VERSION ""

NS_ :

BS_:

BU_: PFAF_HS LVMPC_HS DCDC_HS AMP_HS VICM2_HS FICM_HS ARS_HS MCP_B_HS MCP_A_HS ICCM_OBD_HS SAS_HS ACCM_HS VLBS_HS EBCM_OBD_HS EDI_HS HPCC_HS VITM_OBD_HS PTAM_HS OBCM_HS VICM_HS HCP_HS FDCM_HS APPS_HS ICCM_HS EOCM_F_HS GPCM_HS FSCM_ITBC_HS SCM_HS ITBC_HS VCM_HS HMIM_HS FCP_HS VES_HS Dummy_HS MCP_C_HS RWS_HS ONSTAR_HS EPS_HS TestTool_HS MCP_HS BCP_HS ALC_HS AHL_AFL_HS SADS_HS EPB_HS FSCM_HS AFS_HS FCM_HS TCCM_HS RDCM_HS PTO_HS PCM_HS EBCM_HS ACC_HS BCM_HS TCM_HS ECM_HS

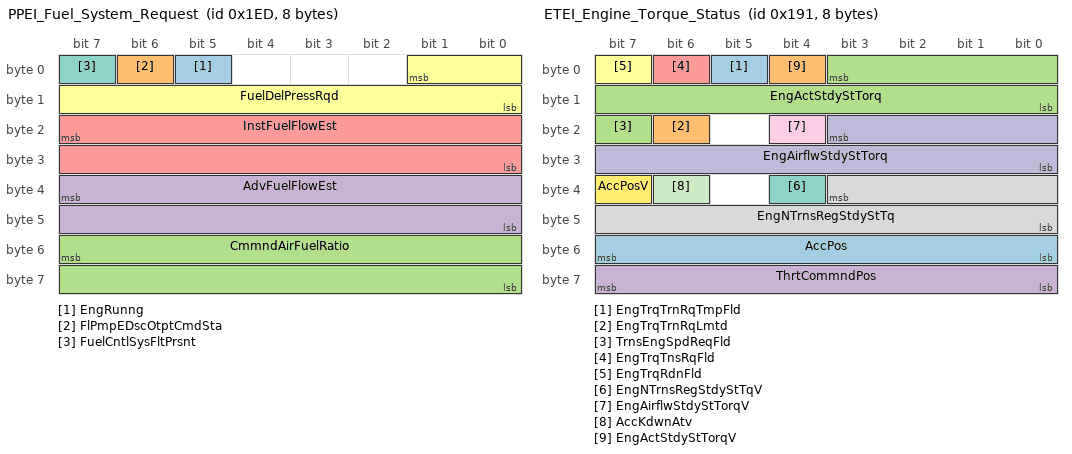
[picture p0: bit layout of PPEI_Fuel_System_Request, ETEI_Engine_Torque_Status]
BO_ 493 PPEI_Fuel_System_Request: 8 ECM_HS
 SG_ EngRunng : 5|1@0+ (1,0) [0|1] ""  PTO_HS,ICCM_OBD_HS,ICCM_HS,FSCM_ITBC_HS,FSCM_HS,AMP_HS
 SG_ FlPmpEDscOtptCmdSta : 6|1@0+ (1,0) [0|1] ""  FICM_HS,ICCM_OBD_HS,ICCM_HS,FSCM_ITBC_HS,FSCM_HS
 SG_ CmmndAirFuelRatio : 55|16@0+ (0.000488281,0) [0|31.999495335] ""  FICM_HS,ICCM_OBD_HS,ICCM_HS,FSCM_ITBC_HS,FSCM_HS
 SG_ AdvFuelFlowEst : 39|16@0+ (0.000976562,0) [0|63.99899067] "grams/s"  ICCM_OBD_HS,ICCM_HS,FSCM_ITBC_HS,FSCM_HS
 SG_ InstFuelFlowEst : 23|16@0+ (0.000976562,0) [0|63.99899067] "grams/s"  VICM_HS,FICM_HS,ICCM_OBD_HS,ICCM_HS,FSCM_ITBC_HS,FSCM_HS
 SG_ FuelDelPressRqd : 1|10@0+ (1,0) [0|1023] "kPa"  ICCM_OBD_HS,ICCM_HS,FSCM_ITBC_HS,FSCM_HS
 SG_ FuelCntlSysFltPrsnt : 7|1@0+ (1,0) [0|1] ""  FICM_HS,ICCM_OBD_HS,ICCM_HS,FSCM_ITBC_HS,FSCM_HS

BO_ 401 ETEI_Engine_Torque_Status: 8 ECM_HS
 SG_ EngTrqTrnRqTmpFld : 5|1@0+ (1,0) [0|1] ""  TCCM_HS,TCM_HS
 SG_ EngTrqTrnRqLmtd : 22|1@0+ (1,0) [0|1] ""  TCCM_HS,TCM_HS
 SG_ TrnsEngSpdReqFld : 23|1@0+ (1,0) [0|1] ""  TCCM_HS,TCM_HS
 SG_ ThrtCommndPos : 63|8@0+ (0.392157,0) [0|100.000035] "%"  TCCM_HS
 SG_ EngTrqTnsRqFld : 6|1@0+ (1,0) [0|1] ""  TCCM_HS,TCM_HS
 SG_ EngTrqRdnFld : 7|1@0+ (1,0) [0|1] ""  TCCM_HS,TCM_HS
 SG_ EngNTrnsRegStdyStTqV : 36|1@0+ (1,0) [0|1] ""  TCCM_HS,TCM_HS
 SG_ EngNTrnsRegStdyStTq : 35|12@0+ (0.5,-848) [-848|1199.5] "Nm"  TCCM_HS,TCM_HS
 SG_ EngAirflwStdyStTorqV : 20|1@0+ (1,0) [0|1] ""  TCCM_HS,TCM_HS
 SG_ EngAirflwStdyStTorq : 19|12@0+ (0.5,-848) [-848|1199.5] "Nm"  TCCM_HS,TCM_HS
 SG_ AccKdwnAtv : 38|1@0+ (1,0) [0|1] ""  TCCM_HS,TCM_HS
 SG_ AccPosV : 39|1@0+ (1,0) [0|1] ""  FSCM_HS,BCP_HS,FICM_HS,TCM_HS
 SG_ AccPos : 55|8@0+ (0.392157,0) [0|100.000035] "%"  FSCM_HS,BCP_HS,FICM_HS,TCM_HS
 SG_ EngActStdyStTorqV : 4|1@0+ (1,0) [0|1] ""  TCCM_HS,TCM_HS
 SG_ EngActStdyStTorq : 3|12@0+ (0.5,-848) [-848|1199.5] "Nm"  TCCM_HS,TCM_HS

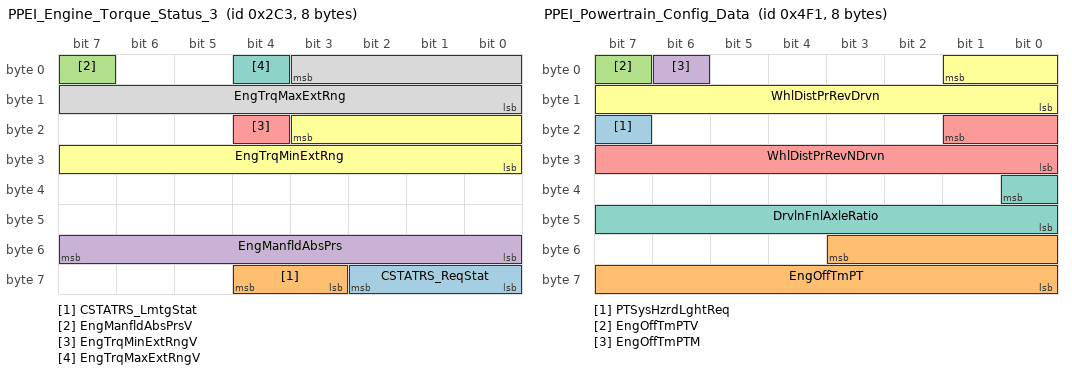
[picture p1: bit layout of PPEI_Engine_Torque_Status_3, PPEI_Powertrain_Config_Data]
BO_ 707 PPEI_Engine_Torque_Status_3: 8 ECM_HS
 SG_ CSTATRS_ReqStat : 58|3@0+ (1,0) [0|7] ""  EBCM_OBD_HS,EBCM_HS
 SG_ CSTATRS_LmtgStat : 60|2@0+ (1,0) [0|3] ""  EBCM_OBD_HS,EBCM_HS
 SG_ EngManfldAbsPrsV : 7|1@0+ (1,0) [0|1] ""  EDI_HS,AMP_HS,BCP_HS,EBCM_OBD_HS,EBCM_HS
 SG_ EngManfldAbsPrs : 55|8@0+ (0.5,0) [0|127.5] "kPa"  EDI_HS,AMP_HS,BCP_HS,EBCM_OBD_HS,EBCM_HS
 SG_ EngTrqMinExtRngV : 20|1@0+ (1,0) [0|1] ""  ACC_HS,EBCM_OBD_HS,EBCM_HS
 SG_ EngTrqMinExtRng : 19|12@0+ (0.5,-848) [-848|1199.5] "Nm"  ACC_HS,EBCM_OBD_HS,EBCM_HS
 SG_ EngTrqMaxExtRngV : 4|1@0+ (1,0) [0|1] ""  TCCM_HS,ACC_HS,EBCM_OBD_HS,EBCM_HS,RDCM_HS
 SG_ EngTrqMaxExtRng : 3|12@0+ (0.5,-848) [-848|1199.5] "Nm"  TCCM_HS,ACC_HS,RDCM_HS,EBCM_OBD_HS,EBCM_HS

BO_ 1265 PPEI_Powertrain_Config_Data: 8 ECM_HS
 SG_ PTSysHzrdLghtReq : 23|1@0+ (1,0) [0|1] ""  BCM_HS
 SG_ EngOffTmPT : 51|12@0+ (0.5,0) [0|2047.5] "min"  EBCM_OBD_HS,EBCM_HS,MCP_HS,TCM_HS
 SG_ EngOffTmPTV : 7|1@0+ (1,0) [0|1] ""  EBCM_OBD_HS,EBCM_HS,MCP_HS,TCM_HS
 SG_ EngOffTmPTM : 6|1@0+ (1,0) [0|1] ""  EBCM_OBD_HS,EBCM_HS,MCP_HS,TCM_HS
 SG_ WhlDistPrRevNDrvn : 17|10@0+ (3,800) [800|3869] "mm"  ICCM_OBD_HS,ICCM_HS,HMIM_HS,VES_HS,EPS_HS,FSCM_ITBC_HS,TCCM_HS,EPB_HS,EOCM_F_HS,EBCM_OBD_HS,EBCM_HS,RDCM_HS
 SG_ WhlDistPrRevDrvn : 1|10@0+ (3,800) [800|3869] "mm"  ICCM_OBD_HS,ICCM_HS,HMIM_HS,VES_HS,EPS_HS,EOCM_F_HS,FSCM_ITBC_HS,ACC_HS,TCCM_HS,EPB_HS,EBCM_OBD_HS,EBCM_HS,BCM_HS,RDCM_HS
 SG_ DrvlnFnlAxleRatio : 32|9@0+ (0.01,2) [2|7.11] ""  PTAM_HS,TCCM_HS,BCM_HS,EBCM_OBD_HS,EBCM_HS

BO_ 417 ETEI_Engine_General_Status: 7 ECM_HS
 SG_ EngCrsCntrlMode : 29|3@0+ (1,0) [0|7] ""  TCM_HS
 SG_ EngPstOxgSnsDgAstRq : 31|1@0+ (1,0) [0|1] ""  TCM_HS
 SG_ CrsCtrlCnstSpdAct : 26|1@0+ (1,0) [0|1] ""  TCM_HS
 SG_ WrmUpShftPtrnRq : 25|1@0+ (1,0) [0|1] ""  TCM_HS
 SG_ EngIdlSpdRdcdRng : 39|8@0+ (8,0) [0|2040] "rpm"  BCP_HS,TCM_HS
 SG_ EngAlwCltAdp : 24|1@0+ (1,0) [0|1] ""  TCM_HS
 SG_ BsTrgtEngIdlSpd : 47|8@0+ (8,0) [0|2040] "rpm"  TCM_HS
 SG_ AccPdlPosPcntFullRngV : 17|1@0+ (1,0) [0|1] ""  TCM_HS
 SG_ AccPdlPosPcntFullRng : 55|8@0+ (0.392157,0) [0|100.000035] "%"  TCM_HS
 SG_ DslPrtFltrIdlRgtnMdReq : 20|1@0+ (1,0) [0|1] ""  TCM_HS
 SG_ DslPartFltrClngAlgActM : 18|1@0+ (1,0) [0|1] ""  TCM_HS
 SG_ DslPartFltrClngAlgAct : 19|1@0+ (1,0) [0|1] ""  TCM_HS
 SG_ EngCylDeactMd : 9|2@0+ (1,0) [0|3] ""  BCP_HS
 SG_ ACCmCltEngd : 13|1@0+ (1,0) [0|1] ""  TCM_HS
 SG_ ParkNeutralSwStatV : 21|1@0+ (1,0) [0|1] ""  TCM_HS
 SG_ ParkNeutralSwStat : 22|1@0+ (1,0) [0|1] ""  TCM_HS
 SG_ EngColdHiIdleActive : 23|1@0+ (1,0) [0|1] ""  TCM_HS
 SG_ EngCyDactTqSmtAct : 6|1@0+ (1,0) [0|1] ""  TCM_HS
 SG_ EngBrkStat : 15|2@0+ (1,0) [0|3] ""  TCM_HS
 SG_ TracCntlSysPwrtrnInhbt : 12|1@0+ (1,0) [0|1] ""  TCM_HS
 SG_ EngMtlProtAtv : 11|1@0+ (1,0) [0|1] ""  TCM_HS
 SG_ EngDgTrqCnvClUnlkRqd : 7|1@0+ (1,0) [0|1] ""  TCM_HS
 SG_ EngCyldrDeactReqd : 10|1@0+ (1,0) [0|1] ""  TCM_HS
 SG_ ETGRReqdGear : 3|4@0+ (1,0) [0|15] ""  TCM_HS
 SG_ ETGRReqType : 5|2@0+ (1,0) [0|3] ""  TCM_HS

BO_ 1233 PPEI_Engine_General_Status_5: 8 ECM_HS
 SG_ EngShtdwnAct : 48|1@0+ (1,0) [0|1] "" Vector__XXX
 SG_ EngShtdwnPndgIO : 49|1@0+ (1,0) [0|1] ""  FCP_HS,ONSTAR_HS,BCM_HS
 SG_ FuelFltChgNwIO : 51|1@0+ (1,0) [0|1] ""  FCP_HS,ONSTAR_HS,BCM_HS
 SG_ PTExPrtclFltrWrn2IO : 50|1@0+ (1,0) [0|1] ""  PTO_HS,FCP_HS,ONSTAR_HS,BCM_HS
 SG_ PTHiElecLdReqd : 52|1@0+ (1,0) [0|1] ""  BCM_HS
 SG_ PTExPrtclFltrWrnIO : 53|1@0+ (1,0) [0|1] ""  PTO_HS,FCP_HS,ONSTAR_HS,BCM_HS
 SG_ AirCndOffIO : 0|1@0+ (1,0) [0|1] ""  BCM_HS
 SG_ DslGlwPlgIO : 55|1@0+ (1,0) [0|1] ""  BCM_HS
 SG_ StgDisIO : 30|1@0+ (1,0) [0|1] ""  BCM_HS
 SG_ RdcdPwrIO : 31|1@0+ (1,0) [0|1] ""  FCP_HS,ONSTAR_HS,BCM_HS
 SG_ FuelTotCap : 27|12@0+ (0.125,0) [0|511.875] "liters"  EDI_HS,LVMPC_HS,BCM_HS
 SG_ FlLvlPctV : 28|1@0+ (1,0) [0|1] ""  EDI_HS,LVMPC_HS,AHL_AFL_HS,PTO_HS,FICM_HS,BCM_HS
 SG_ FlLvlPct : 47|8@0+ (0.392157,0) [0|100.000035] "%"  EDI_HS,LVMPC_HS,PTO_HS,AHL_AFL_HS,FICM_HS,BCM_HS
 SG_ EngWtrInFlIO : 54|1@0+ (1,0) [0|1] ""  FCP_HS,ONSTAR_HS,BCM_HS
 SG_ EngOilTmpV : 7|1@0+ (1,0) [0|1] ""  EDI_HS,LVMPC_HS,EPS_HS,BCM_HS
 SG_ EngOilTmp : 15|8@0+ (1,-40) [-40|215] "deg C"  EDI_HS,LVMPC_HS,EPS_HS,BCM_HS
 SG_ EngOilPrsV : 6|1@0+ (1,0) [0|1] ""  EDI_HS,LVMPC_HS,PTO_HS,BCM_HS
 SG_ EngOilPrsLwIO : 5|1@0+ (1,0) [0|1] ""  PTO_HS,FCP_HS,ONSTAR_HS,BCM_HS
 SG_ EngOilPrs : 23|8@0+ (4,0) [0|1020] "kPa"  EDI_HS,LVMPC_HS,PTO_HS,BCM_HS
 SG_ EngOilLvlLwIO : 4|1@0+ (1,0) [0|1] ""  PTO_HS,FCP_HS,ONSTAR_HS,BCM_HS
 SG_ EngOilChngIO : 3|1@0+ (1,0) [0|1] ""  BCM_HS
 SG_ EngHt_StpEngIO : 1|1@0+ (1,0) [0|1] ""  PTO_HS,FCP_HS,ONSTAR_HS,BCM_HS
 SG_ EngHotFuelEnrchmntIO : 2|1@0+ (1,0) [0|1] ""  FCP_HS,ONSTAR_HS,BCM_HS
 SG_ CkFlFilrCapIO : 29|1@0+ (1,0) [0|1] ""  BCM_HS

BO_ 1217 PPEI_Engine_General_Status_4: 8 ECM_HS
 SG_ LegPstDTCClrDrvCyCm : 40|1@0+ (1,0) [0|1] ""  VICM2_HS,EBCM_OBD_HS,EBCM_HS,VICM_HS,OBCM_HS,VITM_OBD_HS,BCP_HS,ICCM_OBD_HS,ICCM_HS,FSCM_ITBC_HS,FSCM_HS,TCM_HS
 SG_ LegDiagColdStCndMet : 47|1@0+ (1,0) [0|1] ""  VICM2_HS,FICM_HS,ICCM_OBD_HS,ICCM_HS,FSCM_ITBC_HS,FSCM_HS,MCP_HS,EBCM_OBD_HS,EBCM_HS,OBCM_HS,BCP_HS,TCCM_HS,VITM_OBD_HS,VICM_HS,TCM_HS
 SG_ LegDiagColdStCndFltPr : 46|1@0+ (1,0) [0|1] ""  VICM2_HS,FICM_HS,ICCM_OBD_HS,ICCM_HS,FSCM_ITBC_HS,FSCM_HS,MCP_HS,EBCM_OBD_HS,EBCM_HS,OBCM_HS,TCCM_HS,VITM_OBD_HS,VICM_HS,TCM_HS,BCP_HS
 SG_ EngEconMdCmnd : 44|1@0+ (1,0) [0|1] ""  TCM_HS
 SG_ DslExhFldRmngDstHRsV : 41|1@0+ (1,0) [0|1] ""  BCM_HS,FCP_HS,ONSTAR_HS
 SG_ DslExhFldRmngDstHRs : 54|15@0+ (2,0) [0|65534] "km"  BCM_HS,FCP_HS,ONSTAR_HS
 SG_ EngOilHotIO : 45|1@0+ (1,0) [0|1] ""  BCM_HS
 SG_ OAT_PT_EstV : 3|1@0+ (1,0) [0|1] ""  FICM_HS,TCM_HS,TCCM_HS,AHL_AFL_HS,HCP_HS,BCP_HS,RDCM_HS,BCM_HS,EBCM_OBD_HS,EBCM_HS
 SG_ LegDiagStndCndMet : 2|1@0+ (1,0) [0|1] ""  VICM2_HS,FICM_HS,MCP_HS,EBCM_OBD_HS,EBCM_HS,OBCM_HS,VITM_OBD_HS,VICM_HS,BCP_HS,FCP_HS,ONSTAR_HS,ICCM_OBD_HS,ICCM_HS,FSCM_ITBC_HS,FSCM_HS,TCM_HS,TCCM_HS
 SG_ LegDiagStndCndFltPr : 1|1@0+ (1,0) [0|1] ""  VICM2_HS,FICM_HS,MCP_HS,EBCM_OBD_HS,EBCM_HS,VITM_OBD_HS,VICM_HS,OBCM_HS,BCP_HS,ICCM_OBD_HS,ICCM_HS,FSCM_ITBC_HS,FSCM_HS,TCM_HS,TCCM_HS
 SG_ OAT_PT_EstM : 4|1@0+ (1,0) [0|1] ""  FICM_HS,HCP_HS,TCM_HS,TCCM_HS,AHL_AFL_HS,BCP_HS,RDCM_HS,BCM_HS,EBCM_OBD_HS,EBCM_HS
 SG_ OAT_PT_Est : 39|8@0+ (0.5,-40) [-40|87.5] "deg C"  FICM_HS,TCM_HS,TCCM_HS,AHL_AFL_HS,HCP_HS,BCP_HS,RDCM_HS,BCM_HS,EBCM_OBD_HS,EBCM_HS
 SG_ EngWrmUpAch : 0|1@0+ (1,0) [0|1] ""  FICM_HS,MCP_HS,VITM_OBD_HS,EBCM_OBD_HS,EBCM_HS,VICM_HS,OBCM_HS,BCP_HS,ICCM_OBD_HS,ICCM_HS,FSCM_ITBC_HS,FSCM_HS,TCM_HS,TCCM_HS
 SG_ EngIntAirTmpV : 5|1@0+ (1,0) [0|1] ""  EDI_HS,ICCM_OBD_HS,ICCM_HS,RDCM_HS,VICM2_HS,FICM_HS,VICM_HS,EBCM_OBD_HS,EBCM_HS,FCP_HS,ONSTAR_HS,SADS_HS,BCP_HS,TCCM_HS,HCP_HS,BCM_HS
 SG_ EngIntAirTmp : 31|8@0+ (1,-40) [-40|215] "deg C"  EDI_HS,ICCM_OBD_HS,ICCM_HS,RDCM_HS,VICM2_HS,FICM_HS,VICM_HS,EBCM_OBD_HS,EBCM_HS,FCP_HS,ONSTAR_HS,SADS_HS,BCP_HS,TCCM_HS,HCP_HS,BCM_HS
 SG_ EngCltTmpV : 6|1@0+ (1,0) [0|1] ""  EDI_HS,LVMPC_HS,EPS_HS,VCM_HS,FICM_HS,ICCM_OBD_HS,ICCM_HS,FSCM_HS,VICM_HS,FCP_HS,ONSTAR_HS,SADS_HS,HCP_HS,BCP_HS,VICM2_HS,BCM_HS,EBCM_OBD_HS,EBCM_HS
 SG_ EngCltTmp : 23|8@0+ (1,-40) [-40|215] "deg C"  EDI_HS,LVMPC_HS,EPS_HS,VCM_HS,FICM_HS,ICCM_OBD_HS,ICCM_HS,FSCM_HS,VICM_HS,FCP_HS,ONSTAR_HS,SADS_HS,HCP_HS,BCP_HS,VICM2_HS,BCM_HS,EBCM_OBD_HS,EBCM_HS
 SG_ BarPrsAbsV : 7|1@0+ (1,0) [0|1] ""  EDI_HS,VICM_HS,FICM_HS,EBCM_OBD_HS,EBCM_HS,BCP_HS,HCP_HS,ICCM_OBD_HS,ICCM_HS,FSCM_ITBC_HS,FSCM_HS,BCM_HS
 SG_ BarPrsAbs : 15|8@0+ (0.5,0) [0|127.5] "kPa"  EDI_HS,VICM_HS,FICM_HS,EBCM_OBD_HS,EBCM_HS,BCP_HS,HCP_HS,ICCM_OBD_HS,ICCM_HS,FSCM_ITBC_HS,FSCM_HS,BCM_HS

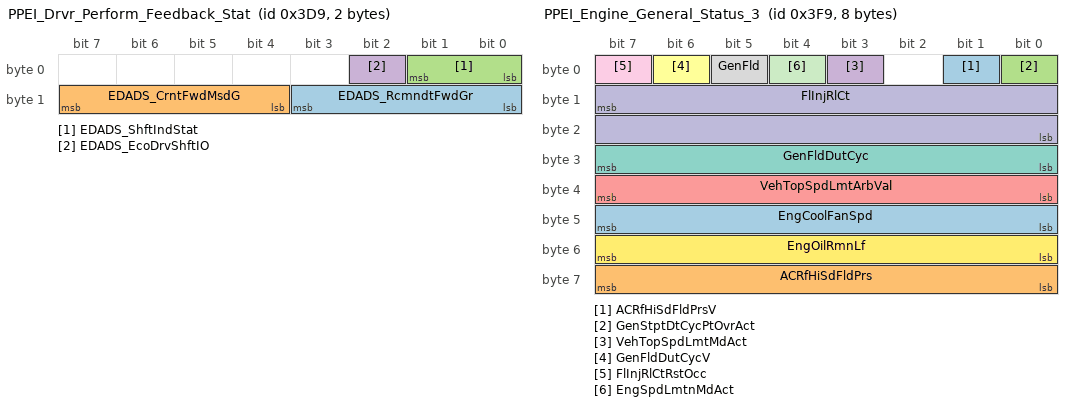
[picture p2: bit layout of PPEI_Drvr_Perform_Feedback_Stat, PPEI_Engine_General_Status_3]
BO_ 985 PPEI_Drvr_Perform_Feedback_Stat: 2 ECM_HS
 SG_ EDADS_RcmndtFwdGr : 11|4@0+ (1,0) [0|15] ""  BCM_HS
 SG_ EDADS_CrntFwdMsdG : 15|4@0+ (1,0) [0|15] ""  BCM_HS
 SG_ EDADS_ShftIndStat : 1|2@0+ (1,0) [0|3] ""  BCM_HS
 SG_ EDADS_EcoDrvShftIO : 2|1@0+ (1,0) [0|1] ""  BCM_HS

BO_ 1017 PPEI_Engine_General_Status_3: 8 ECM_HS
 SG_ ACRfHiSdFldPrsV : 1|1@0+ (1,0) [0|1] ""  VICM2_HS,ICCM_OBD_HS,ICCM_HS,FSCM_HS,VICM_HS,FCP_HS,ONSTAR_HS,BCM_HS
 SG_ ACRfHiSdFldPrs : 63|8@0+ (14,0) [0|3570] "kPaG"  VICM2_HS,ICCM_OBD_HS,ICCM_HS,FSCM_HS,VICM_HS,FCP_HS,ONSTAR_HS,BCM_HS
 SG_ GenStptDtCycPtOvrAct : 0|1@0+ (1,0) [0|1] ""  BCM_HS
 SG_ VehTopSpdLmtMdAct : 3|1@0+ (1,0) [0|1] ""  PTO_HS,BCM_HS
 SG_ VehTopSpdLmtArbVal : 39|8@0+ (2,0) [0|510] "km / h"  PTO_HS,BCM_HS
 SG_ GenFldDutCycV : 6|1@0+ (1,0) [0|1] ""  BCM_HS
 SG_ GenFldDutCyc : 31|8@0+ (0.392157,0) [0|100.000035] "%"  BCM_HS
 SG_ GenFld : 5|1@0+ (1,0) [0|1] ""  FCP_HS,ONSTAR_HS,AFS_HS,BCM_HS
 SG_ FlInjRlCtRstOcc : 7|1@0+ (1,0) [0|1] ""  VICM_HS,FCP_HS,ONSTAR_HS,BCM_HS
 SG_ FlInjRlCt : 15|16@0+ (3.05176E-005,0) [0|1.999970916] "liters"  VICM_HS,FCP_HS,ONSTAR_HS,BCM_HS
 SG_ EngSpdLmtnMdAct : 4|1@0+ (1,0) [0|1] ""  BCM_HS
 SG_ EngOilRmnLf : 55|8@0+ (0.392157,0) [0|100.000035] "%"  BCM_HS
 SG_ EngCoolFanSpd : 47|8@0+ (0.392157,0) [0|100.000035] "%"  VICM_HS,VICM2_HS,ICCM_OBD_HS,ICCM_HS,FSCM_HS,BCM_HS

BO_ 977 PPEI_Engine_General_Status_2: 8 ECM_HS
 SG_ AutoMdSpdLmtStat : 6|2@0+ (1,0) [0|3] ""  BCM_HS
 SG_ FuelFltLifRstPerf : 38|1@0+ (1,0) [0|1] ""  FCP_HS,ONSTAR_HS,BCM_HS
 SG_ SpdLmtrSpdWrngAct : 4|1@0+ (1,0) [0|1] ""  TCM_HS,BCM_HS
 SG_ CrsCntlDrSelSpdAct : 39|1@0+ (1,0) [0|1] ""  BCM_HS
 SG_ ACCmpNrmLdGrdAld : 63|8@0+ (0.1,0) [0|25.5] "dm3/m/s"  BCM_HS
 SG_ ACCompCmnd : 37|1@0+ (1,0) [0|1] ""  VICM2_HS,ICCM_OBD_HS,ICCM_HS,FSCM_HS,BCM_HS
 SG_ EngBstPrsIndV : 23|1@0+ (1,0) [0|1] ""  LVMPC_HS,BCM_HS
 SG_ EngBstPrsInd : 55|8@0+ (0.392157,0) [0|100.000035] "%"  LVMPC_HS,BCM_HS
 SG_ EngOilLifRstPerf : 36|1@0+ (1,0) [0|1] ""  BCM_HS
 SG_ ThrPosV : 7|1@0+ (1,0) [0|1] ""  EDI_HS,ACC_HS,EOCM_F_HS,SADS_HS,BCM_HS
 SG_ ThrPos : 15|8@0+ (0.392157,0) [0|100.000035] "%"  EDI_HS,ACC_HS,EOCM_F_HS,SADS_HS,BCM_HS
 SG_ InstFuelConsmpRate : 35|12@0+ (0.025,0) [0|102.375] "ltrs/hr"  EDI_HS,BCM_HS
 SG_ EngOilStrvtnIO : 21|1@0+ (1,0) [0|1] ""  BCM_HS
 SG_ EngNEmsnsRelMalfAct : 3|1@0+ (1,0) [0|1] ""  BCM_HS
 SG_ EngEmsRelMalfIndReq : 2|3@0+ (1,0) [0|7] ""  BCM_HS
 SG_ EngCstFlCutAct : 22|1@0+ (1,0) [0|1] ""  TCM_HS,VICM_HS,BCP_HS,BCM_HS
 SG_ CrsSpdLmtrDrvSelSpd : 19|12@0+ (0.0625,0) [0|255.9375] "km / h"  TCM_HS,BCM_HS

BO_ 201 PPEI_Engine_General_Status_1: 8 ECM_HS
 SG_ PrsElvtdIdlCntlStat : 49|1@0+ (1,0) [0|1] ""  BCM_HS
 SG_ Eng12vStrtrMtrCmmdOn : 53|1@0+ (1,0) [0|1] ""  BCM_HS,DCDC_HS,RDCM_HS,MCP_C_HS,FICM_HS,TCM_HS,HCP_HS,BCP_HS,MCP_B_HS,MCP_A_HS,EPB_HS,EBCM_OBD_HS,EBCM_HS,TCCM_HS,VES_HS,EPS_HS
 SG_ EngCntrlRunCrnkTrmSt : 52|1@0+ (1,0) [0|1] ""  MCP_C_HS,TCM_HS,EBCM_OBD_HS,EBCM_HS,MCP_B_HS,MCP_A_HS,HCP_HS,BCP_HS,VITM_OBD_HS,VICM_HS,OBCM_HS,FSCM_ITBC_HS,ACCM_HS,VICM2_HS,FSCM_HS,ICCM_OBD_HS,ICCM_HS,FICM_HS
 SG_ EngAirIntBstPrV : 51|1@0+ (1,0) [0|1] ""  EDI_HS,LVMPC_HS,FICM_HS,BCM_HS
 SG_ EngAirIntBstPr : 63|8@0- (1,0) [-128|127] "kPaG"  EDI_HS,LVMPC_HS,FICM_HS,BCM_HS
 SG_ SpdLmtrSpdWrngEnbld : 47|1@0+ (1,0) [0|1] ""  PTO_HS,BCM_HS
 SG_ EngCylDactEvntPndg : 54|1@0+ (1,0) [0|1] ""  ICCM_OBD_HS,ICCM_HS,FSCM_ITBC_HS,FSCM_HS,AMP_HS
 SG_ EngCylDeactMd : 43|2@0+ (1,0) [0|3] ""  FSCM_ITBC_HS,FSCM_HS,ICCM_OBD_HS,ICCM_HS,AMP_HS,BCM_HS
 SG_ RmVhStrtEngRng : 55|1@0+ (1,0) [0|1] ""  EBCM_OBD_HS,EBCM_HS,TCCM_HS,BCP_HS,HCP_HS,EPB_HS,BCM_HS
 SG_ PFEngSpdCmndSpcd : 45|1@0+ (1,0) [0|1] ""  BCM_HS,PTO_HS
 SG_ DrThrtlOvrrdDetProtVal : 25|2@0+ (1,0) [0|3] ""  ACC_HS,EBCM_OBD_HS,EBCM_HS
 SG_ DrThrtlOvrdDetAlvRlCnt : 27|2@0+ (1,0) [0|3] ""  EBCM_OBD_HS,EBCM_HS,ACC_HS
 SG_ PltfrmEngSpdCmdInhtRq : 44|1@0+ (1,0) [0|1] ""  BCM_HS,PTO_HS
 SG_ PT_BrkPedDscrtInpStatV : 41|1@0+ (1,0) [0|1] ""  TCCM_HS,BCP_HS,PTO_HS,ACC_HS,EBCM_OBD_HS,EBCM_HS
 SG_ PT_BrkPedDscrtInpStat : 40|1@0+ (1,0) [0|1] ""  TCCM_HS,BCP_HS,PTO_HS,ACC_HS,EBCM_OBD_HS,EBCM_HS
 SG_ AccActPos : 39|8@0+ (0.392157,0) [0|100.000035] "%"  LVMPC_HS,EDI_HS,ICCM_OBD_HS,ICCM_HS,VICM_HS,PTAM_HS,HCP_HS,EBCM_OBD_HS,EBCM_HS,BCP_HS,AHL_AFL_HS,AFS_HS,EPB_HS,SADS_HS,RDCM_HS,BCM_HS,TCM_HS,TCCM_HS
 SG_ CrsCntEnbld : 29|1@0+ (1,0) [0|1] ""  PTO_HS,ACC_HS,EOCM_F_HS,BCM_HS
 SG_ CrsCntAtv : 30|1@0+ (1,0) [0|1] ""  EBCM_OBD_HS,EBCM_HS,RDCM_HS,PTO_HS,BCP_HS,EPB_HS,BCM_HS,TCM_HS
 SG_ DrvThrottlOvrrdDet : 28|1@0+ (1,0) [0|1] ""  PTO_HS,ACC_HS,EBCM_OBD_HS,EBCM_HS,BCM_HS
 SG_ PT_CrnkAct : 6|1@0+ (1,0) [0|1] ""  VCM_HS,FICM_HS,VES_HS,EPS_HS,EBCM_OBD_HS,EBCM_HS,HCP_HS,PTO_HS,BCP_HS,ICCM_OBD_HS,ICCM_HS,FSCM_ITBC_HS,FSCM_HS
 SG_ PTRunAbrt : 4|1@0+ (1,0) [0|1] ""  BCP_HS,BCM_HS
 SG_ PTO_PT_RunAbrtd : 3|1@0+ (1,0) [0|1] ""  PTO_HS,BCM_HS
 SG_ PTCrnkAbrted : 5|1@0+ (1,0) [0|1] ""  BCP_HS,PTO_HS,BCM_HS
 SG_ EngSpdStat : 1|2@0+ (1,0) [0|3] ""  PFAF_HS,PTO_HS,AHL_AFL_HS,VICM2_HS,FICM_HS,AMP_HS,VICM_HS,VES_HS,EPS_HS,PTAM_HS,TCCM_HS,BCP_HS,ICCM_OBD_HS,ICCM_HS,FSCM_ITBC_HS,FSCM_HS,RDCM_HS,EBCM_OBD_HS,EBCM_HS,EPB_HS,ACC_HS,BCM_HS,SADS_HS
 SG_ EngSpd : 15|16@0+ (0.25,0) [0|16383.75] "rpm"  PFAF_HS,EDI_HS,LVMPC_HS,DCDC_HS,PTO_HS,AHL_AFL_HS,VICM2_HS,EOCM_F_HS,FICM_HS,AMP_HS,FCP_HS,ONSTAR_HS,VICM_HS,PTAM_HS,VES_HS,EPS_HS,TCCM_HS,HCP_HS,BCP_HS,ICCM_OBD_HS,ICCM_HS,FSCM_ITBC_HS,FSCM_HS,EPB_HS,RDCM_HS,AFS_HS,EBCM_OBD_HS,EBCM_HS,ACC_HS,BCM_HS,SADS_HS
 SG_ EngRunAtv : 7|1@0+ (1,0) [0|1] ""  DCDC_HS,VCM_HS,RDCM_HS,ARS_HS,AMP_HS,VICM2_HS,ACC_HS,VICM_HS,APPS_HS,EOCM_F_HS,BCP_HS,FCP_HS,ONSTAR_HS,FSCM_ITBC_HS,FSCM_HS,ICCM_OBD_HS,ICCM_HS,ALC_HS,VES_HS,EPS_HS,EBCM_OBD_HS,EBCM_HS,AHL_AFL_HS,EPB_HS,SADS_HS,AFS_HS,BCM_HS,TCCM_HS
 SG_ EngIdlAtv : 2|1@0+ (1,0) [0|1] ""  PTO_HS,FICM_HS,AMP_HS,EPB_HS,BCM_HS
 SG_ AccActPosV : 31|1@0+ (1,0) [0|1] ""  LVMPC_HS,EDI_HS,ICCM_OBD_HS,ICCM_HS,VICM_HS,PTAM_HS,HCP_HS,EBCM_OBD_HS,EBCM_HS,BCP_HS,AHL_AFL_HS,EPB_HS,AFS_HS,SADS_HS,BCM_HS,RDCM_HS,TCM_HS,TCCM_HS

BO_ 501 PPEI_Trans_General_Status_2: 8 ECM_HS
 SG_ EngRecDwnshftIO : 54|1@0+ (1,0) [0|1] ""  BCM_HS
 SG_ TrnsPattSelEcnMdOCm : 52|1@0+ (1,0) [0|1] ""  ICCM_OBD_HS,ICCM_HS,PCM_HS,ECM_HS
 SG_ CltStartSwAtvV : 38|1@0+ (1,0) [0|1] ""  TCCM_HS,PTAM_HS,RDCM_HS,BCM_HS
 SG_ CltStartSwAtv : 37|1@0+ (1,0) [0|1] ""  TCCM_HS,PTAM_HS,BCM_HS,RDCM_HS
 SG_ CltchPdlActPosV : 55|1@0+ (1,0) [0|1] ""  TCCM_HS,LVMPC_HS,EDI_HS,EBCM_OBD_HS,EBCM_HS,ICCM_OBD_HS,ICCM_HS,ECM_HS,PTAM_HS,EPB_HS,RDCM_HS
 SG_ CltchPdlActPos : 63|8@0+ (0.392157,0) [0|100.000035] "%"  TCCM_HS,LVMPC_HS,EDI_HS,EBCM_OBD_HS,EBCM_HS,ICCM_OBD_HS,ICCM_HS,ECM_HS,PTAM_HS,EPB_HS,RDCM_HS
 SG_ TrnsEngdStateV : 50|1@0+ (1,0) [0|1] ""  ICCM_OBD_HS,ICCM_HS,BCP_HS,ACC_HS,EBCM_OBD_HS,EBCM_HS,EPB_HS,SADS_HS,RDCM_HS,AFS_HS,AHL_AFL_HS,BCM_HS
 SG_ TrnsEngdState : 49|2@0+ (1,0) [0|3] ""  ICCM_OBD_HS,ICCM_HS,BCP_HS,ACC_HS,EBCM_OBD_HS,EBCM_HS,EPB_HS,SADS_HS,RDCM_HS,AFS_HS,AHL_AFL_HS,BCM_HS
 SG_ TrnsShftLvrLckRqd : 47|1@0+ (1,0) [0|1] ""  ICCM_OBD_HS,ICCM_HS,BCM_HS
 SG_ TransTUDMdStat : 41|2@0+ (1,0) [0|3] ""  ICCM_OBD_HS,ICCM_HS,EBCM_OBD_HS,EBCM_HS,BCP_HS,ACC_HS,EOCM_F_HS,BCM_HS,PCM_HS,ECM_HS
 SG_ TrnCrpMdAtv : 46|1@0+ (1,0) [0|1] ""  ICCM_OBD_HS,ICCM_HS,PCM_HS,ECM_HS,BCM_HS
 SG_ TrnsSkpShftIO : 23|1@0+ (1,0) [0|1] ""  ICCM_OBD_HS,ICCM_HS,BCM_HS
 SG_ TrnsSftMdStat : 34|3@0+ (1,0) [0|7] ""  ICCM_OBD_HS,ICCM_HS,EBCM_OBD_HS,EBCM_HS,BCM_HS
 SG_ TrnsRngInhbtStat : 31|3@0+ (1,0) [0|7] ""  ICCM_OBD_HS,ICCM_HS,BCM_HS
 SG_ TopTrvlCltchSwActV : 15|1@0+ (1,0) [0|1] ""  PTO_HS,PTAM_HS,RDCM_HS,BCM_HS,ACC_HS,EBCM_OBD_HS,EBCM_HS,EPB_HS
 SG_ TopTrvlCltchSwAct : 14|1@0+ (1,0) [0|1] ""  PTO_HS,PTAM_HS,RDCM_HS,BCM_HS,EPB_HS,ACC_HS,EBCM_OBD_HS,EBCM_HS
 SG_ EngRecmndUpshftIO : 22|1@0+ (1,0) [0|1] ""  BCM_HS
 SG_ DrvtShftCntrlTrgtGear : 19|4@0+ (1,0) [0|15] ""  ICCM_OBD_HS,ICCM_HS,BCM_HS
 SG_ DrShftCntrlReqDndIO : 21|1@0+ (1,0) [0|1] ""  ICCM_OBD_HS,ICCM_HS,BCM_HS
 SG_ TrnShftPtrnActStat : 44|3@0+ (1,0) [0|7] ""  ICCM_OBD_HS,ICCM_HS,ALC_HS,ARS_HS,AHL_AFL_HS,VES_HS,EPS_HS,SADS_HS,BCM_HS,EBCM_OBD_HS,EBCM_HS
 SG_ TrnsFldPrsPrsnt : 51|1@0+ (1,0) [0|1] ""  PCM_HS,ECM_HS
 SG_ TrnsShftLvrPos : 27|4@0+ (1,0) [0|15] ""  EPS_HS,PTO_HS,ICCM_OBD_HS,ICCM_HS,HMIM_HS,EOCM_F_HS,VICM_HS,HCP_HS,BCP_HS,EPB_HS,BCM_HS,EBCM_OBD_HS,EBCM_HS,PCM_HS,ECM_HS
 SG_ TrnsShftLvrPosV : 28|1@0+ (1,0) [0|1] ""  EPS_HS,PTO_HS,ICCM_OBD_HS,ICCM_HS,HMIM_HS,EOCM_F_HS,VICM_HS,HCP_HS,BCP_HS,EPB_HS,BCM_HS,EBCM_OBD_HS,EBCM_HS,PCM_HS,ECM_HS
 SG_ TrnsTrqCnvCltCmndMd : 7|3@0+ (1,0) [0|7] ""  PTO_HS,BCP_HS,PCM_HS,ECM_HS
 SG_ AutoTransComndGear : 11|4@0+ (1,0) [0|15] ""  ICCM_OBD_HS,ICCM_HS,TCCM_HS,EOCM_F_HS,RDCM_HS,BCP_HS,EBCM_OBD_HS,EBCM_HS,ACC_HS,BCM_HS,SADS_HS,PCM_HS,ECM_HS
 SG_ AutoTransGrSftDirect : 13|2@0+ (1,0) [0|3] ""  ICCM_OBD_HS,ICCM_HS,EOCM_F_HS,ACC_HS,BCP_HS,RDCM_HS,EBCM_OBD_HS,EBCM_HS,SADS_HS,PCM_HS,ECM_HS
 SG_ TransEstGear : 3|4@0+ (1,0) [0|15] ""  PFAF_HS,PTO_HS,LVMPC_HS,EDI_HS,HMIM_HS,FSCM_HS,ARS_HS,BCP_HS,PTAM_HS,EOCM_F_HS,VES_HS,ICCM_OBD_HS,ICCM_HS,ALC_HS,SADS_HS,FCP_HS,ONSTAR_HS,RDCM_HS,AFS_HS,EBCM_OBD_HS,EBCM_HS,EPB_HS,EPS_HS,ACC_HS,BCM_HS,TCCM_HS,PCM_HS,ECM_HS
 SG_ TransEstGearV : 4|1@0+ (1,0) [0|1] ""  PFAF_HS,PTO_HS,LVMPC_HS,EDI_HS,HMIM_HS,FSCM_HS,ARS_HS,BCP_HS,PTAM_HS,EOCM_F_HS,ICCM_OBD_HS,ICCM_HS,ALC_HS,VES_HS,EPS_HS,SADS_HS,RDCM_HS,AFS_HS,FCP_HS,ONSTAR_HS,EBCM_OBD_HS,EBCM_HS,EPB_HS,ACC_HS,BCM_HS,TCCM_HS,PCM_HS,ECM_HS

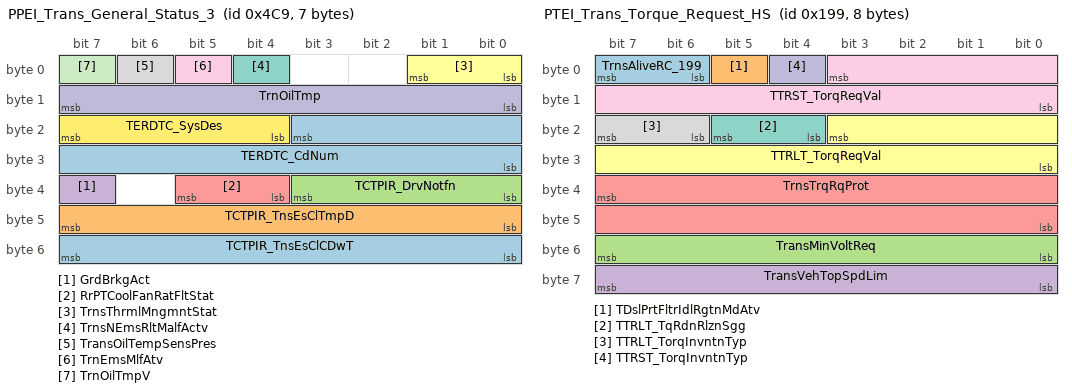
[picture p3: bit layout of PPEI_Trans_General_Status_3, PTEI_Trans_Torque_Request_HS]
BO_ 1225 PPEI_Trans_General_Status_3: 7 ECM_HS
 SG_ TCTPIR_TnsEsClCDwT : 55|8@0+ (0.392157,0) [0|100.000035] "%"  BCM_HS
 SG_ TCTPIR_TnsEsClTmpD : 47|8@0+ (0.392157,0) [0|100.000035] "%"  BCM_HS
 SG_ TCTPIR_DrvNotfn : 35|4@0+ (1,0) [0|15] ""  BCM_HS
 SG_ GrdBrkgAct : 39|1@0+ (1,0) [0|1] ""  BCM_HS
 SG_ RrPTCoolFanRatFltStat : 37|2@0+ (1,0) [0|4] ""  ICCM_OBD_HS,ICCM_HS
 SG_ TrnsThrmlMngmntStat : 1|2@0+ (1,0) [0|3] ""  PTO_HS,BCM_HS
 SG_ TrnsNEmsRltMalfActv : 4|1@0+ (1,0) [0|1] ""  FCP_HS,ONSTAR_HS,BCM_HS
 SG_ TransOilTempSensPres : 6|1@0+ (1,0) [0|1] ""  VICM_HS,FCP_HS,ONSTAR_HS,TCCM_HS,BCM_HS
 SG_ TrnEmsMlfAtv : 5|1@0+ (1,0) [0|1] ""  BCM_HS,PCM_HS,ECM_HS
 SG_ TrnOilTmp : 15|8@0+ (1,-40) [-40|215] "deg C"  LVMPC_HS,EDI_HS,VCM_HS,VICM2_HS,VICM_HS,MCP_A_HS,MCP_B_HS,FCP_HS,ONSTAR_HS,TCCM_HS,HCP_HS,BCP_HS,BCM_HS,PCM_HS,ECM_HS
 SG_ TrnOilTmpV : 7|1@0+ (1,0) [0|1] ""  LVMPC_HS,EDI_HS,VCM_HS,VICM2_HS,VICM_HS,MCP_A_HS,MCP_B_HS,FCP_HS,ONSTAR_HS,TCCM_HS,HCP_HS,BCP_HS,BCM_HS,PCM_HS,ECM_HS
 SG_ TERDTC_SysDes : 23|4@0+ (1,0) [0|15] ""  PCM_HS,ECM_HS
 SG_ TERDTC_CdNum : 19|12@0+ (1,0) [0|4095] ""  PCM_HS,ECM_HS

BO_ 409 PTEI_Trans_Torque_Request_HS: 8 TCM_HS
 SG_ TrnsAliveRC_199 : 7|2@0+ (1,0) [0|3] ""  PCM_HS,ECM_HS
 SG_ TDslPrtFltrIdlRgtnMdAtv : 5|1@0+ (1,0) [0|1] ""  PCM_HS,ECM_HS
 SG_ TransMinVoltReq : 55|8@0+ (0.07843,0) [0|19.99965] "volts"  PCM_HS,ECM_HS
 SG_ TransVehTopSpdLim : 63|8@0+ (2,0) [0|510] "km / h"  PCM_HS,ECM_HS
 SG_ TrnsTrqRqProt : 39|16@0+ (1,0) [0|65535] ""  PCM_HS,ECM_HS
 SG_ TTRLT_TorqReqVal : 19|12@0+ (0.5,-848) [-848|1199.5] "Nm"  PCM_HS,ECM_HS
 SG_ TTRLT_TqRdnRlznSgg : 21|2@0+ (1,0) [0|3] ""  PCM_HS,ECM_HS
 SG_ TTRLT_TorqInvntnTyp : 23|2@0+ (1,0) [0|3] ""  PCM_HS,ECM_HS
 SG_ TTRST_TorqReqVal : 3|12@0+ (0.5,-848) [-848|1199.5] "Nm"  PCM_HS,ECM_HS
 SG_ TTRST_TorqInvntnTyp : 4|1@0+ (1,0) [0|1] ""  PCM_HS,ECM_HS

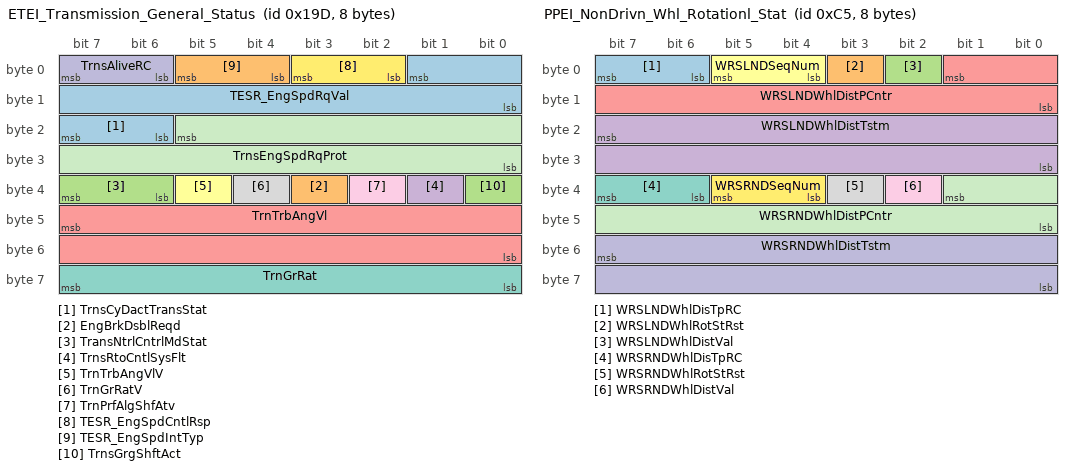
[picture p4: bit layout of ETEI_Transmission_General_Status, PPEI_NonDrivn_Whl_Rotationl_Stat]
BO_ 413 ETEI_Transmission_General_Status: 8 TCM_HS
 SG_ TrnsCyDactTransStat : 23|2@0+ (1,0) [0|3] ""  PCM_HS,ECM_HS
 SG_ EngBrkDsblReqd : 35|1@0+ (1,0) [0|1] ""  PCM_HS,ECM_HS
 SG_ TransNtrlCntrlMdStat : 39|2@0+ (1,0) [0|3] ""  EBCM_OBD_HS,EBCM_HS,BCM_HS,PCM_HS,ECM_HS
 SG_ TrnsRtoCntlSysFlt : 33|1@0+ (1,0) [0|1] ""  PCM_HS,ECM_HS
 SG_ TrnTrbAngVl : 47|16@0+ (0.25,0) [0|16383.75] "rpm"  BCP_HS,PCM_HS,ECM_HS
 SG_ TrnTrbAngVlV : 37|1@0+ (1,0) [0|1] ""  BCP_HS,PCM_HS,ECM_HS
 SG_ TrnGrRat : 63|8@0+ (0.03125,0) [0|7.96875] ""  EOCM_F_HS,PTAM_HS,BCP_HS,PCM_HS,ECM_HS
 SG_ TrnGrRatV : 36|1@0+ (1,0) [0|1] ""  EOCM_F_HS,PTAM_HS,BCP_HS,PCM_HS,ECM_HS
 SG_ TrnPrfAlgShfAtv : 34|1@0+ (1,0) [0|1] ""  PCM_HS,ECM_HS
 SG_ TrnsAliveRC : 7|2@0+ (1,0) [0|3] ""  PCM_HS,ECM_HS
 SG_ TrnsEngSpdRqProt : 21|14@0+ (1,0) [0|16383] ""  PCM_HS,ECM_HS
 SG_ TESR_EngSpdCntlRsp : 3|2@0+ (1,0) [0|3] ""  PCM_HS,ECM_HS
 SG_ TESR_EngSpdRqVal : 1|10@0+ (8,0) [0|8184] "rpm"  PCM_HS,ECM_HS
 SG_ TESR_EngSpdIntTyp : 5|2@0+ (1,0) [0|3] ""  PCM_HS,ECM_HS
 SG_ TrnsGrgShftAct : 32|1@0+ (1,0) [0|1] ""  PCM_HS,ECM_HS

BO_ 257 USDT_Req_to_All_HS_ECUs: 8 TestTool_HS
 SG_ DgnInf : 7|64@0+ (1,0) [0|1.844674407371E+019] ""  FICM_HS,PFAF_HS,VCM_HS,ARS_HS,MCP_B_HS,VLBS_HS,EBCM_OBD_HS,VITM_OBD_HS,GPCM_HS,MCP_A_HS,MCP_HS,TCCM_HS,SAS_HS,PTAM_HS,HMIM_HS,AMP_HS,FDCM_HS,VICM2_HS,AHL_AFL_HS,EPB_HS,AFS_HS,ICCM_HS,HCP_HS,BCP_HS,ACCM_HS,SADS_HS,ICCM_OBD_HS,FSCM_ITBC_HS,FSCM_HS,VICM_HS,APPS_HS,MCP_C_HS,FCP_HS,ONSTAR_HS,EOCM_F_HS,FCM_HS,RDCM_HS,PTO_HS,HPCC_HS,EBCM_HS,ACC_HS,ALC_HS,DCDC_HS,OBCM_HS,Dummy_HS,BCM_HS,TCM_HS,VES_HS,EPS_HS,PCM_HS,ECM_HS

BO_ 2015 USDT_OBD_Functional_Request: 8 TestTool_HS
 SG_ DgnInf : 7|64@0+ (1,0) [0|1.844674407371E+019] ""  FICM_HS,VICM_HS,ICCM_OBD_HS,FSCM_ITBC_HS,FSCM_HS,EBCM_OBD_HS,VITM_OBD_HS,GPCM_HS,VICM2_HS,HCP_HS,BCP_HS,TCM_HS,PCM_HS,ECM_HS

BO_ 2016 USDT_Req_to_ECM_HS: 8 TestTool_HS
 SG_ DgnInf : 7|64@0+ (1,0) [0|1.844674407371E+019] ""  PCM_HS,ECM_HS

BO_ 197 PPEI_NonDrivn_Whl_Rotationl_Stat: 8 EBCM_HS
 SG_ WRSLNDWhlDisTpRC : 7|2@0+ (1,0) [0|3] "counts"  PTO_HS,HCP_HS,ICCM_OBD_HS,ICCM_HS,HMIM_HS,PTAM_HS,AHL_AFL_HS,FSCM_ITBC_HS,BCP_HS,VES_HS,AFS_HS,EPB_HS,EPS_HS,FCP_HS,ONSTAR_HS,RDCM_HS,ACC_HS,BCM_HS,SADS_HS,TCM_HS,TCCM_HS,PCM_HS,ECM_HS
 SG_ WRSLNDWhlRotStRst : 3|1@0+ (1,0) [0|1] ""  PTO_HS,HCP_HS,ICCM_OBD_HS,ICCM_HS,HMIM_HS,PTAM_HS,AHL_AFL_HS,FSCM_ITBC_HS,BCP_HS,VES_HS,AFS_HS,EPB_HS,EPS_HS,FCP_HS,ONSTAR_HS,RDCM_HS,ACC_HS,BCM_HS,SADS_HS,TCM_HS,TCCM_HS,PCM_HS,ECM_HS
 SG_ WRSLNDWhlDistVal : 2|1@0+ (1,0) [0|1] ""  PTO_HS,HCP_HS,ICCM_OBD_HS,ICCM_HS,HMIM_HS,PTAM_HS,AHL_AFL_HS,FSCM_ITBC_HS,BCP_HS,VES_HS,AFS_HS,EPB_HS,EPS_HS,FCP_HS,ONSTAR_HS,RDCM_HS,ACC_HS,BCM_HS,SADS_HS,TCM_HS,TCCM_HS,PCM_HS,ECM_HS
 SG_ WRSLNDWhlDistTstm : 23|16@0+ (1,0) [0|65535] "counts"  PTO_HS,HCP_HS,ICCM_OBD_HS,ICCM_HS,HMIM_HS,PTAM_HS,AHL_AFL_HS,FSCM_ITBC_HS,BCP_HS,VES_HS,AFS_HS,EPB_HS,EPS_HS,FCP_HS,ONSTAR_HS,RDCM_HS,ACC_HS,BCM_HS,SADS_HS,TCM_HS,TCCM_HS,PCM_HS,ECM_HS
 SG_ WRSLNDWhlDistPCntr : 1|10@0+ (1,0) [0|1023] "counts"  PTO_HS,HCP_HS,ICCM_OBD_HS,ICCM_HS,HMIM_HS,PTAM_HS,AHL_AFL_HS,FSCM_ITBC_HS,BCP_HS,VES_HS,AFS_HS,EPB_HS,EPS_HS,FCP_HS,ONSTAR_HS,RDCM_HS,ACC_HS,BCM_HS,SADS_HS,TCM_HS,TCCM_HS,PCM_HS,ECM_HS
 SG_ WRSLNDSeqNum : 5|2@0+ (1,0) [0|3] "counts"  PTO_HS,HCP_HS,ICCM_OBD_HS,ICCM_HS,HMIM_HS,PTAM_HS,AHL_AFL_HS,FSCM_ITBC_HS,BCP_HS,VES_HS,AFS_HS,EPB_HS,EPS_HS,FCP_HS,ONSTAR_HS,RDCM_HS,ACC_HS,BCM_HS,SADS_HS,TCM_HS,TCCM_HS,PCM_HS,ECM_HS
 SG_ WRSRNDWhlDisTpRC : 39|2@0+ (1,0) [0|3] "counts"  PTO_HS,HCP_HS,ICCM_OBD_HS,ICCM_HS,HMIM_HS,PTAM_HS,AHL_AFL_HS,FSCM_ITBC_HS,BCP_HS,VES_HS,AFS_HS,EPS_HS,FCP_HS,ONSTAR_HS,RDCM_HS,ACC_HS,EPB_HS,SADS_HS,BCM_HS,TCM_HS,TCCM_HS,PCM_HS,ECM_HS
 SG_ WRSRNDWhlRotStRst : 35|1@0+ (1,0) [0|1] ""  PTO_HS,HCP_HS,ICCM_OBD_HS,ICCM_HS,HMIM_HS,PTAM_HS,AHL_AFL_HS,FSCM_ITBC_HS,BCP_HS,VES_HS,AFS_HS,EPS_HS,FCP_HS,ONSTAR_HS,RDCM_HS,ACC_HS,EPB_HS,SADS_HS,BCM_HS,TCM_HS,TCCM_HS,PCM_HS,ECM_HS
 SG_ WRSRNDWhlDistVal : 34|1@0+ (1,0) [0|1] ""  PTO_HS,HCP_HS,ICCM_OBD_HS,ICCM_HS,HMIM_HS,PTAM_HS,AHL_AFL_HS,FSCM_ITBC_HS,BCP_HS,VES_HS,AFS_HS,EPS_HS,FCP_HS,ONSTAR_HS,RDCM_HS,ACC_HS,EPB_HS,SADS_HS,BCM_HS,TCM_HS,TCCM_HS,PCM_HS,ECM_HS
 SG_ WRSRNDWhlDistTstm : 55|16@0+ (1,0) [0|65535] "counts"  PTO_HS,HCP_HS,ICCM_OBD_HS,ICCM_HS,HMIM_HS,PTAM_HS,AHL_AFL_HS,FSCM_ITBC_HS,BCP_HS,VES_HS,AFS_HS,EPS_HS,FCP_HS,ONSTAR_HS,RDCM_HS,ACC_HS,EPB_HS,SADS_HS,BCM_HS,TCM_HS,TCCM_HS,PCM_HS,ECM_HS
 SG_ WRSRNDWhlDistPCntr : 33|10@0+ (1,0) [0|1023] "counts"  PTO_HS,HCP_HS,ICCM_OBD_HS,ICCM_HS,HMIM_HS,PTAM_HS,AHL_AFL_HS,FSCM_ITBC_HS,BCP_HS,VES_HS,AFS_HS,EPS_HS,FCP_HS,ONSTAR_HS,RDCM_HS,ACC_HS,EPB_HS,SADS_HS,BCM_HS,TCM_HS,TCCM_HS,PCM_HS,ECM_HS
 SG_ WRSRNDSeqNum : 37|2@0+ (1,0) [0|3] "counts"  PTO_HS,HCP_HS,ICCM_OBD_HS,ICCM_HS,HMIM_HS,PTAM_HS,AHL_AFL_HS,FSCM_ITBC_HS,BCP_HS,VES_HS,AFS_HS,EPS_HS,FCP_HS,ONSTAR_HS,RDCM_HS,ACC_HS,EPB_HS,SADS_HS,BCM_HS,TCM_HS,TCCM_HS,PCM_HS,ECM_HS

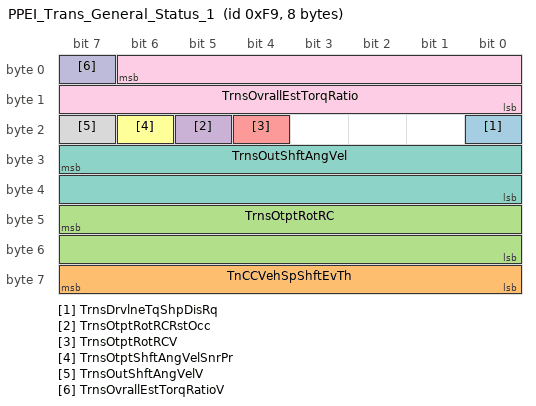
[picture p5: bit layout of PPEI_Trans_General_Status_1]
BO_ 249 PPEI_Trans_General_Status_1: 8 ECM_HS
 SG_ TrnsDrvlneTqShpDisRq : 16|1@0+ (1,0) [0|1] ""  PCM_HS,ECM_HS
 SG_ TnCCVehSpShftEvTh : 63|8@0+ (2,0) [0|510] "km / h"  PCM_HS,ECM_HS
 SG_ TrnsOtptRotRC : 47|16@0+ (0.0078125,0) [0|511.9921875] "rot"  EBCM_OBD_HS,EBCM_HS,PCM_HS,ECM_HS
 SG_ TrnsOtptRotRCRstOcc : 21|1@0+ (1,0) [0|1] ""  EBCM_OBD_HS,EBCM_HS,PCM_HS,ECM_HS
 SG_ TrnsOtptRotRCV : 20|1@0+ (1,0) [0|1] ""  EBCM_OBD_HS,EBCM_HS,PCM_HS,ECM_HS
 SG_ TrnsOtptShftAngVelSnrPr : 22|1@0+ (1,0) [0|1] ""  TCCM_HS,PCM_HS,ECM_HS
 SG_ TrnsOutShftAngVel : 31|16@0+ (0.25,0) [0|16383.75] "rpm"  EBCM_OBD_HS,EBCM_HS,TCCM_HS,PCM_HS,ECM_HS
 SG_ TrnsOutShftAngVelV : 23|1@0+ (1,0) [0|1] ""  EBCM_OBD_HS,EBCM_HS,TCCM_HS,PCM_HS,ECM_HS
 SG_ TrnsOvrallEstTorqRatio : 6|15@0- (0.00390625,0) [-64|63.99609375] ""  TCCM_HS,SADS_HS,RDCM_HS,EBCM_OBD_HS,EBCM_HS,PCM_HS,ECM_HS
 SG_ TrnsOvrallEstTorqRatioV : 7|1@0+ (1,0) [0|1] ""  TCCM_HS,SADS_HS,RDCM_HS,EBCM_OBD_HS,EBCM_HS,PCM_HS,ECM_HS

BO_TX_BU_ 493 : PCM_HS,ECM_HS;
BO_TX_BU_ 401 : PCM_HS,ECM_HS;
BO_TX_BU_ 1265 : PCM_HS,ECM_HS;
BO_TX_BU_ 417 : PCM_HS,ECM_HS;
BO_TX_BU_ 1233 : PCM_HS,ECM_HS;
BO_TX_BU_ 1217 : PCM_HS,ECM_HS;
BO_TX_BU_ 1017 : PCM_HS,ECM_HS;
BO_TX_BU_ 977 : PCM_HS,ECM_HS;
BO_TX_BU_ 201 : PCM_HS,ECM_HS;
BO_TX_BU_ 501 : PCM_HS,TCM_HS,ECM_HS;
BO_TX_BU_ 1225 : PCM_HS,TCM_HS,ECM_HS;
BO_TX_BU_ 257 : FCP_HS,ONSTAR_HS,TestTool_HS;
BO_TX_BU_ 2015 : FCP_HS,ONSTAR_HS,TestTool_HS;
BO_TX_BU_ 2016 : FCP_HS,ONSTAR_HS,TestTool_HS;
BO_TX_BU_ 197 : EBCM_OBD_HS,EBCM_HS;
BO_TX_BU_ 249 : PCM_HS,TCM_HS,ECM_HS;
CM_ SG_ 401 EngTrqTnsRqFld "Indicates that the Engine controller will not honor the torque request from the Transmission Controller due to a failure in the Rolling count, protection value, etc.";
CM_ SG_ 401 EngNTrnsRegStdyStTqV "ETEI 3.1";
CM_ SG_ 401 EngNTrnsRegStdyStTq "ETEI 3.1";
CM_ SG_ 401 EngAirflwStdyStTorqV "ETEI 3.1";
CM_ SG_ 401 EngAirflwStdyStTorq "ETEI 3.1";
CM_ SG_ 401 EngActStdyStTorqV "ETEI 3.1";
CM_ SG_ 401 EngActStdyStTorq "ETEI 3.1";
CM_ SG_ 417 TracCntlSysPwrtrnInhbt "ETEI 3.1";
CM_ SG_ 977 ACCmpNrmLdGrdAld "dm3/m/s = dm3/minute/second";
CM_ BO_ 201 "Changed for PPEI 3.6";
CM_ SG_ 201 EngRunAtv "Indication from powertrain that the engine is running (Has RPM > 0)";
CM_ SG_ 501 TrnShftPtrnActStat "(PT = Powertrain)";
BA_DEF_ SG_  "VNSigSLHS_VNReq" ENUM  "No","Yes";
BA_DEF_ SG_  "VNSigSLHSSharedDiagnostic" ENUM  "No","Yes";
BA_DEF_ SG_  "SignalType" STRING ;
BA_DEF_ SG_  "PacketOrder" INT 0 65535;
BA_DEF_ SG_  "SignalLongName" STRING ;
BA_DEF_ SG_  "GenSigStartValue" INT 0 65535;
BA_DEF_ SG_  "VNSigAllNodes" ENUM  "No","Yes";
BA_DEF_ SG_  "GenSigDeltaValue" INT 0 0;
BA_DEF_ SG_  "GenSigSendType" ENUM  "not used","not used","not used","not used","not used","not used","not used","NoSigSendType","not used","not used","OnAnyChange","OnChangeIfActive","OnDelta";
BA_DEF_ SG_  "GenSigSendOnInit" ENUM  "Not Initialized","Application","Handler";
BA_DEF_ BO_  "AppGenMsgCycleTime" INT 0 0;
BA_DEF_ BO_  "GenMsgILSupport" ENUM  "No","Yes";
BA_DEF_ BO_  "TpApplType" STRING ;
BA_DEF_ BO_  "Prio" INT 0 7;
BA_DEF_ BO_  "MessageSubnet" ENUM  "LS","MS","HS","CE","PE","HV","FO";
BA_DEF_ BO_  "DiagState" ENUM  "No","Yes";
BA_DEF_ BO_  "GenMsgDelayTime" INT 0 100000;
BA_DEF_ BO_  "GenMsgCycleTime" INT 0 100000;
BA_DEF_ BO_  "GenMsgSendType" ENUM  "cyclicX","spontanX","cyclicIfActiveX","spontanWithDelay","cyclicAndSpontanX","cyclicAndSpontanWithDelay","spontanWithRepitition","cyclicIfActiveAndSpontanWD";
BA_DEF_ BO_  "DiagResponse" ENUM  "No","Yes";
BA_DEF_ BO_  "DiagRequest" ENUM  "No","Yes";
BA_DEF_ BO_  "NmMessage" ENUM  "No","Yes";
BA_DEF_REL_ BU_SG_REL_  "GenSigSuprvRespComment" STRING ;
BA_DEF_REL_ BU_SG_REL_  "GenSigVBitResp" ENUM  "No","Yes";
BA_DEF_REL_ BU_SG_REL_  "GenSigVBitRespComment" STRING ;
BA_DEF_REL_ BU_SG_REL_  "GenSigVDAFailComment" STRING ;
BA_DEF_REL_ BU_SG_REL_  "GenSigVDAFailResp" ENUM  "No","Yes";
BA_DEF_REL_ BU_SG_REL_  "GenSigRxStartValue" STRING ;
BA_DEF_REL_ BU_SG_REL_  "GenSigSuprvRespSubValue" INT 0 65535;
BA_DEF_REL_ BU_SG_REL_  "GenSigSuprvResp" ENUM  "None","Notify App","Substitute Default";
BA_DEF_REL_ BU_SG_REL_  "GenSigTimeoutMsg" HEX -2147483648 268435455;
BA_DEF_REL_ BU_SG_REL_  "GenSigTimeoutTime" INT 0 15000;
BA_DEF_DEF_  "VNSigSLHS_VNReq" "No";
BA_DEF_DEF_  "VNSigSLHSSharedDiagnostic" "No";
BA_DEF_DEF_  "SignalType" "";
BA_DEF_DEF_  "PacketOrder" 0;
BA_DEF_DEF_  "SignalLongName" "";
BA_DEF_DEF_  "GenSigStartValue" 0;
BA_DEF_DEF_  "VNSigAllNodes" "No";
BA_DEF_DEF_  "GenSigDeltaValue" 0;
BA_DEF_DEF_  "GenSigSendType" "NoSigSendType";
BA_DEF_DEF_  "GenSigSendOnInit" "Not Initialized";
BA_DEF_DEF_  "AppGenMsgCycleTime" 0;
BA_DEF_DEF_  "GenMsgILSupport" "Yes";
BA_DEF_DEF_  "TpApplType" "";
BA_DEF_DEF_  "Prio" 4;
BA_DEF_DEF_  "MessageSubnet" "FO";
BA_DEF_DEF_  "DiagState" "No";
BA_DEF_DEF_  "GenMsgDelayTime" 0;
BA_DEF_DEF_  "GenMsgCycleTime" 0;
BA_DEF_DEF_  "GenMsgSendType" "spontanX";
BA_DEF_DEF_  "DiagResponse" "No";
BA_DEF_DEF_  "DiagRequest" "No";
BA_DEF_DEF_  "NmMessage" "No";
BA_DEF_DEF_REL_ "GenSigSuprvRespComment" "";
BA_DEF_DEF_REL_ "GenSigVBitResp" "No";
BA_DEF_DEF_REL_ "GenSigVBitRespComment" "";
BA_DEF_DEF_REL_ "GenSigVDAFailComment" "";
BA_DEF_DEF_REL_ "GenSigVDAFailResp" "No";
BA_DEF_DEF_REL_ "GenSigRxStartValue" "";
BA_DEF_DEF_REL_ "GenSigSuprvRespSubValue" 0;
BA_DEF_DEF_REL_ "GenSigSuprvResp" "None";
BA_DEF_DEF_REL_ "GenSigTimeoutMsg" 0;
BA_DEF_DEF_REL_ "GenSigTimeoutTime" 0;
BA_ "Prio" BO_ 493 0;
BA_ "MessageSubnet" BO_ 493 2;
BA_ "GenMsgCycleTime" BO_ 493 12;
BA_ "GenMsgSendType" BO_ 493 0;
BA_ "Prio" BO_ 401 0;
BA_ "MessageSubnet" BO_ 401 2;
BA_ "GenMsgCycleTime" BO_ 401 12;
BA_ "GenMsgSendType" BO_ 401 0;
BA_ "Prio" BO_ 707 0;
BA_ "MessageSubnet" BO_ 707 2;
BA_ "GenMsgCycleTime" BO_ 707 50;
BA_ "GenMsgSendType" BO_ 707 0;
BA_ "Prio" BO_ 1265 0;
BA_ "MessageSubnet" BO_ 1265 2;
BA_ "GenMsgCycleTime" BO_ 1265 1000;
BA_ "GenMsgSendType" BO_ 1265 0;
BA_ "Prio" BO_ 417 0;
BA_ "MessageSubnet" BO_ 417 2;
BA_ "GenMsgCycleTime" BO_ 417 25;
BA_ "GenMsgSendType" BO_ 417 0;
BA_ "Prio" BO_ 1233 0;
BA_ "MessageSubnet" BO_ 1233 2;
BA_ "GenMsgCycleTime" BO_ 1233 500;
BA_ "GenMsgSendType" BO_ 1233 0;
BA_ "Prio" BO_ 1217 0;
BA_ "MessageSubnet" BO_ 1217 2;
BA_ "GenMsgCycleTime" BO_ 1217 500;
BA_ "GenMsgSendType" BO_ 1217 0;
BA_ "Prio" BO_ 985 0;
BA_ "MessageSubnet" BO_ 985 2;
BA_ "GenMsgCycleTime" BO_ 985 100;
BA_ "GenMsgSendType" BO_ 985 0;
BA_ "Prio" BO_ 1017 0;
BA_ "MessageSubnet" BO_ 1017 2;
BA_ "GenMsgCycleTime" BO_ 1017 250;
BA_ "GenMsgSendType" BO_ 1017 0;
BA_ "Prio" BO_ 977 0;
BA_ "MessageSubnet" BO_ 977 2;
BA_ "GenMsgCycleTime" BO_ 977 100;
BA_ "GenMsgSendType" BO_ 977 0;
BA_ "Prio" BO_ 201 0;
BA_ "MessageSubnet" BO_ 201 2;
BA_ "GenMsgCycleTime" BO_ 201 12;
BA_ "GenMsgSendType" BO_ 201 0;
BA_ "Prio" BO_ 501 0;
BA_ "MessageSubnet" BO_ 501 2;
BA_ "GenMsgCycleTime" BO_ 501 25;
BA_ "GenMsgSendType" BO_ 501 0;
BA_ "Prio" BO_ 1225 0;
BA_ "MessageSubnet" BO_ 1225 2;
BA_ "GenMsgCycleTime" BO_ 1225 500;
BA_ "GenMsgSendType" BO_ 1225 0;
BA_ "Prio" BO_ 409 0;
BA_ "MessageSubnet" BO_ 409 2;
BA_ "GenMsgCycleTime" BO_ 409 25;
BA_ "GenMsgSendType" BO_ 409 0;
BA_ "Prio" BO_ 413 0;
BA_ "MessageSubnet" BO_ 413 2;
BA_ "GenMsgCycleTime" BO_ 413 25;
BA_ "GenMsgSendType" BO_ 413 0;
BA_ "GenMsgILSupport" BO_ 257 0;
BA_ "Prio" BO_ 257 0;
BA_ "MessageSubnet" BO_ 257 2;
BA_ "DiagState" BO_ 257 1;
BA_ "GenMsgILSupport" BO_ 2015 0;
BA_ "Prio" BO_ 2015 0;
BA_ "MessageSubnet" BO_ 2015 2;
BA_ "Prio" BO_ 2016 0;
BA_ "MessageSubnet" BO_ 2016 2;
BA_ "DiagRequest" BO_ 2016 1;
BA_ "Prio" BO_ 197 0;
BA_ "MessageSubnet" BO_ 197 2;
BA_ "GenMsgCycleTime" BO_ 197 10;
BA_ "GenMsgSendType" BO_ 197 0;
BA_ "Prio" BO_ 249 0;
BA_ "MessageSubnet" BO_ 249 2;
BA_ "GenMsgCycleTime" BO_ 249 12;
BA_ "GenMsgSendType" BO_ 249 0;
BA_ "SignalType" SG_ 493 EngRunng "BLN";
BA_ "SignalLongName" SG_ 493 EngRunng "Engine Running";
BA_ "VNSigAllNodes" SG_ 493 EngRunng 1;
BA_ "SignalType" SG_ 493 FlPmpEDscOtptCmdSta "ENM";
BA_ "SignalLongName" SG_ 493 FlPmpEDscOtptCmdSta "Fuel Pump Enabled Discrete Output Commanded Status";
BA_ "VNSigAllNodes" SG_ 493 FlPmpEDscOtptCmdSta 1;
BA_ "SignalType" SG_ 493 CmmndAirFuelRatio "UNM";
BA_ "SignalLongName" SG_ 493 CmmndAirFuelRatio "Commanded Air Fuel Ratio";
BA_ "VNSigAllNodes" SG_ 493 CmmndAirFuelRatio 1;
BA_ "SignalType" SG_ 493 AdvFuelFlowEst "UNM";
BA_ "SignalLongName" SG_ 493 AdvFuelFlowEst "Advanced Fuel Flow Estimate";
BA_ "VNSigAllNodes" SG_ 493 AdvFuelFlowEst 1;
BA_ "SignalType" SG_ 493 InstFuelFlowEst "UNM";
BA_ "SignalLongName" SG_ 493 InstFuelFlowEst "Instantaneous Fuel Flow Estimate";
BA_ "VNSigAllNodes" SG_ 493 InstFuelFlowEst 1;
BA_ "SignalType" SG_ 493 FuelDelPressRqd "UNM";
BA_ "SignalLongName" SG_ 493 FuelDelPressRqd "Fuel Delivery Pressure Requested";
BA_ "VNSigAllNodes" SG_ 493 FuelDelPressRqd 1;
BA_ "SignalType" SG_ 493 FuelCntlSysFltPrsnt "BLN";
BA_ "SignalLongName" SG_ 493 FuelCntlSysFltPrsnt "Fuel Control System Fault Present";
BA_ "VNSigAllNodes" SG_ 493 FuelCntlSysFltPrsnt 1;
BA_ "SignalType" SG_ 401 EngTrqTrnRqTmpFld "BLN";
BA_ "SignalLongName" SG_ 401 EngTrqTrnRqTmpFld "Engine Torque Transmission Request Temporarily Failed";
BA_ "VNSigAllNodes" SG_ 401 EngTrqTrnRqTmpFld 1;
BA_ "SignalType" SG_ 401 EngTrqTrnRqLmtd "BLN";
BA_ "SignalLongName" SG_ 401 EngTrqTrnRqLmtd "Engine Torque Transmission Request Limited";
BA_ "VNSigAllNodes" SG_ 401 EngTrqTrnRqLmtd 1;
BA_ "SignalType" SG_ 401 TrnsEngSpdReqFld "BLN";
BA_ "SignalLongName" SG_ 401 TrnsEngSpdReqFld "Transmission Engine Speed Request Failed";
BA_ "VNSigAllNodes" SG_ 401 TrnsEngSpdReqFld 1;
BA_ "SignalType" SG_ 401 ThrtCommndPos "UNM";
BA_ "SignalLongName" SG_ 401 ThrtCommndPos "Throttle Commanded Position";
BA_ "VNSigAllNodes" SG_ 401 ThrtCommndPos 1;
BA_ "SignalType" SG_ 401 EngTrqTnsRqFld "BLN";
BA_ "SignalLongName" SG_ 401 EngTrqTnsRqFld "Engine Torque Transmission Request Failed";
BA_ "VNSigAllNodes" SG_ 401 EngTrqTnsRqFld 1;
BA_ "SignalType" SG_ 401 EngTrqRdnFld "BLN";
BA_ "SignalLongName" SG_ 401 EngTrqRdnFld "Engine Torque Reduction Failed";
BA_ "VNSigAllNodes" SG_ 401 EngTrqRdnFld 1;
BA_ "SignalType" SG_ 401 EngNTrnsRegStdyStTqV "ENM";
BA_ "SignalLongName" SG_ 401 EngNTrnsRegStdyStTqV "Engine Non-Transmission Regulated Steady State Torque Validity";
BA_ "VNSigAllNodes" SG_ 401 EngNTrnsRegStdyStTqV 1;
BA_ "SignalType" SG_ 401 EngNTrnsRegStdyStTq "UNM";
BA_ "SignalLongName" SG_ 401 EngNTrnsRegStdyStTq "Engine Non-Transmission Regulated Steady State Torque";
BA_ "VNSigAllNodes" SG_ 401 EngNTrnsRegStdyStTq 1;
BA_ "SignalType" SG_ 401 EngAirflwStdyStTorqV "ENM";
BA_ "SignalLongName" SG_ 401 EngAirflwStdyStTorqV "Engine Airflow Steady State Torque Validity";
BA_ "VNSigAllNodes" SG_ 401 EngAirflwStdyStTorqV 1;
BA_ "SignalType" SG_ 401 EngAirflwStdyStTorq "UNM";
BA_ "SignalLongName" SG_ 401 EngAirflwStdyStTorq "Engine Airflow Steady State Torque";
BA_ "VNSigAllNodes" SG_ 401 EngAirflwStdyStTorq 1;
BA_ "SignalType" SG_ 401 AccKdwnAtv "BLN";
BA_ "SignalLongName" SG_ 401 AccKdwnAtv "Accelerator Kick Down Detected";
BA_ "VNSigAllNodes" SG_ 401 AccKdwnAtv 1;
BA_ "SignalType" SG_ 401 AccPosV "ENM";
BA_ "SignalLongName" SG_ 401 AccPosV "Accelerator Effective Position Validity";
BA_ "VNSigAllNodes" SG_ 401 AccPosV 1;
BA_ "SignalType" SG_ 401 AccPos "UNM";
BA_ "SignalLongName" SG_ 401 AccPos "Accelerator Effective Position";
BA_ "VNSigAllNodes" SG_ 401 AccPos 1;
BA_ "SignalType" SG_ 401 EngActStdyStTorqV "ENM";
BA_ "SignalLongName" SG_ 401 EngActStdyStTorqV "Engine Actual Steady State Torque Validity";
BA_ "VNSigAllNodes" SG_ 401 EngActStdyStTorqV 1;
BA_ "SignalType" SG_ 401 EngActStdyStTorq "UNM";
BA_ "SignalLongName" SG_ 401 EngActStdyStTorq "Engine Actual Steady State Torque";
BA_ "VNSigAllNodes" SG_ 401 EngActStdyStTorq 1;
BA_ "SignalType" SG_ 707 CSTATRS_ReqStat "ENM";
BA_ "PacketOrder" SG_ 707 CSTATRS_ReqStat 2;
BA_ "SignalLongName" SG_ 707 CSTATRS_ReqStat "Chassis System Total Axle Torque Request Status : Request Status";
BA_ "VNSigAllNodes" SG_ 707 CSTATRS_ReqStat 1;
BA_ "SignalType" SG_ 707 CSTATRS_LmtgStat "ENM";
BA_ "PacketOrder" SG_ 707 CSTATRS_LmtgStat 1;
BA_ "SignalLongName" SG_ 707 CSTATRS_LmtgStat "Chassis System Total Axle Torque Request Status : Limiting Status";
BA_ "VNSigAllNodes" SG_ 707 CSTATRS_LmtgStat 1;
BA_ "SignalType" SG_ 707 EngManfldAbsPrsV "ENM";
BA_ "SignalLongName" SG_ 707 EngManfldAbsPrsV "Engine Manifold Absolute Pressure Validity";
BA_ "VNSigAllNodes" SG_ 707 EngManfldAbsPrsV 1;
BA_ "SignalType" SG_ 707 EngManfldAbsPrs "UNM";
BA_ "SignalLongName" SG_ 707 EngManfldAbsPrs "Engine Manifold Absolute Pressure";
BA_ "VNSigAllNodes" SG_ 707 EngManfldAbsPrs 1;
BA_ "SignalType" SG_ 707 EngTrqMinExtRngV "ENM";
BA_ "SignalLongName" SG_ 707 EngTrqMinExtRngV "Engine Torque Minimum Extended Range Validity";
BA_ "VNSigAllNodes" SG_ 707 EngTrqMinExtRngV 1;
BA_ "SignalType" SG_ 707 EngTrqMinExtRng "UNM";
BA_ "SignalLongName" SG_ 707 EngTrqMinExtRng "Engine Torque Minimum Extended Range";
BA_ "GenSigStartValue" SG_ 707 EngTrqMinExtRng 1696;
BA_ "VNSigAllNodes" SG_ 707 EngTrqMinExtRng 1;
BA_ "SignalType" SG_ 707 EngTrqMaxExtRngV "ENM";
BA_ "SignalLongName" SG_ 707 EngTrqMaxExtRngV "Engine Torque Maximum Extended Range Validity";
BA_ "VNSigAllNodes" SG_ 707 EngTrqMaxExtRngV 1;
BA_ "SignalType" SG_ 707 EngTrqMaxExtRng "UNM";
BA_ "SignalLongName" SG_ 707 EngTrqMaxExtRng "Engine Torque Maximum Extended Range";
BA_ "GenSigStartValue" SG_ 707 EngTrqMaxExtRng 1696;
BA_ "VNSigAllNodes" SG_ 707 EngTrqMaxExtRng 1;
BA_ "SignalType" SG_ 1265 PTSysHzrdLghtReq "BLN";
BA_ "SignalLongName" SG_ 1265 PTSysHzrdLghtReq "Powertrain System Hazard Lights Request";
BA_ "VNSigAllNodes" SG_ 1265 PTSysHzrdLghtReq 1;
BA_ "SignalType" SG_ 1265 EngOffTmPT "UNM";
BA_ "SignalLongName" SG_ 1265 EngOffTmPT "Engine Off Time Powertrain";
BA_ "VNSigAllNodes" SG_ 1265 EngOffTmPT 1;
BA_ "SignalType" SG_ 1265 EngOffTmPTV "ENM";
BA_ "SignalLongName" SG_ 1265 EngOffTmPTV "Engine Off Time Powertrain Validity";
BA_ "VNSigAllNodes" SG_ 1265 EngOffTmPTV 1;
BA_ "SignalType" SG_ 1265 EngOffTmPTM "ENM";
BA_ "SignalLongName" SG_ 1265 EngOffTmPTM "Engine Off Time Powertrain Mask";
BA_ "VNSigAllNodes" SG_ 1265 EngOffTmPTM 1;
BA_ "SignalType" SG_ 1265 WhlDistPrRevNDrvn "UNM";
BA_ "SignalLongName" SG_ 1265 WhlDistPrRevNDrvn "Wheel Distance Per Revolution Non Driven";
BA_ "VNSigAllNodes" SG_ 1265 WhlDistPrRevNDrvn 1;
BA_ "SignalType" SG_ 1265 WhlDistPrRevDrvn "UNM";
BA_ "SignalLongName" SG_ 1265 WhlDistPrRevDrvn "Wheel Distance Per Revolution Driven";
BA_ "VNSigAllNodes" SG_ 1265 WhlDistPrRevDrvn 1;
BA_ "SignalType" SG_ 1265 DrvlnFnlAxleRatio "UNM";
BA_ "SignalLongName" SG_ 1265 DrvlnFnlAxleRatio "Driveline Final Axle Ratio";
BA_ "VNSigAllNodes" SG_ 1265 DrvlnFnlAxleRatio 1;
BA_ "SignalType" SG_ 417 EngCrsCntrlMode "ENM";
BA_ "SignalLongName" SG_ 417 EngCrsCntrlMode "Engine Cruise Control Mode";
BA_ "VNSigAllNodes" SG_ 417 EngCrsCntrlMode 1;
BA_ "SignalType" SG_ 417 EngPstOxgSnsDgAstRq "BLN";
BA_ "SignalLongName" SG_ 417 EngPstOxgSnsDgAstRq "Engine Post Oxygen Sensor Diagnostic Assistance Requested";
BA_ "VNSigAllNodes" SG_ 417 EngPstOxgSnsDgAstRq 1;
BA_ "SignalType" SG_ 417 CrsCtrlCnstSpdAct "BLN";
BA_ "SignalLongName" SG_ 417 CrsCtrlCnstSpdAct "Cruise Control Constant Speed Active";
BA_ "VNSigAllNodes" SG_ 417 CrsCtrlCnstSpdAct 1;
BA_ "SignalType" SG_ 417 WrmUpShftPtrnRq "ENM";
BA_ "SignalLongName" SG_ 417 WrmUpShftPtrnRq "Warm Up Shift Pattern Request";
BA_ "VNSigAllNodes" SG_ 417 WrmUpShftPtrnRq 1;
BA_ "SignalType" SG_ 417 EngIdlSpdRdcdRng "UNM";
BA_ "SignalLongName" SG_ 417 EngIdlSpdRdcdRng "Engine Idle Speed Reduced Range";
BA_ "VNSigAllNodes" SG_ 417 EngIdlSpdRdcdRng 1;
BA_ "SignalType" SG_ 417 EngAlwCltAdp "BLN";
BA_ "SignalLongName" SG_ 417 EngAlwCltAdp "Engine Allowed Clutch Adaptation";
BA_ "VNSigAllNodes" SG_ 417 EngAlwCltAdp 1;
BA_ "SignalType" SG_ 417 BsTrgtEngIdlSpd "UNM";
BA_ "SignalLongName" SG_ 417 BsTrgtEngIdlSpd "Base Target Engine Idle Speed";
BA_ "VNSigAllNodes" SG_ 417 BsTrgtEngIdlSpd 1;
BA_ "SignalType" SG_ 417 AccPdlPosPcntFullRngV "ENM";
BA_ "SignalLongName" SG_ 417 AccPdlPosPcntFullRngV "Accelerator Pedal Position Percent Full Range  Validity";
BA_ "VNSigAllNodes" SG_ 417 AccPdlPosPcntFullRngV 1;
BA_ "SignalType" SG_ 417 AccPdlPosPcntFullRng "UNM";
BA_ "SignalLongName" SG_ 417 AccPdlPosPcntFullRng "Accelerator Pedal Position Percent Full Range";
BA_ "VNSigAllNodes" SG_ 417 AccPdlPosPcntFullRng 1;
BA_ "SignalType" SG_ 417 DslPrtFltrIdlRgtnMdReq "BLN";
BA_ "SignalLongName" SG_ 417 DslPrtFltrIdlRgtnMdReq "Diesel Particulate Filter Idle Regeneration Mode Request";
BA_ "VNSigAllNodes" SG_ 417 DslPrtFltrIdlRgtnMdReq 1;
BA_ "SignalType" SG_ 417 DslPartFltrClngAlgActM "ENM";
BA_ "SignalLongName" SG_ 417 DslPartFltrClngAlgActM "Diesel Particle Filter Cleaning Algorithm Active Mask";
BA_ "VNSigAllNodes" SG_ 417 DslPartFltrClngAlgActM 1;
BA_ "SignalType" SG_ 417 DslPartFltrClngAlgAct "BLN";
BA_ "SignalLongName" SG_ 417 DslPartFltrClngAlgAct "Diesel Particle Filter Cleaning Algorithm Active";
BA_ "VNSigAllNodes" SG_ 417 DslPartFltrClngAlgAct 1;
BA_ "SignalType" SG_ 417 EngCylDeactMd "ENM";
BA_ "SignalLongName" SG_ 417 EngCylDeactMd "Engine Cylinder Deactivation Mode";
BA_ "VNSigAllNodes" SG_ 417 EngCylDeactMd 1;
BA_ "SignalType" SG_ 417 ACCmCltEngd "BLN";
BA_ "SignalLongName" SG_ 417 ACCmCltEngd "Air Conditioning Compressor Clutch Engaged";
BA_ "VNSigAllNodes" SG_ 417 ACCmCltEngd 1;
BA_ "SignalType" SG_ 417 ParkNeutralSwStatV "ENM";
BA_ "SignalLongName" SG_ 417 ParkNeutralSwStatV "Park Neutral Switch Status Validity";
BA_ "VNSigAllNodes" SG_ 417 ParkNeutralSwStatV 1;
BA_ "SignalType" SG_ 417 ParkNeutralSwStat "ENM";
BA_ "SignalLongName" SG_ 417 ParkNeutralSwStat "Park Neutral Switch Status";
BA_ "VNSigAllNodes" SG_ 417 ParkNeutralSwStat 1;
BA_ "SignalType" SG_ 417 EngColdHiIdleActive "BLN";
BA_ "SignalLongName" SG_ 417 EngColdHiIdleActive "Engine Cold High Idle Active";
BA_ "VNSigAllNodes" SG_ 417 EngColdHiIdleActive 1;
BA_ "SignalType" SG_ 417 EngCyDactTqSmtAct "BLN";
BA_ "SignalLongName" SG_ 417 EngCyDactTqSmtAct "Engine Cylinder Deactivation Torque Smoothing Active";
BA_ "VNSigAllNodes" SG_ 417 EngCyDactTqSmtAct 1;
BA_ "SignalType" SG_ 417 EngBrkStat "ENM";
BA_ "SignalLongName" SG_ 417 EngBrkStat "Engine Brake Status";
BA_ "VNSigAllNodes" SG_ 417 EngBrkStat 1;
BA_ "SignalType" SG_ 417 TracCntlSysPwrtrnInhbt "BLN";
BA_ "SignalLongName" SG_ 417 TracCntlSysPwrtrnInhbt "Traction Control System Powertrain Inhibit";
BA_ "VNSigAllNodes" SG_ 417 TracCntlSysPwrtrnInhbt 1;
BA_ "SignalType" SG_ 417 EngMtlProtAtv "BLN";
BA_ "SignalLongName" SG_ 417 EngMtlProtAtv "Engine Metal Protection Active";
BA_ "VNSigAllNodes" SG_ 417 EngMtlProtAtv 1;
BA_ "SignalType" SG_ 417 EngDgTrqCnvClUnlkRqd "BLN";
BA_ "SignalLongName" SG_ 417 EngDgTrqCnvClUnlkRqd "Engine Diagnostic Torque Converter Clutch Unlock Requested";
BA_ "VNSigAllNodes" SG_ 417 EngDgTrqCnvClUnlkRqd 1;
BA_ "SignalType" SG_ 417 EngCyldrDeactReqd "BLN";
BA_ "SignalLongName" SG_ 417 EngCyldrDeactReqd "Engine Cylinder Deactivation Requested";
BA_ "VNSigAllNodes" SG_ 417 EngCyldrDeactReqd 1;
BA_ "SignalType" SG_ 417 ETGRReqdGear "ENM";
BA_ "PacketOrder" SG_ 417 ETGRReqdGear 2;
BA_ "SignalLongName" SG_ 417 ETGRReqdGear "Engine Transmission Gear Request : Requested Gear";
BA_ "VNSigAllNodes" SG_ 417 ETGRReqdGear 1;
BA_ "SignalType" SG_ 417 ETGRReqType "ENM";
BA_ "PacketOrder" SG_ 417 ETGRReqType 1;
BA_ "SignalLongName" SG_ 417 ETGRReqType "Engine Transmission Gear Request : Request Type";
BA_ "VNSigAllNodes" SG_ 417 ETGRReqType 1;
BA_ "SignalType" SG_ 1233 EngShtdwnAct "BLN";
BA_ "SignalLongName" SG_ 1233 EngShtdwnAct "Engine Shutdown Active";
BA_ "VNSigAllNodes" SG_ 1233 EngShtdwnAct 1;
BA_ "SignalType" SG_ 1233 EngShtdwnPndgIO "BLN";
BA_ "SignalLongName" SG_ 1233 EngShtdwnPndgIO "Engine Shutdown Pending Indication On";
BA_ "VNSigAllNodes" SG_ 1233 EngShtdwnPndgIO 1;
BA_ "SignalType" SG_ 1233 FuelFltChgNwIO "BLN";
BA_ "SignalLongName" SG_ 1233 FuelFltChgNwIO "Fuel Filter Change Now Indication On";
BA_ "VNSigAllNodes" SG_ 1233 FuelFltChgNwIO 1;
BA_ "SignalType" SG_ 1233 PTExPrtclFltrWrn2IO "BLN";
BA_ "SignalLongName" SG_ 1233 PTExPrtclFltrWrn2IO "Powertrain Exhaust Particle Filter Warning 2 Indication On";
BA_ "VNSigAllNodes" SG_ 1233 PTExPrtclFltrWrn2IO 1;
BA_ "SignalType" SG_ 1233 PTHiElecLdReqd "BLN";
BA_ "SignalLongName" SG_ 1233 PTHiElecLdReqd "Powertrain High Electrical Load Requested";
BA_ "VNSigAllNodes" SG_ 1233 PTHiElecLdReqd 1;
BA_ "SignalType" SG_ 1233 PTExPrtclFltrWrnIO "BLN";
BA_ "SignalLongName" SG_ 1233 PTExPrtclFltrWrnIO "Powertrain Exhaust Particle Filter Warning Indication On";
BA_ "VNSigAllNodes" SG_ 1233 PTExPrtclFltrWrnIO 1;
BA_ "SignalType" SG_ 1233 AirCndOffIO "BLN";
BA_ "SignalLongName" SG_ 1233 AirCndOffIO "Air Conditioning Off Indication On";
BA_ "VNSigAllNodes" SG_ 1233 AirCndOffIO 1;
BA_ "SignalType" SG_ 1233 DslGlwPlgIO "BLN";
BA_ "SignalLongName" SG_ 1233 DslGlwPlgIO "Diesel Glow Plug Indication On";
BA_ "VNSigAllNodes" SG_ 1233 DslGlwPlgIO 1;
BA_ "SignalType" SG_ 1233 StgDisIO "BLN";
BA_ "SignalLongName" SG_ 1233 StgDisIO "Starting Disabled Indication On";
BA_ "VNSigAllNodes" SG_ 1233 StgDisIO 1;
BA_ "SignalType" SG_ 1233 RdcdPwrIO "BLN";
BA_ "SignalLongName" SG_ 1233 RdcdPwrIO "Reduced Power Indication On";
BA_ "VNSigAllNodes" SG_ 1233 RdcdPwrIO 1;
BA_ "SignalType" SG_ 1233 FuelTotCap "UNM";
BA_ "SignalLongName" SG_ 1233 FuelTotCap "Fuel Total Capacity";
BA_ "VNSigAllNodes" SG_ 1233 FuelTotCap 1;
BA_ "SignalType" SG_ 1233 FlLvlPctV "ENM";
BA_ "SignalLongName" SG_ 1233 FlLvlPctV "Fuel Level Percent Validity";
BA_ "VNSigAllNodes" SG_ 1233 FlLvlPctV 1;
BA_ "SignalType" SG_ 1233 FlLvlPct "UNM";
BA_ "SignalLongName" SG_ 1233 FlLvlPct "Fuel Level Percent";
BA_ "VNSigAllNodes" SG_ 1233 FlLvlPct 1;
BA_ "SignalType" SG_ 1233 EngWtrInFlIO "BLN";
BA_ "SignalLongName" SG_ 1233 EngWtrInFlIO "Engine Water In Fuel Indication On";
BA_ "VNSigAllNodes" SG_ 1233 EngWtrInFlIO 1;
BA_ "SignalType" SG_ 1233 EngOilTmpV "ENM";
BA_ "SignalLongName" SG_ 1233 EngOilTmpV "Engine Oil Temperature Validity";
BA_ "VNSigAllNodes" SG_ 1233 EngOilTmpV 1;
BA_ "SignalType" SG_ 1233 EngOilTmp "UNM";
BA_ "SignalLongName" SG_ 1233 EngOilTmp "Engine Oil Temperature";
BA_ "VNSigAllNodes" SG_ 1233 EngOilTmp 1;
BA_ "SignalType" SG_ 1233 EngOilPrsV "ENM";
BA_ "SignalLongName" SG_ 1233 EngOilPrsV "Engine Oil Pressure Validity";
BA_ "VNSigAllNodes" SG_ 1233 EngOilPrsV 1;
BA_ "SignalType" SG_ 1233 EngOilPrsLwIO "BLN";
BA_ "SignalLongName" SG_ 1233 EngOilPrsLwIO "Engine Oil Pressure Low Indication On";
BA_ "VNSigAllNodes" SG_ 1233 EngOilPrsLwIO 1;
BA_ "SignalType" SG_ 1233 EngOilPrs "UNM";
BA_ "SignalLongName" SG_ 1233 EngOilPrs "Engine Oil Pressure";
BA_ "VNSigAllNodes" SG_ 1233 EngOilPrs 1;
BA_ "SignalType" SG_ 1233 EngOilLvlLwIO "BLN";
BA_ "SignalLongName" SG_ 1233 EngOilLvlLwIO "Engine Oil Level Low Indication On";
BA_ "VNSigAllNodes" SG_ 1233 EngOilLvlLwIO 1;
BA_ "SignalType" SG_ 1233 EngOilChngIO "BLN";
BA_ "SignalLongName" SG_ 1233 EngOilChngIO "Engine Oil Change Indication On";
BA_ "VNSigAllNodes" SG_ 1233 EngOilChngIO 1;
BA_ "SignalType" SG_ 1233 EngHt_StpEngIO "BLN";
BA_ "SignalLongName" SG_ 1233 EngHt_StpEngIO "Engine Hot / Stop Engine Indication On";
BA_ "VNSigAllNodes" SG_ 1233 EngHt_StpEngIO 1;
BA_ "SignalType" SG_ 1233 EngHotFuelEnrchmntIO "BLN";
BA_ "SignalLongName" SG_ 1233 EngHotFuelEnrchmntIO "Engine Hot Fuel Enrichment Indication On";
BA_ "VNSigAllNodes" SG_ 1233 EngHotFuelEnrchmntIO 1;
BA_ "SignalType" SG_ 1233 CkFlFilrCapIO "BLN";
BA_ "SignalLongName" SG_ 1233 CkFlFilrCapIO "Check Fuel Filler Cap Indication On";
BA_ "VNSigAllNodes" SG_ 1233 CkFlFilrCapIO 1;
BA_ "SignalType" SG_ 1217 LegPstDTCClrDrvCyCm "BLN";
BA_ "SignalLongName" SG_ 1217 LegPstDTCClrDrvCyCm "Legislated Post DTC Clear Drive Cycle Complete";
BA_ "VNSigAllNodes" SG_ 1217 LegPstDTCClrDrvCyCm 1;
BA_ "SignalType" SG_ 1217 LegDiagColdStCndMet "BLN";
BA_ "SignalLongName" SG_ 1217 LegDiagColdStCndMet "Legislated Diagnostics Cold Start Conditions Met";
BA_ "VNSigAllNodes" SG_ 1217 LegDiagColdStCndMet 1;
BA_ "SignalType" SG_ 1217 LegDiagColdStCndFltPr "BLN";
BA_ "SignalLongName" SG_ 1217 LegDiagColdStCndFltPr "Legislated Diagnostics Cold Start Conditions Fault Present";
BA_ "VNSigAllNodes" SG_ 1217 LegDiagColdStCndFltPr 1;
BA_ "SignalType" SG_ 1217 EngEconMdCmnd "BLN";
BA_ "SignalLongName" SG_ 1217 EngEconMdCmnd "Engine Economy Mode Commanded";
BA_ "VNSigAllNodes" SG_ 1217 EngEconMdCmnd 1;
BA_ "SignalType" SG_ 1217 DslExhFldRmngDstHRsV "ENM";
BA_ "SignalLongName" SG_ 1217 DslExhFldRmngDstHRsV "Diesel Exhaust Fluid Remaining Distance High Resolution Validity";
BA_ "VNSigAllNodes" SG_ 1217 DslExhFldRmngDstHRsV 1;
BA_ "SignalType" SG_ 1217 DslExhFldRmngDstHRs "UNM";
BA_ "SignalLongName" SG_ 1217 DslExhFldRmngDstHRs "Diesel Exhaust Fluid Remaining Distance High Resolution";
BA_ "VNSigAllNodes" SG_ 1217 DslExhFldRmngDstHRs 1;
BA_ "SignalType" SG_ 1217 EngOilHotIO "BLN";
BA_ "SignalLongName" SG_ 1217 EngOilHotIO "Engine Oil Hot Indication On";
BA_ "VNSigAllNodes" SG_ 1217 EngOilHotIO 1;
BA_ "SignalType" SG_ 1217 OAT_PT_EstV "ENM";
BA_ "SignalLongName" SG_ 1217 OAT_PT_EstV "Outside Air Temperature Powertrain Estimated Validity";
BA_ "VNSigAllNodes" SG_ 1217 OAT_PT_EstV 1;
BA_ "SignalType" SG_ 1217 LegDiagStndCndMet "BLN";
BA_ "SignalLongName" SG_ 1217 LegDiagStndCndMet "Legislated Diagnostics Standard Conditions Met";
BA_ "VNSigAllNodes" SG_ 1217 LegDiagStndCndMet 1;
BA_ "SignalType" SG_ 1217 LegDiagStndCndFltPr "BLN";
BA_ "SignalLongName" SG_ 1217 LegDiagStndCndFltPr "Legislated Diagnostics Standard Conditions Fault Present";
BA_ "VNSigAllNodes" SG_ 1217 LegDiagStndCndFltPr 1;
BA_ "SignalType" SG_ 1217 OAT_PT_EstM "ENM";
BA_ "SignalLongName" SG_ 1217 OAT_PT_EstM "Outside Air Temperature Powertrain Estimated Mask";
BA_ "VNSigAllNodes" SG_ 1217 OAT_PT_EstM 1;
BA_ "SignalType" SG_ 1217 OAT_PT_Est "UNM";
BA_ "SignalLongName" SG_ 1217 OAT_PT_Est "Outside Air Temperature Powertrain Estimated";
BA_ "VNSigAllNodes" SG_ 1217 OAT_PT_Est 1;
BA_ "SignalType" SG_ 1217 EngWrmUpAch "BLN";
BA_ "SignalLongName" SG_ 1217 EngWrmUpAch "Engine Warm Up Cycle Achieved";
BA_ "VNSigAllNodes" SG_ 1217 EngWrmUpAch 1;
BA_ "SignalType" SG_ 1217 EngIntAirTmpV "ENM";
BA_ "SignalLongName" SG_ 1217 EngIntAirTmpV "Engine Intake Air Temperature Validity";
BA_ "VNSigAllNodes" SG_ 1217 EngIntAirTmpV 1;
BA_ "SignalType" SG_ 1217 EngIntAirTmp "UNM";
BA_ "SignalLongName" SG_ 1217 EngIntAirTmp "Engine Intake Air Temperature";
BA_ "VNSigAllNodes" SG_ 1217 EngIntAirTmp 1;
BA_ "SignalType" SG_ 1217 EngCltTmpV "ENM";
BA_ "SignalLongName" SG_ 1217 EngCltTmpV "Engine Coolant Temperature Validity";
BA_ "VNSigAllNodes" SG_ 1217 EngCltTmpV 1;
BA_ "SignalType" SG_ 1217 EngCltTmp "UNM";
BA_ "SignalLongName" SG_ 1217 EngCltTmp "Engine Coolant Temperature";
BA_ "VNSigAllNodes" SG_ 1217 EngCltTmp 1;
BA_ "SignalType" SG_ 1217 BarPrsAbsV "ENM";
BA_ "SignalLongName" SG_ 1217 BarPrsAbsV "Barometric Pressure Absolute Validity";
BA_ "VNSigAllNodes" SG_ 1217 BarPrsAbsV 1;
BA_ "SignalType" SG_ 1217 BarPrsAbs "UNM";
BA_ "SignalLongName" SG_ 1217 BarPrsAbs "Barometric Pressure Absolute";
BA_ "VNSigAllNodes" SG_ 1217 BarPrsAbs 1;
BA_ "SignalType" SG_ 985 EDADS_RcmndtFwdGr "ENM";
BA_ "PacketOrder" SG_ 985 EDADS_RcmndtFwdGr 4;
BA_ "SignalLongName" SG_ 985 EDADS_RcmndtFwdGr "ECO Drive Assist Display Status : Recommended Forward Gear";
BA_ "VNSigAllNodes" SG_ 985 EDADS_RcmndtFwdGr 1;
BA_ "SignalType" SG_ 985 EDADS_CrntFwdMsdG "ENM";
BA_ "PacketOrder" SG_ 985 EDADS_CrntFwdMsdG 3;
BA_ "SignalLongName" SG_ 985 EDADS_CrntFwdMsdG "ECO Drive Assist Display Status : Current Forward Measured Gear";
BA_ "VNSigAllNodes" SG_ 985 EDADS_CrntFwdMsdG 1;
BA_ "SignalType" SG_ 985 EDADS_ShftIndStat "ENM";
BA_ "PacketOrder" SG_ 985 EDADS_ShftIndStat 2;
BA_ "SignalLongName" SG_ 985 EDADS_ShftIndStat "ECO Drive Assist Display Status : Shift Indication Status";
BA_ "VNSigAllNodes" SG_ 985 EDADS_ShftIndStat 1;
BA_ "SignalType" SG_ 985 EDADS_EcoDrvShftIO "BLN";
BA_ "PacketOrder" SG_ 985 EDADS_EcoDrvShftIO 1;
BA_ "SignalLongName" SG_ 985 EDADS_EcoDrvShftIO "ECO Drive Assist Display Status : ECO Drive Assist Shift Indication On";
BA_ "VNSigAllNodes" SG_ 985 EDADS_EcoDrvShftIO 1;
BA_ "SignalType" SG_ 1017 ACRfHiSdFldPrsV "ENM";
BA_ "SignalLongName" SG_ 1017 ACRfHiSdFldPrsV "Air Conditioning Refrigerant High Side Fluid Pressure Validity";
BA_ "VNSigAllNodes" SG_ 1017 ACRfHiSdFldPrsV 1;
BA_ "SignalType" SG_ 1017 ACRfHiSdFldPrs "UNM";
BA_ "SignalLongName" SG_ 1017 ACRfHiSdFldPrs "Air Conditioning Refrigerant High Side Fluid Pressure";
BA_ "VNSigAllNodes" SG_ 1017 ACRfHiSdFldPrs 1;
BA_ "SignalType" SG_ 1017 GenStptDtCycPtOvrAct "BLN";
BA_ "SignalLongName" SG_ 1017 GenStptDtCycPtOvrAct "Generator Setpoint Duty Cycle Powertrain Override Active";
BA_ "VNSigAllNodes" SG_ 1017 GenStptDtCycPtOvrAct 1;
BA_ "SignalType" SG_ 1017 VehTopSpdLmtMdAct "BLN";
BA_ "SignalLongName" SG_ 1017 VehTopSpdLmtMdAct "Vehicle Top Speed Limit Mode Active";
BA_ "VNSigAllNodes" SG_ 1017 VehTopSpdLmtMdAct 1;
BA_ "SignalType" SG_ 1017 VehTopSpdLmtArbVal "UNM";
BA_ "SignalLongName" SG_ 1017 VehTopSpdLmtArbVal "Vehicle Top Speed Limit Arbitrated Value";
BA_ "VNSigAllNodes" SG_ 1017 VehTopSpdLmtArbVal 1;
BA_ "SignalType" SG_ 1017 GenFldDutCycV "ENM";
BA_ "SignalLongName" SG_ 1017 GenFldDutCycV "Generator Field Duty Cycle Validity";
BA_ "VNSigAllNodes" SG_ 1017 GenFldDutCycV 1;
BA_ "SignalType" SG_ 1017 GenFldDutCyc "UNM";
BA_ "SignalLongName" SG_ 1017 GenFldDutCyc "Generator Field Duty Cycle";
BA_ "VNSigAllNodes" SG_ 1017 GenFldDutCyc 1;
BA_ "SignalType" SG_ 1017 GenFld "BLN";
BA_ "SignalLongName" SG_ 1017 GenFld "Generator Failed";
BA_ "VNSigAllNodes" SG_ 1017 GenFld 1;
BA_ "SignalType" SG_ 1017 FlInjRlCtRstOcc "BLN";
BA_ "SignalLongName" SG_ 1017 FlInjRlCtRstOcc "Fuel Injected Rolling Count Reset Occurred";
BA_ "VNSigAllNodes" SG_ 1017 FlInjRlCtRstOcc 1;
BA_ "SignalType" SG_ 1017 FlInjRlCt "UNM";
BA_ "SignalLongName" SG_ 1017 FlInjRlCt "Fuel Injected Rolling Count";
BA_ "VNSigAllNodes" SG_ 1017 FlInjRlCt 1;
BA_ "SignalType" SG_ 1017 EngSpdLmtnMdAct "BLN";
BA_ "SignalLongName" SG_ 1017 EngSpdLmtnMdAct "Engine Speed Limitation Mode Active";
BA_ "VNSigAllNodes" SG_ 1017 EngSpdLmtnMdAct 1;
BA_ "SignalType" SG_ 1017 EngOilRmnLf "UNM";
BA_ "SignalLongName" SG_ 1017 EngOilRmnLf "Engine Oil Remaining Life";
BA_ "VNSigAllNodes" SG_ 1017 EngOilRmnLf 1;
BA_ "SignalType" SG_ 1017 EngCoolFanSpd "UNM";
BA_ "SignalLongName" SG_ 1017 EngCoolFanSpd "Engine Cooling Fan Speed";
BA_ "VNSigAllNodes" SG_ 1017 EngCoolFanSpd 1;
BA_ "SignalType" SG_ 977 AutoMdSpdLmtStat "ENM";
BA_ "SignalLongName" SG_ 977 AutoMdSpdLmtStat "Auto Mode Speed Limit Status";
BA_ "VNSigAllNodes" SG_ 977 AutoMdSpdLmtStat 1;
BA_ "SignalType" SG_ 977 FuelFltLifRstPerf "BLN";
BA_ "SignalLongName" SG_ 977 FuelFltLifRstPerf "Fuel Filter Life Reset Performed";
BA_ "VNSigAllNodes" SG_ 977 FuelFltLifRstPerf 1;
BA_ "SignalType" SG_ 977 SpdLmtrSpdWrngAct "BLN";
BA_ "SignalLongName" SG_ 977 SpdLmtrSpdWrngAct "Speed Limiter/Speed Warning Active";
BA_ "VNSigAllNodes" SG_ 977 SpdLmtrSpdWrngAct 1;
BA_ "SignalType" SG_ 977 CrsCntlDrSelSpdAct "BLN";
BA_ "SignalLongName" SG_ 977 CrsCntlDrSelSpdAct "Cruise Control Driver Selected Speed Active";
BA_ "VNSigAllNodes" SG_ 977 CrsCntlDrSelSpdAct 1;
BA_ "SignalType" SG_ 977 ACCmpNrmLdGrdAld "UNM";
BA_ "SignalLongName" SG_ 977 ACCmpNrmLdGrdAld "Air Conditioning Compressor Normalized Load Gradient Allowed";
BA_ "VNSigAllNodes" SG_ 977 ACCmpNrmLdGrdAld 1;
BA_ "SignalType" SG_ 977 ACCompCmnd "ENM";
BA_ "SignalLongName" SG_ 977 ACCompCmnd "Air Conditioning Compressor Command";
BA_ "VNSigAllNodes" SG_ 977 ACCompCmnd 1;
BA_ "SignalType" SG_ 977 EngBstPrsIndV "ENM";
BA_ "SignalLongName" SG_ 977 EngBstPrsIndV "Engine Boost Pressure Indication Validity";
BA_ "VNSigAllNodes" SG_ 977 EngBstPrsIndV 1;
BA_ "SignalType" SG_ 977 EngBstPrsInd "UNM";
BA_ "SignalLongName" SG_ 977 EngBstPrsInd "Engine Boost Pressure Indication";
BA_ "VNSigAllNodes" SG_ 977 EngBstPrsInd 1;
BA_ "SignalType" SG_ 977 EngOilLifRstPerf "BLN";
BA_ "SignalLongName" SG_ 977 EngOilLifRstPerf "Engine Oil Life Reset Performed";
BA_ "VNSigAllNodes" SG_ 977 EngOilLifRstPerf 1;
BA_ "SignalType" SG_ 977 ThrPosV "ENM";
BA_ "SignalLongName" SG_ 977 ThrPosV "Throttle Position Validity";
BA_ "VNSigAllNodes" SG_ 977 ThrPosV 1;
BA_ "SignalType" SG_ 977 ThrPos "UNM";
BA_ "SignalLongName" SG_ 977 ThrPos "Throttle Position";
BA_ "VNSigAllNodes" SG_ 977 ThrPos 1;
BA_ "SignalType" SG_ 977 InstFuelConsmpRate "UNM";
BA_ "SignalLongName" SG_ 977 InstFuelConsmpRate "Instantaneous Fuel Consumption Rate";
BA_ "VNSigAllNodes" SG_ 977 InstFuelConsmpRate 1;
BA_ "SignalType" SG_ 977 EngOilStrvtnIO "BLN";
BA_ "SignalLongName" SG_ 977 EngOilStrvtnIO "Engine Oil Starvation Indication On";
BA_ "VNSigAllNodes" SG_ 977 EngOilStrvtnIO 1;
BA_ "SignalType" SG_ 977 EngNEmsnsRelMalfAct "BLN";
BA_ "SignalLongName" SG_ 977 EngNEmsnsRelMalfAct "Engine Non Emissions Related Malfunction Active";
BA_ "VNSigAllNodes" SG_ 977 EngNEmsnsRelMalfAct 1;
BA_ "SignalType" SG_ 977 EngEmsRelMalfIndReq "ENM";
BA_ "SignalLongName" SG_ 977 EngEmsRelMalfIndReq "Engine Emissions Related Malfunction Indication Request";
BA_ "VNSigAllNodes" SG_ 977 EngEmsRelMalfIndReq 1;
BA_ "SignalType" SG_ 977 EngCstFlCutAct "BLN";
BA_ "SignalLongName" SG_ 977 EngCstFlCutAct "Engine Coast Fuel Cut Off Active";
BA_ "VNSigAllNodes" SG_ 977 EngCstFlCutAct 1;
BA_ "SignalType" SG_ 977 CrsSpdLmtrDrvSelSpd "UNM";
BA_ "SignalLongName" SG_ 977 CrsSpdLmtrDrvSelSpd "Cruise and Speed Limiter Driver Selected Speed";
BA_ "VNSigAllNodes" SG_ 977 CrsSpdLmtrDrvSelSpd 1;
BA_ "SignalType" SG_ 201 PrsElvtdIdlCntlStat "ENM";
BA_ "SignalLongName" SG_ 201 PrsElvtdIdlCntlStat "Personalization Elevated Idle Control Status";
BA_ "VNSigAllNodes" SG_ 201 PrsElvtdIdlCntlStat 1;
BA_ "SignalType" SG_ 201 Eng12vStrtrMtrCmmdOn "BLN";
BA_ "SignalLongName" SG_ 201 Eng12vStrtrMtrCmmdOn "Engine 12 Volt Starter Motor Commanded On";
BA_ "VNSigAllNodes" SG_ 201 Eng12vStrtrMtrCmmdOn 1;
BA_ "SignalType" SG_ 201 EngCntrlRunCrnkTrmSt "ENM";
BA_ "SignalLongName" SG_ 201 EngCntrlRunCrnkTrmSt "Engine Controller Run Crank Terminal Status";
BA_ "VNSigAllNodes" SG_ 201 EngCntrlRunCrnkTrmSt 1;
BA_ "SignalType" SG_ 201 EngAirIntBstPrV "ENM";
BA_ "SignalLongName" SG_ 201 EngAirIntBstPrV "Engine Intake Air Boost Pressure Validity";
BA_ "VNSigAllNodes" SG_ 201 EngAirIntBstPrV 1;
BA_ "SignalType" SG_ 201 EngAirIntBstPr "SNM";
BA_ "SignalLongName" SG_ 201 EngAirIntBstPr "Engine Intake Air Boost Pressure";
BA_ "VNSigAllNodes" SG_ 201 EngAirIntBstPr 1;
BA_ "SignalType" SG_ 201 SpdLmtrSpdWrngEnbld "BLN";
BA_ "SignalLongName" SG_ 201 SpdLmtrSpdWrngEnbld "Speed Limiter/Speed Warning Enabled";
BA_ "VNSigAllNodes" SG_ 201 SpdLmtrSpdWrngEnbld 1;
BA_ "SignalType" SG_ 201 EngCylDactEvntPndg "BLN";
BA_ "SignalLongName" SG_ 201 EngCylDactEvntPndg "Engine Cylinder Deactivation Event Pending";
BA_ "VNSigAllNodes" SG_ 201 EngCylDactEvntPndg 1;
BA_ "SignalType" SG_ 201 EngCylDeactMd "ENM";
BA_ "SignalLongName" SG_ 201 EngCylDeactMd "Engine Cylinder Deactivation Mode";
BA_ "VNSigAllNodes" SG_ 201 EngCylDeactMd 1;
BA_ "SignalType" SG_ 201 RmVhStrtEngRng "BLN";
BA_ "SignalLongName" SG_ 201 RmVhStrtEngRng "Remote Vehicle Start Engine Running";
BA_ "VNSigAllNodes" SG_ 201 RmVhStrtEngRng 1;
BA_ "SignalType" SG_ 201 PFEngSpdCmndSpcd "BLN";
BA_ "SignalLongName" SG_ 201 PFEngSpdCmndSpcd "Platform Engine Speed Command Superceded";
BA_ "VNSigAllNodes" SG_ 201 PFEngSpdCmndSpcd 1;
BA_ "SignalType" SG_ 201 DrThrtlOvrrdDetProtVal "UNM";
BA_ "SignalLongName" SG_ 201 DrThrtlOvrrdDetProtVal "Driver Throttle Override Detected Protection Value";
BA_ "VNSigAllNodes" SG_ 201 DrThrtlOvrrdDetProtVal 1;
BA_ "SignalType" SG_ 201 DrThrtlOvrdDetAlvRlCnt "UNM";
BA_ "SignalLongName" SG_ 201 DrThrtlOvrdDetAlvRlCnt "Driver Throttle Override Detection Alive Rolling Count";
BA_ "VNSigAllNodes" SG_ 201 DrThrtlOvrdDetAlvRlCnt 1;
BA_ "SignalType" SG_ 201 PltfrmEngSpdCmdInhtRq "ENM";
BA_ "SignalLongName" SG_ 201 PltfrmEngSpdCmdInhtRq "Platform Engine Speed Command Inhibit Request";
BA_ "VNSigAllNodes" SG_ 201 PltfrmEngSpdCmdInhtRq 1;
BA_ "SignalType" SG_ 201 PT_BrkPedDscrtInpStatV "ENM";
BA_ "SignalLongName" SG_ 201 PT_BrkPedDscrtInpStatV "Powertrain Brake Pedal Discrete Input Status Validity";
BA_ "VNSigAllNodes" SG_ 201 PT_BrkPedDscrtInpStatV 1;
BA_ "SignalType" SG_ 201 PT_BrkPedDscrtInpStat "ENM";
BA_ "SignalLongName" SG_ 201 PT_BrkPedDscrtInpStat "Powertrain Brake Pedal Discrete Input Status";
BA_ "VNSigAllNodes" SG_ 201 PT_BrkPedDscrtInpStat 1;
BA_ "SignalType" SG_ 201 AccActPos "UNM";
BA_ "SignalLongName" SG_ 201 AccActPos "Accelerator Actual Position";
BA_ "VNSigAllNodes" SG_ 201 AccActPos 1;
BA_ "SignalType" SG_ 201 CrsCntEnbld "BLN";
BA_ "SignalLongName" SG_ 201 CrsCntEnbld "Cruise Control Enabled";
BA_ "VNSigAllNodes" SG_ 201 CrsCntEnbld 1;
BA_ "SignalType" SG_ 201 CrsCntAtv "BLN";
BA_ "SignalLongName" SG_ 201 CrsCntAtv "Cruise Control Active";
BA_ "VNSigAllNodes" SG_ 201 CrsCntAtv 1;
BA_ "SignalType" SG_ 201 DrvThrottlOvrrdDet "BLN";
BA_ "SignalLongName" SG_ 201 DrvThrottlOvrrdDet "Driver Throttle Override Detected";
BA_ "VNSigAllNodes" SG_ 201 DrvThrottlOvrrdDet 1;
BA_ "SignalType" SG_ 201 PT_CrnkAct "BLN";
BA_ "SignalLongName" SG_ 201 PT_CrnkAct "Powertrain Crank Active";
BA_ "VNSigAllNodes" SG_ 201 PT_CrnkAct 1;
BA_ "SignalType" SG_ 201 PTRunAbrt "BLN";
BA_ "SignalLongName" SG_ 201 PTRunAbrt "Powertrain Run Aborted";
BA_ "VNSigAllNodes" SG_ 201 PTRunAbrt 1;
BA_ "SignalType" SG_ 201 PTO_PT_RunAbrtd "BLN";
BA_ "SignalLongName" SG_ 201 PTO_PT_RunAbrtd "Power Take Off Powertrain Run Aborted";
BA_ "VNSigAllNodes" SG_ 201 PTO_PT_RunAbrtd 1;
BA_ "SignalType" SG_ 201 PTCrnkAbrted "BLN";
BA_ "SignalLongName" SG_ 201 PTCrnkAbrted "Powertrain Crank Aborted";
BA_ "VNSigAllNodes" SG_ 201 PTCrnkAbrted 1;
BA_ "SignalType" SG_ 201 EngSpdStat "ENM";
BA_ "SignalLongName" SG_ 201 EngSpdStat "Engine Speed Status";
BA_ "VNSigAllNodes" SG_ 201 EngSpdStat 1;
BA_ "SignalType" SG_ 201 EngSpd "UNM";
BA_ "SignalLongName" SG_ 201 EngSpd "Engine Speed";
BA_ "VNSigAllNodes" SG_ 201 EngSpd 1;
BA_ "SignalType" SG_ 201 EngRunAtv "BLN";
BA_ "SignalLongName" SG_ 201 EngRunAtv "Engine Run Active";
BA_ "VNSigAllNodes" SG_ 201 EngRunAtv 1;
BA_ "SignalType" SG_ 201 EngIdlAtv "BLN";
BA_ "SignalLongName" SG_ 201 EngIdlAtv "Engine Idle Active";
BA_ "VNSigAllNodes" SG_ 201 EngIdlAtv 1;
BA_ "SignalType" SG_ 201 AccActPosV "ENM";
BA_ "SignalLongName" SG_ 201 AccActPosV "Accelerator Actual Position Validity";
BA_ "VNSigAllNodes" SG_ 201 AccActPosV 1;
BA_ "SignalType" SG_ 501 EngRecDwnshftIO "BLN";
BA_ "SignalLongName" SG_ 501 EngRecDwnshftIO "Engine Recommended Downshift Indication On";
BA_ "VNSigAllNodes" SG_ 501 EngRecDwnshftIO 1;
BA_ "SignalType" SG_ 501 TrnsPattSelEcnMdOCm "BLN";
BA_ "SignalLongName" SG_ 501 TrnsPattSelEcnMdOCm "Transmission Pattern Selection Economy Mode Override Commanded";
BA_ "VNSigAllNodes" SG_ 501 TrnsPattSelEcnMdOCm 1;
BA_ "SignalType" SG_ 501 CltStartSwAtvV "ENM";
BA_ "SignalLongName" SG_ 501 CltStartSwAtvV "Clutch Start Switch Active Validity";
BA_ "VNSigAllNodes" SG_ 501 CltStartSwAtvV 1;
BA_ "SignalType" SG_ 501 CltStartSwAtv "BLN";
BA_ "SignalLongName" SG_ 501 CltStartSwAtv "Clutch Start Switch Active";
BA_ "GenSigStartValue" SG_ 501 CltStartSwAtv 1;
BA_ "VNSigAllNodes" SG_ 501 CltStartSwAtv 1;
BA_ "SignalType" SG_ 501 CltchPdlActPosV "ENM";
BA_ "SignalLongName" SG_ 501 CltchPdlActPosV "Clutch Pedal Actual Position Validity";
BA_ "VNSigAllNodes" SG_ 501 CltchPdlActPosV 1;
BA_ "SignalType" SG_ 501 CltchPdlActPos "UNM";
BA_ "SignalLongName" SG_ 501 CltchPdlActPos "Clutch Pedal Actual Position";
BA_ "VNSigAllNodes" SG_ 501 CltchPdlActPos 1;
BA_ "SignalType" SG_ 501 TrnsEngdStateV "ENM";
BA_ "SignalLongName" SG_ 501 TrnsEngdStateV "Transmission Engaged State Validity";
BA_ "VNSigAllNodes" SG_ 501 TrnsEngdStateV 1;
BA_ "SignalType" SG_ 501 TrnsEngdState "ENM";
BA_ "SignalLongName" SG_ 501 TrnsEngdState "Transmission Engaged State";
BA_ "VNSigAllNodes" SG_ 501 TrnsEngdState 1;
BA_ "SignalType" SG_ 501 TrnsShftLvrLckRqd "BLN";
BA_ "SignalLongName" SG_ 501 TrnsShftLvrLckRqd "Transmission Shift Lever Lock Requested";
BA_ "VNSigAllNodes" SG_ 501 TrnsShftLvrLckRqd 1;
BA_ "SignalType" SG_ 501 TransTUDMdStat "ENM";
BA_ "SignalLongName" SG_ 501 TransTUDMdStat "Transmission Tap Up/Tap Down Mode Status";
BA_ "VNSigAllNodes" SG_ 501 TransTUDMdStat 1;
BA_ "SignalType" SG_ 501 TrnCrpMdAtv "BLN";
BA_ "SignalLongName" SG_ 501 TrnCrpMdAtv "Transmission Creep Mode Active";
BA_ "VNSigAllNodes" SG_ 501 TrnCrpMdAtv 1;
BA_ "SignalType" SG_ 501 TrnsSkpShftIO "BLN";
BA_ "SignalLongName" SG_ 501 TrnsSkpShftIO "Transmission Skip Shift Indication On";
BA_ "VNSigAllNodes" SG_ 501 TrnsSkpShftIO 1;
BA_ "SignalType" SG_ 501 TrnsSftMdStat "ENM";
BA_ "SignalLongName" SG_ 501 TrnsSftMdStat "Transmission Shift Mode Status";
BA_ "VNSigAllNodes" SG_ 501 TrnsSftMdStat 1;
BA_ "SignalType" SG_ 501 TrnsRngInhbtStat "ENM";
BA_ "SignalLongName" SG_ 501 TrnsRngInhbtStat "Transmission Range Inhibit Status";
BA_ "VNSigAllNodes" SG_ 501 TrnsRngInhbtStat 1;
BA_ "SignalType" SG_ 501 TopTrvlCltchSwActV "ENM";
BA_ "SignalLongName" SG_ 501 TopTrvlCltchSwActV "Top of Travel Clutch Switch Active Validity";
BA_ "VNSigAllNodes" SG_ 501 TopTrvlCltchSwActV 1;
BA_ "SignalType" SG_ 501 TopTrvlCltchSwAct "BLN";
BA_ "SignalLongName" SG_ 501 TopTrvlCltchSwAct "Top of Travel Clutch Switch Active";
BA_ "VNSigAllNodes" SG_ 501 TopTrvlCltchSwAct 1;
BA_ "SignalType" SG_ 501 EngRecmndUpshftIO "BLN";
BA_ "SignalLongName" SG_ 501 EngRecmndUpshftIO "Engine Recommended Upshift Indication On";
BA_ "VNSigAllNodes" SG_ 501 EngRecmndUpshftIO 1;
BA_ "SignalType" SG_ 501 DrvtShftCntrlTrgtGear "ENM";
BA_ "SignalLongName" SG_ 501 DrvtShftCntrlTrgtGear "Driver Shift Control Target Gear";
BA_ "VNSigAllNodes" SG_ 501 DrvtShftCntrlTrgtGear 1;
BA_ "SignalType" SG_ 501 DrShftCntrlReqDndIO "BLN";
BA_ "SignalLongName" SG_ 501 DrShftCntrlReqDndIO "Driver Shift Control Request Denied Indication On";
BA_ "VNSigAllNodes" SG_ 501 DrShftCntrlReqDndIO 1;
BA_ "SignalType" SG_ 501 TrnShftPtrnActStat "ENM";
BA_ "SignalLongName" SG_ 501 TrnShftPtrnActStat "Transmission Shift Pattern Active Status";
BA_ "VNSigAllNodes" SG_ 501 TrnShftPtrnActStat 1;
BA_ "SignalType" SG_ 501 TrnsFldPrsPrsnt "BLN";
BA_ "SignalLongName" SG_ 501 TrnsFldPrsPrsnt "Transmission Fluid Pressure Present";
BA_ "VNSigAllNodes" SG_ 501 TrnsFldPrsPrsnt 1;
BA_ "SignalType" SG_ 501 TrnsShftLvrPos "ENM";
BA_ "SignalLongName" SG_ 501 TrnsShftLvrPos "Transmission Shift Lever Position";
BA_ "VNSigAllNodes" SG_ 501 TrnsShftLvrPos 1;
BA_ "SignalType" SG_ 501 TrnsShftLvrPosV "ENM";
BA_ "SignalLongName" SG_ 501 TrnsShftLvrPosV "Transmission Shift Lever Position Validity";
BA_ "VNSigAllNodes" SG_ 501 TrnsShftLvrPosV 1;
BA_ "SignalType" SG_ 501 TrnsTrqCnvCltCmndMd "ENM";
BA_ "SignalLongName" SG_ 501 TrnsTrqCnvCltCmndMd "Transmission Torque Converter Clutch Commanded Mode";
BA_ "GenSigStartValue" SG_ 501 TrnsTrqCnvCltCmndMd 7;
BA_ "VNSigAllNodes" SG_ 501 TrnsTrqCnvCltCmndMd 1;
BA_ "SignalType" SG_ 501 AutoTransComndGear "ENM";
BA_ "SignalLongName" SG_ 501 AutoTransComndGear "Automatic Transmission Commanded Gear";
BA_ "GenSigStartValue" SG_ 501 AutoTransComndGear 15;
BA_ "VNSigAllNodes" SG_ 501 AutoTransComndGear 1;
BA_ "SignalType" SG_ 501 AutoTransGrSftDirect "ENM";
BA_ "SignalLongName" SG_ 501 AutoTransGrSftDirect "Automatic Transmission Gear Shift Direction";
BA_ "VNSigAllNodes" SG_ 501 AutoTransGrSftDirect 1;
BA_ "SignalType" SG_ 501 TransEstGear "ENM";
BA_ "SignalLongName" SG_ 501 TransEstGear "Transmission Estimated Gear";
BA_ "GenSigStartValue" SG_ 501 TransEstGear 15;
BA_ "VNSigAllNodes" SG_ 501 TransEstGear 1;
BA_ "SignalType" SG_ 501 TransEstGearV "ENM";
BA_ "SignalLongName" SG_ 501 TransEstGearV "Transmission Estimated Gear Validity";
BA_ "VNSigAllNodes" SG_ 501 TransEstGearV 1;
BA_ "SignalType" SG_ 1225 TCTPIR_TnsEsClCDwT "UNM";
BA_ "PacketOrder" SG_ 1225 TCTPIR_TnsEsClCDwT 3;
BA_ "SignalLongName" SG_ 1225 TCTPIR_TnsEsClCDwT "Transmission Clutch Thermal Protection Indication Request : Transmission Estimated Clutch Cool-down Temperature Target Display";
BA_ "VNSigAllNodes" SG_ 1225 TCTPIR_TnsEsClCDwT 1;
BA_ "SignalType" SG_ 1225 TCTPIR_TnsEsClTmpD "UNM";
BA_ "PacketOrder" SG_ 1225 TCTPIR_TnsEsClTmpD 2;
BA_ "SignalLongName" SG_ 1225 TCTPIR_TnsEsClTmpD "Transmission Clutch Thermal Protection Indication Request : Transmission Estimated Clutch Temperature Display";
BA_ "VNSigAllNodes" SG_ 1225 TCTPIR_TnsEsClTmpD 1;
BA_ "SignalType" SG_ 1225 TCTPIR_DrvNotfn "ENM";
BA_ "PacketOrder" SG_ 1225 TCTPIR_DrvNotfn 1;
BA_ "SignalLongName" SG_ 1225 TCTPIR_DrvNotfn "Transmission Clutch Thermal Protection Indication Request : Driver Notification";
BA_ "VNSigAllNodes" SG_ 1225 TCTPIR_DrvNotfn 1;
BA_ "SignalType" SG_ 1225 GrdBrkgAct "BLN";
BA_ "SignalLongName" SG_ 1225 GrdBrkgAct "Grade Braking Active";
BA_ "VNSigAllNodes" SG_ 1225 GrdBrkgAct 1;
BA_ "SignalType" SG_ 1225 RrPTCoolFanRatFltStat "ENM";
BA_ "SignalLongName" SG_ 1225 RrPTCoolFanRatFltStat "Rear Powertrain Cooling Fan Rationality Fault Status";
BA_ "VNSigAllNodes" SG_ 1225 RrPTCoolFanRatFltStat 1;
BA_ "SignalType" SG_ 1225 TrnsThrmlMngmntStat "ENM";
BA_ "SignalLongName" SG_ 1225 TrnsThrmlMngmntStat "Transmission Thermal Management Status";
BA_ "VNSigAllNodes" SG_ 1225 TrnsThrmlMngmntStat 1;
BA_ "SignalType" SG_ 1225 TrnsNEmsRltMalfActv "BLN";
BA_ "SignalLongName" SG_ 1225 TrnsNEmsRltMalfActv "Transmission Non Emissions Related Malfunction Active";
BA_ "VNSigAllNodes" SG_ 1225 TrnsNEmsRltMalfActv 1;
BA_ "SignalType" SG_ 1225 TransOilTempSensPres "BLN";
BA_ "SignalLongName" SG_ 1225 TransOilTempSensPres "Transmission Oil Temperature Sensor Present";
BA_ "VNSigAllNodes" SG_ 1225 TransOilTempSensPres 1;
BA_ "SignalType" SG_ 1225 TrnEmsMlfAtv "BLN";
BA_ "SignalLongName" SG_ 1225 TrnEmsMlfAtv "Transmission Emissions Related Malfunction Active";
BA_ "VNSigAllNodes" SG_ 1225 TrnEmsMlfAtv 1;
BA_ "SignalType" SG_ 1225 TrnOilTmp "UNM";
BA_ "SignalLongName" SG_ 1225 TrnOilTmp "Transmission Oil Temperature";
BA_ "VNSigAllNodes" SG_ 1225 TrnOilTmp 1;
BA_ "SignalType" SG_ 1225 TrnOilTmpV "ENM";
BA_ "SignalLongName" SG_ 1225 TrnOilTmpV "Transmission Oil Temperature Validity";
BA_ "VNSigAllNodes" SG_ 1225 TrnOilTmpV 1;
BA_ "SignalType" SG_ 1225 TERDTC_SysDes "ENM";
BA_ "PacketOrder" SG_ 1225 TERDTC_SysDes 1;
BA_ "SignalLongName" SG_ 1225 TERDTC_SysDes "Transmission Emissions Related DTC : System Designator";
BA_ "VNSigAllNodes" SG_ 1225 TERDTC_SysDes 1;
BA_ "SignalType" SG_ 1225 TERDTC_CdNum "UNM";
BA_ "PacketOrder" SG_ 1225 TERDTC_CdNum 2;
BA_ "SignalLongName" SG_ 1225 TERDTC_CdNum "Transmission Emissions Related DTC : Code Number";
BA_ "VNSigAllNodes" SG_ 1225 TERDTC_CdNum 1;
BA_ "SignalType" SG_ 409 TrnsAliveRC_199 "UNM";
BA_ "SignalLongName" SG_ 409 TrnsAliveRC_199 "Transmission Alive Rolling Count 199";
BA_ "VNSigAllNodes" SG_ 409 TrnsAliveRC_199 1;
BA_ "SignalType" SG_ 409 TDslPrtFltrIdlRgtnMdAtv "BLN";
BA_ "SignalLongName" SG_ 409 TDslPrtFltrIdlRgtnMdAtv "Transmission Diesel Particulate Filter Idle Regeneration Mode Active";
BA_ "VNSigAllNodes" SG_ 409 TDslPrtFltrIdlRgtnMdAtv 1;
BA_ "SignalType" SG_ 409 TransMinVoltReq "UNM";
BA_ "SignalLongName" SG_ 409 TransMinVoltReq "Transmission Minimum Voltage Request";
BA_ "VNSigAllNodes" SG_ 409 TransMinVoltReq 1;
BA_ "SignalType" SG_ 409 TransVehTopSpdLim "UNM";
BA_ "SignalLongName" SG_ 409 TransVehTopSpdLim "Transmission Vehicle Top Speed Limit Value";
BA_ "VNSigAllNodes" SG_ 409 TransVehTopSpdLim 1;
BA_ "SignalType" SG_ 409 TrnsTrqRqProt "UNM";
BA_ "SignalLongName" SG_ 409 TrnsTrqRqProt "Transmission Torque Request Protection";
BA_ "VNSigAllNodes" SG_ 409 TrnsTrqRqProt 1;
BA_ "SignalType" SG_ 409 TTRLT_TorqReqVal "UNM";
BA_ "PacketOrder" SG_ 409 TTRLT_TorqReqVal 3;
BA_ "SignalLongName" SG_ 409 TTRLT_TorqReqVal "Transmission Torque Request Long-term : Torque Request Value";
BA_ "VNSigAllNodes" SG_ 409 TTRLT_TorqReqVal 1;
BA_ "SignalType" SG_ 409 TTRLT_TqRdnRlznSgg "ENM";
BA_ "PacketOrder" SG_ 409 TTRLT_TqRdnRlznSgg 2;
BA_ "SignalLongName" SG_ 409 TTRLT_TqRdnRlznSgg "Transmission Torque Request Long-term : Torque Reduction Realization Suggestion";
BA_ "VNSigAllNodes" SG_ 409 TTRLT_TqRdnRlznSgg 1;
BA_ "SignalType" SG_ 409 TTRLT_TorqInvntnTyp "ENM";
BA_ "PacketOrder" SG_ 409 TTRLT_TorqInvntnTyp 1;
BA_ "SignalLongName" SG_ 409 TTRLT_TorqInvntnTyp "Transmission Torque Request Long-term : Torque Intervention Type";
BA_ "VNSigAllNodes" SG_ 409 TTRLT_TorqInvntnTyp 1;
BA_ "SignalType" SG_ 409 TTRST_TorqReqVal "UNM";
BA_ "PacketOrder" SG_ 409 TTRST_TorqReqVal 2;
BA_ "SignalLongName" SG_ 409 TTRST_TorqReqVal "Transmission Torque Request Short-term : Torque Request Value";
BA_ "VNSigAllNodes" SG_ 409 TTRST_TorqReqVal 1;
BA_ "SignalType" SG_ 409 TTRST_TorqInvntnTyp "ENM";
BA_ "PacketOrder" SG_ 409 TTRST_TorqInvntnTyp 1;
BA_ "SignalLongName" SG_ 409 TTRST_TorqInvntnTyp "Transmission Torque Request Short-term : Torque Intervention Type";
BA_ "VNSigAllNodes" SG_ 409 TTRST_TorqInvntnTyp 1;
BA_ "SignalType" SG_ 413 TrnsCyDactTransStat "ENM";
BA_ "SignalLongName" SG_ 413 TrnsCyDactTransStat "Transmission Cylinder Deactivation Transition Status";
BA_ "VNSigAllNodes" SG_ 413 TrnsCyDactTransStat 1;
BA_ "SignalType" SG_ 413 EngBrkDsblReqd "BLN";
BA_ "SignalLongName" SG_ 413 EngBrkDsblReqd "Engine Brake Disable Requested";
BA_ "VNSigAllNodes" SG_ 413 EngBrkDsblReqd 1;
BA_ "SignalType" SG_ 413 TransNtrlCntrlMdStat "ENM";
BA_ "SignalLongName" SG_ 413 TransNtrlCntrlMdStat "Transmission Neutral Control Mode Status";
BA_ "VNSigAllNodes" SG_ 413 TransNtrlCntrlMdStat 1;
BA_ "SignalType" SG_ 413 TrnsRtoCntlSysFlt "BLN";
BA_ "SignalLongName" SG_ 413 TrnsRtoCntlSysFlt "Transmission Ratio Control System Fault";
BA_ "VNSigAllNodes" SG_ 413 TrnsRtoCntlSysFlt 1;
BA_ "SignalType" SG_ 413 TrnTrbAngVl "UNM";
BA_ "SignalLongName" SG_ 413 TrnTrbAngVl "Transmission Turbine Angular Velocity";
BA_ "VNSigAllNodes" SG_ 413 TrnTrbAngVl 1;
BA_ "SignalType" SG_ 413 TrnTrbAngVlV "ENM";
BA_ "SignalLongName" SG_ 413 TrnTrbAngVlV "Transmission Turbine Angular Velocity Validity";
BA_ "VNSigAllNodes" SG_ 413 TrnTrbAngVlV 1;
BA_ "SignalType" SG_ 413 TrnGrRat "UNM";
BA_ "SignalLongName" SG_ 413 TrnGrRat "Transmission Gear Ratio";
BA_ "VNSigAllNodes" SG_ 413 TrnGrRat 1;
BA_ "SignalType" SG_ 413 TrnGrRatV "ENM";
BA_ "SignalLongName" SG_ 413 TrnGrRatV "Transmission Gear Ratio Validity";
BA_ "VNSigAllNodes" SG_ 413 TrnGrRatV 1;
BA_ "SignalType" SG_ 413 TrnPrfAlgShfAtv "BLN";
BA_ "SignalLongName" SG_ 413 TrnPrfAlgShfAtv "Transmission Performance Algorithm Shift Mode Active";
BA_ "VNSigAllNodes" SG_ 413 TrnPrfAlgShfAtv 1;
BA_ "SignalType" SG_ 413 TrnsAliveRC "UNM";
BA_ "SignalLongName" SG_ 413 TrnsAliveRC "Transmission Alive Rolling Count";
BA_ "VNSigAllNodes" SG_ 413 TrnsAliveRC 1;
BA_ "SignalType" SG_ 413 TrnsEngSpdRqProt "UNM";
BA_ "SignalLongName" SG_ 413 TrnsEngSpdRqProt "Transmission Engine Speed Request Protection";
BA_ "VNSigAllNodes" SG_ 413 TrnsEngSpdRqProt 1;
BA_ "SignalType" SG_ 413 TESR_EngSpdCntlRsp "ENM";
BA_ "PacketOrder" SG_ 413 TESR_EngSpdCntlRsp 2;
BA_ "SignalLongName" SG_ 413 TESR_EngSpdCntlRsp "Transmission Engine Speed Request : Engine Speed Control Response";
BA_ "VNSigAllNodes" SG_ 413 TESR_EngSpdCntlRsp 1;
BA_ "SignalType" SG_ 413 TESR_EngSpdRqVal "UNM";
BA_ "PacketOrder" SG_ 413 TESR_EngSpdRqVal 3;
BA_ "SignalLongName" SG_ 413 TESR_EngSpdRqVal "Transmission Engine Speed Request : Engine Speed Request Value";
BA_ "VNSigAllNodes" SG_ 413 TESR_EngSpdRqVal 1;
BA_ "SignalType" SG_ 413 TESR_EngSpdIntTyp "ENM";
BA_ "PacketOrder" SG_ 413 TESR_EngSpdIntTyp 1;
BA_ "SignalLongName" SG_ 413 TESR_EngSpdIntTyp "Transmission Engine Speed Request : Engine Speed Intervention Type";
BA_ "VNSigAllNodes" SG_ 413 TESR_EngSpdIntTyp 1;
BA_ "SignalType" SG_ 413 TrnsGrgShftAct "BLN";
BA_ "SignalLongName" SG_ 413 TrnsGrgShftAct "Transmission Garage Shift Active";
BA_ "VNSigAllNodes" SG_ 413 TrnsGrgShftAct 1;
BA_ "VNSigSLHSSharedDiagnostic" SG_ 257 DgnInf 1;
BA_ "SignalType" SG_ 257 DgnInf "UNM";
BA_ "SignalLongName" SG_ 257 DgnInf "Diagnostic Information";
BA_ "VNSigAllNodes" SG_ 257 DgnInf 1;
BA_ "VNSigSLHSSharedDiagnostic" SG_ 2015 DgnInf 1;
BA_ "SignalType" SG_ 2015 DgnInf "UNM";
BA_ "SignalLongName" SG_ 2015 DgnInf "Diagnostic Information";
BA_ "VNSigAllNodes" SG_ 2015 DgnInf 1;
BA_ "VNSigSLHSSharedDiagnostic" SG_ 2016 DgnInf 1;
BA_ "SignalType" SG_ 2016 DgnInf "UNM";
BA_ "SignalLongName" SG_ 2016 DgnInf "Diagnostic Information";
BA_ "VNSigAllNodes" SG_ 2016 DgnInf 1;
BA_ "SignalType" SG_ 197 WRSLNDWhlDisTpRC "UNM";
BA_ "PacketOrder" SG_ 197 WRSLNDWhlDisTpRC 1;
BA_ "SignalLongName" SG_ 197 WRSLNDWhlDisTpRC "Wheel Rotational Status Left Non Driven : Wheel Distance Timestamp Rollover Counter";
BA_ "VNSigAllNodes" SG_ 197 WRSLNDWhlDisTpRC 1;
BA_ "SignalType" SG_ 197 WRSLNDWhlRotStRst "BLN";
BA_ "PacketOrder" SG_ 197 WRSLNDWhlRotStRst 3;
BA_ "SignalLongName" SG_ 197 WRSLNDWhlRotStRst "Wheel Rotational Status Left Non Driven : Wheel Rotational Status Reset Occurred";
BA_ "VNSigAllNodes" SG_ 197 WRSLNDWhlRotStRst 1;
BA_ "SignalType" SG_ 197 WRSLNDWhlDistVal "ENM";
BA_ "PacketOrder" SG_ 197 WRSLNDWhlDistVal 4;
BA_ "SignalLongName" SG_ 197 WRSLNDWhlDistVal "Wheel Rotational Status Left Non Driven : Wheel Distance Validity";
BA_ "VNSigAllNodes" SG_ 197 WRSLNDWhlDistVal 1;
BA_ "SignalType" SG_ 197 WRSLNDWhlDistTstm "UNM";
BA_ "PacketOrder" SG_ 197 WRSLNDWhlDistTstm 6;
BA_ "SignalLongName" SG_ 197 WRSLNDWhlDistTstm "Wheel Rotational Status Left Non Driven : Wheel Distance Timestamp";
BA_ "VNSigAllNodes" SG_ 197 WRSLNDWhlDistTstm 1;
BA_ "SignalType" SG_ 197 WRSLNDWhlDistPCntr "UNM";
BA_ "PacketOrder" SG_ 197 WRSLNDWhlDistPCntr 5;
BA_ "SignalLongName" SG_ 197 WRSLNDWhlDistPCntr "Wheel Rotational Status Left Non Driven : Wheel Distance Pulse Counter";
BA_ "VNSigAllNodes" SG_ 197 WRSLNDWhlDistPCntr 1;
BA_ "SignalType" SG_ 197 WRSLNDSeqNum "UNM";
BA_ "PacketOrder" SG_ 197 WRSLNDSeqNum 2;
BA_ "SignalLongName" SG_ 197 WRSLNDSeqNum "Wheel Rotational Status Left Non Driven : Sequence Number";
BA_ "VNSigAllNodes" SG_ 197 WRSLNDSeqNum 1;
BA_ "SignalType" SG_ 197 WRSRNDWhlDisTpRC "UNM";
BA_ "PacketOrder" SG_ 197 WRSRNDWhlDisTpRC 1;
BA_ "SignalLongName" SG_ 197 WRSRNDWhlDisTpRC "Wheel Rotational Status Right Non Driven : Wheel Distance Timestamp Rollover Counter";
BA_ "VNSigAllNodes" SG_ 197 WRSRNDWhlDisTpRC 1;
BA_ "SignalType" SG_ 197 WRSRNDWhlRotStRst "BLN";
BA_ "PacketOrder" SG_ 197 WRSRNDWhlRotStRst 3;
BA_ "SignalLongName" SG_ 197 WRSRNDWhlRotStRst "Wheel Rotational Status Right Non Driven : Wheel Rotational Status Reset Occurred";
BA_ "VNSigAllNodes" SG_ 197 WRSRNDWhlRotStRst 1;
BA_ "SignalType" SG_ 197 WRSRNDWhlDistVal "ENM";
BA_ "PacketOrder" SG_ 197 WRSRNDWhlDistVal 4;
BA_ "SignalLongName" SG_ 197 WRSRNDWhlDistVal "Wheel Rotational Status Right Non Driven : Wheel Distance Validity";
BA_ "VNSigAllNodes" SG_ 197 WRSRNDWhlDistVal 1;
BA_ "SignalType" SG_ 197 WRSRNDWhlDistTstm "UNM";
BA_ "PacketOrder" SG_ 197 WRSRNDWhlDistTstm 6;
BA_ "SignalLongName" SG_ 197 WRSRNDWhlDistTstm "Wheel Rotational Status Right Non Driven : Wheel Distance Timestamp";
BA_ "VNSigAllNodes" SG_ 197 WRSRNDWhlDistTstm 1;
BA_ "SignalType" SG_ 197 WRSRNDWhlDistPCntr "UNM";
BA_ "PacketOrder" SG_ 197 WRSRNDWhlDistPCntr 5;
BA_ "SignalLongName" SG_ 197 WRSRNDWhlDistPCntr "Wheel Rotational Status Right Non Driven : Wheel Distance Pulse Counter";
BA_ "VNSigAllNodes" SG_ 197 WRSRNDWhlDistPCntr 1;
BA_ "SignalType" SG_ 197 WRSRNDSeqNum "UNM";
BA_ "PacketOrder" SG_ 197 WRSRNDSeqNum 2;
BA_ "SignalLongName" SG_ 197 WRSRNDSeqNum "Wheel Rotational Status Right Non Driven : Sequence Number";
BA_ "VNSigAllNodes" SG_ 197 WRSRNDSeqNum 1;
BA_ "SignalType" SG_ 249 TrnsDrvlneTqShpDisRq "BLN";
BA_ "SignalLongName" SG_ 249 TrnsDrvlneTqShpDisRq "Transmission Driveline Torque Shaping Disable Requested";
BA_ "VNSigAllNodes" SG_ 249 TrnsDrvlneTqShpDisRq 1;
BA_ "SignalType" SG_ 249 TnCCVehSpShftEvTh "UNM";
BA_ "SignalLongName" SG_ 249 TnCCVehSpShftEvTh "Transmission Cruise Control Vehicle Speed Shift Event Threshold";
BA_ "VNSigAllNodes" SG_ 249 TnCCVehSpShftEvTh 1;
BA_ "SignalType" SG_ 249 TrnsOtptRotRC "UNM";
BA_ "SignalLongName" SG_ 249 TrnsOtptRotRC "Transmission Output Rotations Rolling Count";
BA_ "VNSigAllNodes" SG_ 249 TrnsOtptRotRC 1;
BA_ "SignalType" SG_ 249 TrnsOtptRotRCRstOcc "BLN";
BA_ "SignalLongName" SG_ 249 TrnsOtptRotRCRstOcc "Transmission Output Rotations Rolling Count Reset Occurred";
BA_ "VNSigAllNodes" SG_ 249 TrnsOtptRotRCRstOcc 1;
BA_ "SignalType" SG_ 249 TrnsOtptRotRCV "ENM";
BA_ "SignalLongName" SG_ 249 TrnsOtptRotRCV "Transmission Output Rotations Rolling Count Validity";
BA_ "VNSigAllNodes" SG_ 249 TrnsOtptRotRCV 1;
BA_ "SignalType" SG_ 249 TrnsOtptShftAngVelSnrPr "BLN";
BA_ "SignalLongName" SG_ 249 TrnsOtptShftAngVelSnrPr "Transmission Output Shaft Angular Velocity Sensor Present";
BA_ "VNSigAllNodes" SG_ 249 TrnsOtptShftAngVelSnrPr 1;
BA_ "SignalType" SG_ 249 TrnsOutShftAngVel "UNM";
BA_ "SignalLongName" SG_ 249 TrnsOutShftAngVel "Transmission Output Shaft Angular Velocity";
BA_ "VNSigAllNodes" SG_ 249 TrnsOutShftAngVel 1;
BA_ "SignalType" SG_ 249 TrnsOutShftAngVelV "ENM";
BA_ "SignalLongName" SG_ 249 TrnsOutShftAngVelV "Transmission Output Shaft Angular Velocity Validity";
BA_ "VNSigAllNodes" SG_ 249 TrnsOutShftAngVelV 1;
BA_ "SignalType" SG_ 249 TrnsOvrallEstTorqRatio "SNM";
BA_ "SignalLongName" SG_ 249 TrnsOvrallEstTorqRatio "Transmission Overall Estimated Torque Ratio";
BA_ "VNSigAllNodes" SG_ 249 TrnsOvrallEstTorqRatio 1;
BA_ "SignalType" SG_ 249 TrnsOvrallEstTorqRatioV "ENM";
BA_ "SignalLongName" SG_ 249 TrnsOvrallEstTorqRatioV "Transmission Overall Estimated Torque Ratio Validity";
BA_ "VNSigAllNodes" SG_ 249 TrnsOvrallEstTorqRatioV 1;
BA_REL_ "GenSigSuprvResp" BU_SG_REL_ PTO_HS SG_ 493 EngRunng 1;
BA_REL_ "GenSigTimeoutMsg" BU_SG_REL_ PTO_HS SG_ 493 EngRunng 493;
BA_REL_ "GenSigTimeoutTime" BU_SG_REL_ PTO_HS SG_ 493 EngRunng 250;
BA_REL_ "GenSigSuprvResp" BU_SG_REL_ ICCM_OBD_HS SG_ 493 EngRunng 1;
BA_REL_ "GenSigTimeoutMsg" BU_SG_REL_ ICCM_OBD_HS SG_ 493 EngRunng 493;
BA_REL_ "GenSigTimeoutTime" BU_SG_REL_ ICCM_OBD_HS SG_ 493 EngRunng 250;
BA_REL_ "GenSigSuprvResp" BU_SG_REL_ ICCM_HS SG_ 493 EngRunng 1;
BA_REL_ "GenSigTimeoutMsg" BU_SG_REL_ ICCM_HS SG_ 493 EngRunng 493;
BA_REL_ "GenSigTimeoutTime" BU_SG_REL_ ICCM_HS SG_ 493 EngRunng 250;
BA_REL_ "GenSigSuprvResp" BU_SG_REL_ FSCM_ITBC_HS SG_ 493 EngRunng 1;
BA_REL_ "GenSigTimeoutMsg" BU_SG_REL_ FSCM_ITBC_HS SG_ 493 EngRunng 493;
BA_REL_ "GenSigTimeoutTime" BU_SG_REL_ FSCM_ITBC_HS SG_ 493 EngRunng 250;
BA_REL_ "GenSigSuprvResp" BU_SG_REL_ FSCM_HS SG_ 493 EngRunng 1;
BA_REL_ "GenSigTimeoutMsg" BU_SG_REL_ FSCM_HS SG_ 493 EngRunng 493;
BA_REL_ "GenSigTimeoutTime" BU_SG_REL_ FSCM_HS SG_ 493 EngRunng 250;
BA_REL_ "GenSigSuprvResp" BU_SG_REL_ AMP_HS SG_ 493 EngRunng 1;
BA_REL_ "GenSigTimeoutMsg" BU_SG_REL_ AMP_HS SG_ 493 EngRunng 493;
BA_REL_ "GenSigTimeoutTime" BU_SG_REL_ AMP_HS SG_ 493 EngRunng 250;
BA_REL_ "GenSigSuprvResp" BU_SG_REL_ ICCM_OBD_HS SG_ 493 CmmndAirFuelRatio 1;
BA_REL_ "GenSigTimeoutMsg" BU_SG_REL_ ICCM_OBD_HS SG_ 493 CmmndAirFuelRatio 493;
BA_REL_ "GenSigTimeoutTime" BU_SG_REL_ ICCM_OBD_HS SG_ 493 CmmndAirFuelRatio 30;
BA_REL_ "GenSigSuprvResp" BU_SG_REL_ ICCM_HS SG_ 493 CmmndAirFuelRatio 1;
BA_REL_ "GenSigTimeoutMsg" BU_SG_REL_ ICCM_HS SG_ 493 CmmndAirFuelRatio 493;
BA_REL_ "GenSigTimeoutTime" BU_SG_REL_ ICCM_HS SG_ 493 CmmndAirFuelRatio 30;
BA_REL_ "GenSigSuprvResp" BU_SG_REL_ FSCM_ITBC_HS SG_ 493 CmmndAirFuelRatio 1;
BA_REL_ "GenSigTimeoutMsg" BU_SG_REL_ FSCM_ITBC_HS SG_ 493 CmmndAirFuelRatio 493;
BA_REL_ "GenSigTimeoutTime" BU_SG_REL_ FSCM_ITBC_HS SG_ 493 CmmndAirFuelRatio 30;
BA_REL_ "GenSigSuprvResp" BU_SG_REL_ FSCM_HS SG_ 493 CmmndAirFuelRatio 1;
BA_REL_ "GenSigTimeoutMsg" BU_SG_REL_ FSCM_HS SG_ 493 CmmndAirFuelRatio 493;
BA_REL_ "GenSigTimeoutTime" BU_SG_REL_ FSCM_HS SG_ 493 CmmndAirFuelRatio 30;
BA_REL_ "GenSigSuprvResp" BU_SG_REL_ ICCM_OBD_HS SG_ 493 AdvFuelFlowEst 1;
BA_REL_ "GenSigTimeoutMsg" BU_SG_REL_ ICCM_OBD_HS SG_ 493 AdvFuelFlowEst 493;
BA_REL_ "GenSigTimeoutTime" BU_SG_REL_ ICCM_OBD_HS SG_ 493 AdvFuelFlowEst 30;
BA_REL_ "GenSigSuprvResp" BU_SG_REL_ ICCM_HS SG_ 493 AdvFuelFlowEst 1;
BA_REL_ "GenSigTimeoutMsg" BU_SG_REL_ ICCM_HS SG_ 493 AdvFuelFlowEst 493;
BA_REL_ "GenSigTimeoutTime" BU_SG_REL_ ICCM_HS SG_ 493 AdvFuelFlowEst 30;
BA_REL_ "GenSigSuprvResp" BU_SG_REL_ FSCM_ITBC_HS SG_ 493 AdvFuelFlowEst 1;
BA_REL_ "GenSigTimeoutMsg" BU_SG_REL_ FSCM_ITBC_HS SG_ 493 AdvFuelFlowEst 493;
BA_REL_ "GenSigTimeoutTime" BU_SG_REL_ FSCM_ITBC_HS SG_ 493 AdvFuelFlowEst 30;
BA_REL_ "GenSigSuprvResp" BU_SG_REL_ FSCM_HS SG_ 493 AdvFuelFlowEst 1;
BA_REL_ "GenSigTimeoutMsg" BU_SG_REL_ FSCM_HS SG_ 493 AdvFuelFlowEst 493;
BA_REL_ "GenSigTimeoutTime" BU_SG_REL_ FSCM_HS SG_ 493 AdvFuelFlowEst 30;
BA_REL_ "GenSigSuprvResp" BU_SG_REL_ VICM_HS SG_ 493 InstFuelFlowEst 1;
BA_REL_ "GenSigTimeoutMsg" BU_SG_REL_ VICM_HS SG_ 493 InstFuelFlowEst 493;
BA_REL_ "GenSigTimeoutTime" BU_SG_REL_ VICM_HS SG_ 493 InstFuelFlowEst 31;
BA_REL_ "GenSigSuprvResp" BU_SG_REL_ ICCM_OBD_HS SG_ 493 InstFuelFlowEst 1;
BA_REL_ "GenSigTimeoutMsg" BU_SG_REL_ ICCM_OBD_HS SG_ 493 InstFuelFlowEst 493;
BA_REL_ "GenSigTimeoutTime" BU_SG_REL_ ICCM_OBD_HS SG_ 493 InstFuelFlowEst 30;
BA_REL_ "GenSigSuprvResp" BU_SG_REL_ ICCM_HS SG_ 493 InstFuelFlowEst 1;
BA_REL_ "GenSigTimeoutMsg" BU_SG_REL_ ICCM_HS SG_ 493 InstFuelFlowEst 493;
BA_REL_ "GenSigTimeoutTime" BU_SG_REL_ ICCM_HS SG_ 493 InstFuelFlowEst 30;
BA_REL_ "GenSigSuprvResp" BU_SG_REL_ FSCM_ITBC_HS SG_ 493 InstFuelFlowEst 1;
BA_REL_ "GenSigTimeoutMsg" BU_SG_REL_ FSCM_ITBC_HS SG_ 493 InstFuelFlowEst 493;
BA_REL_ "GenSigTimeoutTime" BU_SG_REL_ FSCM_ITBC_HS SG_ 493 InstFuelFlowEst 30;
BA_REL_ "GenSigSuprvResp" BU_SG_REL_ FSCM_HS SG_ 493 InstFuelFlowEst 1;
BA_REL_ "GenSigTimeoutMsg" BU_SG_REL_ FSCM_HS SG_ 493 InstFuelFlowEst 493;
BA_REL_ "GenSigTimeoutTime" BU_SG_REL_ FSCM_HS SG_ 493 InstFuelFlowEst 30;
BA_REL_ "GenSigSuprvResp" BU_SG_REL_ ICCM_OBD_HS SG_ 493 FuelDelPressRqd 1;
BA_REL_ "GenSigTimeoutMsg" BU_SG_REL_ ICCM_OBD_HS SG_ 493 FuelDelPressRqd 493;
BA_REL_ "GenSigTimeoutTime" BU_SG_REL_ ICCM_OBD_HS SG_ 493 FuelDelPressRqd 30;
BA_REL_ "GenSigSuprvResp" BU_SG_REL_ ICCM_HS SG_ 493 FuelDelPressRqd 1;
BA_REL_ "GenSigTimeoutMsg" BU_SG_REL_ ICCM_HS SG_ 493 FuelDelPressRqd 493;
BA_REL_ "GenSigTimeoutTime" BU_SG_REL_ ICCM_HS SG_ 493 FuelDelPressRqd 30;
BA_REL_ "GenSigSuprvResp" BU_SG_REL_ FSCM_ITBC_HS SG_ 493 FuelDelPressRqd 1;
BA_REL_ "GenSigTimeoutMsg" BU_SG_REL_ FSCM_ITBC_HS SG_ 493 FuelDelPressRqd 493;
BA_REL_ "GenSigTimeoutTime" BU_SG_REL_ FSCM_ITBC_HS SG_ 493 FuelDelPressRqd 30;
BA_REL_ "GenSigSuprvResp" BU_SG_REL_ FSCM_HS SG_ 493 FuelDelPressRqd 1;
BA_REL_ "GenSigTimeoutMsg" BU_SG_REL_ FSCM_HS SG_ 493 FuelDelPressRqd 493;
BA_REL_ "GenSigTimeoutTime" BU_SG_REL_ FSCM_HS SG_ 493 FuelDelPressRqd 30;
BA_REL_ "GenSigSuprvResp" BU_SG_REL_ ICCM_OBD_HS SG_ 493 FuelCntlSysFltPrsnt 1;
BA_REL_ "GenSigTimeoutMsg" BU_SG_REL_ ICCM_OBD_HS SG_ 493 FuelCntlSysFltPrsnt 493;
BA_REL_ "GenSigTimeoutTime" BU_SG_REL_ ICCM_OBD_HS SG_ 493 FuelCntlSysFltPrsnt 30;
BA_REL_ "GenSigSuprvResp" BU_SG_REL_ ICCM_HS SG_ 493 FuelCntlSysFltPrsnt 1;
BA_REL_ "GenSigTimeoutMsg" BU_SG_REL_ ICCM_HS SG_ 493 FuelCntlSysFltPrsnt 493;
BA_REL_ "GenSigTimeoutTime" BU_SG_REL_ ICCM_HS SG_ 493 FuelCntlSysFltPrsnt 30;
BA_REL_ "GenSigSuprvResp" BU_SG_REL_ FSCM_ITBC_HS SG_ 493 FuelCntlSysFltPrsnt 1;
BA_REL_ "GenSigTimeoutMsg" BU_SG_REL_ FSCM_ITBC_HS SG_ 493 FuelCntlSysFltPrsnt 493;
BA_REL_ "GenSigTimeoutTime" BU_SG_REL_ FSCM_ITBC_HS SG_ 493 FuelCntlSysFltPrsnt 30;
BA_REL_ "GenSigSuprvResp" BU_SG_REL_ FSCM_HS SG_ 493 FuelCntlSysFltPrsnt 1;
BA_REL_ "GenSigTimeoutMsg" BU_SG_REL_ FSCM_HS SG_ 493 FuelCntlSysFltPrsnt 493;
BA_REL_ "GenSigTimeoutTime" BU_SG_REL_ FSCM_HS SG_ 493 FuelCntlSysFltPrsnt 30;
BA_REL_ "GenSigSuprvResp" BU_SG_REL_ TCM_HS SG_ 401 TrnsEngSpdReqFld 1;
BA_REL_ "GenSigTimeoutMsg" BU_SG_REL_ TCM_HS SG_ 401 TrnsEngSpdReqFld 401;
BA_REL_ "GenSigTimeoutTime" BU_SG_REL_ TCM_HS SG_ 401 TrnsEngSpdReqFld 31;
BA_REL_ "GenSigSuprvResp" BU_SG_REL_ TCCM_HS SG_ 401 ThrtCommndPos 1;
BA_REL_ "GenSigTimeoutMsg" BU_SG_REL_ TCCM_HS SG_ 401 ThrtCommndPos 401;
BA_REL_ "GenSigTimeoutTime" BU_SG_REL_ TCCM_HS SG_ 401 ThrtCommndPos 250;
BA_REL_ "GenSigSuprvResp" BU_SG_REL_ TCM_HS SG_ 401 EngTrqTnsRqFld 1;
BA_REL_ "GenSigTimeoutMsg" BU_SG_REL_ TCM_HS SG_ 401 EngTrqTnsRqFld 401;
BA_REL_ "GenSigTimeoutTime" BU_SG_REL_ TCM_HS SG_ 401 EngTrqTnsRqFld 31;
BA_REL_ "GenSigSuprvResp" BU_SG_REL_ FSCM_HS SG_ 401 AccPos 1;
BA_REL_ "GenSigTimeoutMsg" BU_SG_REL_ FSCM_HS SG_ 401 AccPos 401;
BA_REL_ "GenSigTimeoutTime" BU_SG_REL_ FSCM_HS SG_ 401 AccPos 250;
BA_REL_ "GenSigSuprvResp" BU_SG_REL_ FICM_HS SG_ 401 AccPos 1;
BA_REL_ "GenSigTimeoutMsg" BU_SG_REL_ FICM_HS SG_ 401 AccPos 401;
BA_REL_ "GenSigTimeoutTime" BU_SG_REL_ FICM_HS SG_ 401 AccPos 250;
BA_REL_ "GenSigSuprvResp" BU_SG_REL_ AMP_HS SG_ 707 EngManfldAbsPrs 1;
BA_REL_ "GenSigTimeoutMsg" BU_SG_REL_ AMP_HS SG_ 707 EngManfldAbsPrs 707;
BA_REL_ "GenSigTimeoutTime" BU_SG_REL_ AMP_HS SG_ 707 EngManfldAbsPrs 250;
BA_REL_ "GenSigSuprvResp" BU_SG_REL_ ACC_HS SG_ 707 EngTrqMinExtRng 1;
BA_REL_ "GenSigTimeoutMsg" BU_SG_REL_ ACC_HS SG_ 707 EngTrqMinExtRng 707;
BA_REL_ "GenSigTimeoutTime" BU_SG_REL_ ACC_HS SG_ 707 EngTrqMinExtRng 250;
BA_REL_ "GenSigSuprvResp" BU_SG_REL_ TCCM_HS SG_ 707 EngTrqMaxExtRng 1;
BA_REL_ "GenSigTimeoutMsg" BU_SG_REL_ TCCM_HS SG_ 707 EngTrqMaxExtRng 707;
BA_REL_ "GenSigTimeoutTime" BU_SG_REL_ TCCM_HS SG_ 707 EngTrqMaxExtRng 250;
BA_REL_ "GenSigSuprvResp" BU_SG_REL_ ACC_HS SG_ 707 EngTrqMaxExtRng 1;
BA_REL_ "GenSigTimeoutMsg" BU_SG_REL_ ACC_HS SG_ 707 EngTrqMaxExtRng 707;
BA_REL_ "GenSigTimeoutTime" BU_SG_REL_ ACC_HS SG_ 707 EngTrqMaxExtRng 250;
BA_REL_ "GenSigVBitResp" BU_SG_REL_ RDCM_HS SG_ 707 EngTrqMaxExtRng 1;
BA_REL_ "GenSigSuprvResp" BU_SG_REL_ RDCM_HS SG_ 707 EngTrqMaxExtRng 1;
BA_REL_ "GenSigTimeoutMsg" BU_SG_REL_ RDCM_HS SG_ 707 EngTrqMaxExtRng 707;
BA_REL_ "GenSigTimeoutTime" BU_SG_REL_ RDCM_HS SG_ 707 EngTrqMaxExtRng 250;
BA_REL_ "GenSigSuprvResp" BU_SG_REL_ BCM_HS SG_ 1265 PTSysHzrdLghtReq 1;
BA_REL_ "GenSigTimeoutMsg" BU_SG_REL_ BCM_HS SG_ 1265 PTSysHzrdLghtReq 1265;
BA_REL_ "GenSigTimeoutTime" BU_SG_REL_ BCM_HS SG_ 1265 PTSysHzrdLghtReq 2500;
BA_REL_ "GenSigSuprvResp" BU_SG_REL_ VES_HS SG_ 1265 WhlDistPrRevNDrvn 1;
BA_REL_ "GenSigTimeoutMsg" BU_SG_REL_ VES_HS SG_ 1265 WhlDistPrRevNDrvn 1265;
BA_REL_ "GenSigTimeoutTime" BU_SG_REL_ VES_HS SG_ 1265 WhlDistPrRevNDrvn 2500;
BA_REL_ "GenSigSuprvResp" BU_SG_REL_ EPS_HS SG_ 1265 WhlDistPrRevNDrvn 1;
BA_REL_ "GenSigTimeoutMsg" BU_SG_REL_ EPS_HS SG_ 1265 WhlDistPrRevNDrvn 1265;
BA_REL_ "GenSigTimeoutTime" BU_SG_REL_ EPS_HS SG_ 1265 WhlDistPrRevNDrvn 2500;
BA_REL_ "GenSigSuprvResp" BU_SG_REL_ TCCM_HS SG_ 1265 WhlDistPrRevNDrvn 1;
BA_REL_ "GenSigTimeoutMsg" BU_SG_REL_ TCCM_HS SG_ 1265 WhlDistPrRevNDrvn 1265;
BA_REL_ "GenSigTimeoutTime" BU_SG_REL_ TCCM_HS SG_ 1265 WhlDistPrRevNDrvn 2500;
BA_REL_ "GenSigSuprvResp" BU_SG_REL_ EOCM_F_HS SG_ 1265 WhlDistPrRevNDrvn 1;
BA_REL_ "GenSigTimeoutMsg" BU_SG_REL_ EOCM_F_HS SG_ 1265 WhlDistPrRevNDrvn 1265;
BA_REL_ "GenSigTimeoutTime" BU_SG_REL_ EOCM_F_HS SG_ 1265 WhlDistPrRevNDrvn 2500;
BA_REL_ "GenSigRxStartValue" BU_SG_REL_ RDCM_HS SG_ 1265 WhlDistPrRevNDrvn "2000 mm ($190)";
BA_REL_ "GenSigSuprvResp" BU_SG_REL_ VES_HS SG_ 1265 WhlDistPrRevDrvn 1;
BA_REL_ "GenSigTimeoutMsg" BU_SG_REL_ VES_HS SG_ 1265 WhlDistPrRevDrvn 1265;
BA_REL_ "GenSigTimeoutTime" BU_SG_REL_ VES_HS SG_ 1265 WhlDistPrRevDrvn 2500;
BA_REL_ "GenSigSuprvResp" BU_SG_REL_ EPS_HS SG_ 1265 WhlDistPrRevDrvn 1;
BA_REL_ "GenSigTimeoutMsg" BU_SG_REL_ EPS_HS SG_ 1265 WhlDistPrRevDrvn 1265;
BA_REL_ "GenSigTimeoutTime" BU_SG_REL_ EPS_HS SG_ 1265 WhlDistPrRevDrvn 2500;
BA_REL_ "GenSigSuprvResp" BU_SG_REL_ EOCM_F_HS SG_ 1265 WhlDistPrRevDrvn 1;
BA_REL_ "GenSigTimeoutMsg" BU_SG_REL_ EOCM_F_HS SG_ 1265 WhlDistPrRevDrvn 1265;
BA_REL_ "GenSigTimeoutTime" BU_SG_REL_ EOCM_F_HS SG_ 1265 WhlDistPrRevDrvn 2500;
BA_REL_ "GenSigSuprvResp" BU_SG_REL_ ACC_HS SG_ 1265 WhlDistPrRevDrvn 1;
BA_REL_ "GenSigTimeoutMsg" BU_SG_REL_ ACC_HS SG_ 1265 WhlDistPrRevDrvn 1265;
BA_REL_ "GenSigTimeoutTime" BU_SG_REL_ ACC_HS SG_ 1265 WhlDistPrRevDrvn 5000;
BA_REL_ "GenSigSuprvResp" BU_SG_REL_ TCCM_HS SG_ 1265 WhlDistPrRevDrvn 1;
BA_REL_ "GenSigTimeoutMsg" BU_SG_REL_ TCCM_HS SG_ 1265 WhlDistPrRevDrvn 1265;
BA_REL_ "GenSigTimeoutTime" BU_SG_REL_ TCCM_HS SG_ 1265 WhlDistPrRevDrvn 2500;
BA_REL_ "GenSigSuprvResp" BU_SG_REL_ BCM_HS SG_ 1265 WhlDistPrRevDrvn 1;
BA_REL_ "GenSigTimeoutMsg" BU_SG_REL_ BCM_HS SG_ 1265 WhlDistPrRevDrvn 1265;
BA_REL_ "GenSigTimeoutTime" BU_SG_REL_ BCM_HS SG_ 1265 WhlDistPrRevDrvn 2500;
BA_REL_ "GenSigRxStartValue" BU_SG_REL_ RDCM_HS SG_ 1265 WhlDistPrRevDrvn "2000 mm ($190)";
BA_REL_ "GenSigSuprvResp" BU_SG_REL_ RDCM_HS SG_ 1265 WhlDistPrRevDrvn 1;
BA_REL_ "GenSigTimeoutMsg" BU_SG_REL_ RDCM_HS SG_ 1265 WhlDistPrRevDrvn 1265;
BA_REL_ "GenSigTimeoutTime" BU_SG_REL_ RDCM_HS SG_ 1265 WhlDistPrRevDrvn 2500;
BA_REL_ "GenSigSuprvResp" BU_SG_REL_ TCCM_HS SG_ 1265 DrvlnFnlAxleRatio 1;
BA_REL_ "GenSigTimeoutMsg" BU_SG_REL_ TCCM_HS SG_ 1265 DrvlnFnlAxleRatio 1265;
BA_REL_ "GenSigTimeoutTime" BU_SG_REL_ TCCM_HS SG_ 1265 DrvlnFnlAxleRatio 2500;
BA_REL_ "GenSigSuprvResp" BU_SG_REL_ BCM_HS SG_ 1265 DrvlnFnlAxleRatio 1;
BA_REL_ "GenSigTimeoutMsg" BU_SG_REL_ BCM_HS SG_ 1265 DrvlnFnlAxleRatio 1265;
BA_REL_ "GenSigTimeoutTime" BU_SG_REL_ BCM_HS SG_ 1265 DrvlnFnlAxleRatio 2500;
BA_REL_ "GenSigSuprvResp" BU_SG_REL_ TCM_HS SG_ 417 TracCntlSysPwrtrnInhbt 1;
BA_REL_ "GenSigTimeoutMsg" BU_SG_REL_ TCM_HS SG_ 417 TracCntlSysPwrtrnInhbt 417;
BA_REL_ "GenSigTimeoutTime" BU_SG_REL_ TCM_HS SG_ 417 TracCntlSysPwrtrnInhbt 62;
BA_REL_ "GenSigSuprvResp" BU_SG_REL_ TCM_HS SG_ 417 EngMtlProtAtv 1;
BA_REL_ "GenSigTimeoutMsg" BU_SG_REL_ TCM_HS SG_ 417 EngMtlProtAtv 417;
BA_REL_ "GenSigTimeoutTime" BU_SG_REL_ TCM_HS SG_ 417 EngMtlProtAtv 62;
BA_REL_ "GenSigSuprvResp" BU_SG_REL_ TCM_HS SG_ 417 EngDgTrqCnvClUnlkRqd 1;
BA_REL_ "GenSigTimeoutMsg" BU_SG_REL_ TCM_HS SG_ 417 EngDgTrqCnvClUnlkRqd 417;
BA_REL_ "GenSigTimeoutTime" BU_SG_REL_ TCM_HS SG_ 417 EngDgTrqCnvClUnlkRqd 62;
BA_REL_ "GenSigSuprvResp" BU_SG_REL_ TCM_HS SG_ 417 EngCyldrDeactReqd 1;
BA_REL_ "GenSigTimeoutMsg" BU_SG_REL_ TCM_HS SG_ 417 EngCyldrDeactReqd 417;
BA_REL_ "GenSigTimeoutTime" BU_SG_REL_ TCM_HS SG_ 417 EngCyldrDeactReqd 62;
BA_REL_ "GenSigSuprvResp" BU_SG_REL_ TCM_HS SG_ 417 ETGRReqdGear 1;
BA_REL_ "GenSigTimeoutMsg" BU_SG_REL_ TCM_HS SG_ 417 ETGRReqdGear 417;
BA_REL_ "GenSigTimeoutTime" BU_SG_REL_ TCM_HS SG_ 417 ETGRReqdGear 62;
BA_REL_ "GenSigSuprvResp" BU_SG_REL_ TCM_HS SG_ 417 ETGRReqType 1;
BA_REL_ "GenSigTimeoutMsg" BU_SG_REL_ TCM_HS SG_ 417 ETGRReqType 417;
BA_REL_ "GenSigTimeoutTime" BU_SG_REL_ TCM_HS SG_ 417 ETGRReqType 62;
BA_REL_ "GenSigSuprvResp" BU_SG_REL_ PTO_HS SG_ 1233 PTExPrtclFltrWrn2IO 1;
BA_REL_ "GenSigTimeoutMsg" BU_SG_REL_ PTO_HS SG_ 1233 PTExPrtclFltrWrn2IO 1233;
BA_REL_ "GenSigTimeoutTime" BU_SG_REL_ PTO_HS SG_ 1233 PTExPrtclFltrWrn2IO 1250;
BA_REL_ "GenSigSuprvResp" BU_SG_REL_ PTO_HS SG_ 1233 PTExPrtclFltrWrnIO 1;
BA_REL_ "GenSigTimeoutMsg" BU_SG_REL_ PTO_HS SG_ 1233 PTExPrtclFltrWrnIO 1233;
BA_REL_ "GenSigTimeoutTime" BU_SG_REL_ PTO_HS SG_ 1233 PTExPrtclFltrWrnIO 1250;
BA_REL_ "GenSigSuprvResp" BU_SG_REL_ PTO_HS SG_ 1233 FlLvlPct 1;
BA_REL_ "GenSigTimeoutMsg" BU_SG_REL_ PTO_HS SG_ 1233 FlLvlPct 1233;
BA_REL_ "GenSigTimeoutTime" BU_SG_REL_ PTO_HS SG_ 1233 FlLvlPct 1250;
BA_REL_ "GenSigSuprvResp" BU_SG_REL_ AHL_AFL_HS SG_ 1233 FlLvlPct 1;
BA_REL_ "GenSigTimeoutMsg" BU_SG_REL_ AHL_AFL_HS SG_ 1233 FlLvlPct 1233;
BA_REL_ "GenSigTimeoutTime" BU_SG_REL_ AHL_AFL_HS SG_ 1233 FlLvlPct 1250;
BA_REL_ "GenSigVBitResp" BU_SG_REL_ BCM_HS SG_ 1233 FlLvlPct 1;
BA_REL_ "GenSigSuprvResp" BU_SG_REL_ BCM_HS SG_ 1233 FlLvlPct 1;
BA_REL_ "GenSigTimeoutMsg" BU_SG_REL_ BCM_HS SG_ 1233 FlLvlPct 1233;
BA_REL_ "GenSigTimeoutTime" BU_SG_REL_ BCM_HS SG_ 1233 FlLvlPct 1250;
BA_REL_ "GenSigVBitResp" BU_SG_REL_ BCM_HS SG_ 1233 FlLvlPct 1;
BA_REL_ "GenSigSuprvResp" BU_SG_REL_ BCM_HS SG_ 1233 FlLvlPct 1;
BA_REL_ "GenSigTimeoutMsg" BU_SG_REL_ BCM_HS SG_ 1233 FlLvlPct 1233;
BA_REL_ "GenSigTimeoutTime" BU_SG_REL_ BCM_HS SG_ 1233 FlLvlPct 1250;
BA_REL_ "GenSigSuprvResp" BU_SG_REL_ EPS_HS SG_ 1233 EngOilTmp 1;
BA_REL_ "GenSigTimeoutMsg" BU_SG_REL_ EPS_HS SG_ 1233 EngOilTmp 1233;
BA_REL_ "GenSigTimeoutTime" BU_SG_REL_ EPS_HS SG_ 1233 EngOilTmp 1250;
BA_REL_ "GenSigVBitResp" BU_SG_REL_ BCM_HS SG_ 1233 EngOilTmp 1;
BA_REL_ "GenSigSuprvResp" BU_SG_REL_ BCM_HS SG_ 1233 EngOilTmp 1;
BA_REL_ "GenSigTimeoutMsg" BU_SG_REL_ BCM_HS SG_ 1233 EngOilTmp 1233;
BA_REL_ "GenSigTimeoutTime" BU_SG_REL_ BCM_HS SG_ 1233 EngOilTmp 1250;
BA_REL_ "GenSigSuprvResp" BU_SG_REL_ PTO_HS SG_ 1233 EngOilPrsLwIO 1;
BA_REL_ "GenSigTimeoutMsg" BU_SG_REL_ PTO_HS SG_ 1233 EngOilPrsLwIO 1233;
BA_REL_ "GenSigTimeoutTime" BU_SG_REL_ PTO_HS SG_ 1233 EngOilPrsLwIO 1250;
BA_REL_ "GenSigSuprvResp" BU_SG_REL_ PTO_HS SG_ 1233 EngOilPrs 1;
BA_REL_ "GenSigTimeoutMsg" BU_SG_REL_ PTO_HS SG_ 1233 EngOilPrs 1233;
BA_REL_ "GenSigTimeoutTime" BU_SG_REL_ PTO_HS SG_ 1233 EngOilPrs 1250;
BA_REL_ "GenSigVBitResp" BU_SG_REL_ BCM_HS SG_ 1233 EngOilPrs 1;
BA_REL_ "GenSigSuprvResp" BU_SG_REL_ BCM_HS SG_ 1233 EngOilPrs 1;
BA_REL_ "GenSigTimeoutMsg" BU_SG_REL_ BCM_HS SG_ 1233 EngOilPrs 1233;
BA_REL_ "GenSigTimeoutTime" BU_SG_REL_ BCM_HS SG_ 1233 EngOilPrs 1250;
BA_REL_ "GenSigSuprvResp" BU_SG_REL_ PTO_HS SG_ 1233 EngOilLvlLwIO 1;
BA_REL_ "GenSigTimeoutMsg" BU_SG_REL_ PTO_HS SG_ 1233 EngOilLvlLwIO 1233;
BA_REL_ "GenSigTimeoutTime" BU_SG_REL_ PTO_HS SG_ 1233 EngOilLvlLwIO 1250;
BA_REL_ "GenSigSuprvResp" BU_SG_REL_ PTO_HS SG_ 1233 EngHt_StpEngIO 1;
BA_REL_ "GenSigTimeoutMsg" BU_SG_REL_ PTO_HS SG_ 1233 EngHt_StpEngIO 1233;
BA_REL_ "GenSigTimeoutTime" BU_SG_REL_ PTO_HS SG_ 1233 EngHt_StpEngIO 1250;
BA_REL_ "GenSigSuprvResp" BU_SG_REL_ VICM2_HS SG_ 1217 LegPstDTCClrDrvCyCm 1;
BA_REL_ "GenSigTimeoutMsg" BU_SG_REL_ VICM2_HS SG_ 1217 LegPstDTCClrDrvCyCm 1217;
BA_REL_ "GenSigTimeoutTime" BU_SG_REL_ VICM2_HS SG_ 1217 LegPstDTCClrDrvCyCm 1250;
BA_REL_ "GenSigSuprvResp" BU_SG_REL_ VICM2_HS SG_ 1217 LegDiagColdStCndMet 1;
BA_REL_ "GenSigTimeoutMsg" BU_SG_REL_ VICM2_HS SG_ 1217 LegDiagColdStCndMet 1217;
BA_REL_ "GenSigTimeoutTime" BU_SG_REL_ VICM2_HS SG_ 1217 LegDiagColdStCndMet 1250;
BA_REL_ "GenSigSuprvResp" BU_SG_REL_ VICM2_HS SG_ 1217 LegDiagColdStCndFltPr 1;
BA_REL_ "GenSigTimeoutMsg" BU_SG_REL_ VICM2_HS SG_ 1217 LegDiagColdStCndFltPr 1217;
BA_REL_ "GenSigTimeoutTime" BU_SG_REL_ VICM2_HS SG_ 1217 LegDiagColdStCndFltPr 1250;
BA_REL_ "GenSigSuprvResp" BU_SG_REL_ VICM2_HS SG_ 1217 LegDiagStndCndFltPr 1;
BA_REL_ "GenSigTimeoutMsg" BU_SG_REL_ VICM2_HS SG_ 1217 LegDiagStndCndFltPr 1217;
BA_REL_ "GenSigTimeoutTime" BU_SG_REL_ VICM2_HS SG_ 1217 LegDiagStndCndFltPr 1250;
BA_REL_ "GenSigSuprvResp" BU_SG_REL_ TCM_HS SG_ 1217 OAT_PT_Est 1;
BA_REL_ "GenSigTimeoutMsg" BU_SG_REL_ TCM_HS SG_ 1217 OAT_PT_Est 1217;
BA_REL_ "GenSigTimeoutTime" BU_SG_REL_ TCM_HS SG_ 1217 OAT_PT_Est 625;
BA_REL_ "GenSigVBitResp" BU_SG_REL_ RDCM_HS SG_ 1217 OAT_PT_Est 1;
BA_REL_ "GenSigRxStartValue" BU_SG_REL_ RDCM_HS SG_ 1217 OAT_PT_Est "0 degrees ($80)";
BA_REL_ "GenSigSuprvResp" BU_SG_REL_ RDCM_HS SG_ 1217 OAT_PT_Est 1;
BA_REL_ "GenSigTimeoutMsg" BU_SG_REL_ RDCM_HS SG_ 1217 OAT_PT_Est 1217;
BA_REL_ "GenSigTimeoutTime" BU_SG_REL_ RDCM_HS SG_ 1217 OAT_PT_Est 1250;
BA_REL_ "GenSigVBitResp" BU_SG_REL_ BCM_HS SG_ 1217 OAT_PT_Est 1;
BA_REL_ "GenSigSuprvResp" BU_SG_REL_ BCM_HS SG_ 1217 OAT_PT_Est 1;
BA_REL_ "GenSigTimeoutMsg" BU_SG_REL_ BCM_HS SG_ 1217 OAT_PT_Est 1217;
BA_REL_ "GenSigTimeoutTime" BU_SG_REL_ BCM_HS SG_ 1217 OAT_PT_Est 1250;
BA_REL_ "GenSigSuprvResp" BU_SG_REL_ ICCM_OBD_HS SG_ 1217 EngIntAirTmp 1;
BA_REL_ "GenSigTimeoutMsg" BU_SG_REL_ ICCM_OBD_HS SG_ 1217 EngIntAirTmp 1217;
BA_REL_ "GenSigTimeoutTime" BU_SG_REL_ ICCM_OBD_HS SG_ 1217 EngIntAirTmp 1250;
BA_REL_ "GenSigSuprvResp" BU_SG_REL_ ICCM_HS SG_ 1217 EngIntAirTmp 1;
BA_REL_ "GenSigTimeoutMsg" BU_SG_REL_ ICCM_HS SG_ 1217 EngIntAirTmp 1217;
BA_REL_ "GenSigTimeoutTime" BU_SG_REL_ ICCM_HS SG_ 1217 EngIntAirTmp 1250;
BA_REL_ "GenSigSuprvResp" BU_SG_REL_ RDCM_HS SG_ 1217 EngIntAirTmp 1;
BA_REL_ "GenSigTimeoutMsg" BU_SG_REL_ RDCM_HS SG_ 1217 EngIntAirTmp 1217;
BA_REL_ "GenSigTimeoutTime" BU_SG_REL_ RDCM_HS SG_ 1217 EngIntAirTmp 1250;
BA_REL_ "GenSigSuprvResp" BU_SG_REL_ VICM2_HS SG_ 1217 EngIntAirTmp 1;
BA_REL_ "GenSigTimeoutMsg" BU_SG_REL_ VICM2_HS SG_ 1217 EngIntAirTmp 1217;
BA_REL_ "GenSigTimeoutTime" BU_SG_REL_ VICM2_HS SG_ 1217 EngIntAirTmp 1250;
BA_REL_ "GenSigSuprvResp" BU_SG_REL_ VICM_HS SG_ 1217 EngIntAirTmp 1;
BA_REL_ "GenSigTimeoutMsg" BU_SG_REL_ VICM_HS SG_ 1217 EngIntAirTmp 1217;
BA_REL_ "GenSigTimeoutTime" BU_SG_REL_ VICM_HS SG_ 1217 EngIntAirTmp 625;
BA_REL_ "GenSigSuprvResp" BU_SG_REL_ TCCM_HS SG_ 1217 EngIntAirTmp 1;
BA_REL_ "GenSigTimeoutMsg" BU_SG_REL_ TCCM_HS SG_ 1217 EngIntAirTmp 1217;
BA_REL_ "GenSigTimeoutTime" BU_SG_REL_ TCCM_HS SG_ 1217 EngIntAirTmp 1250;
BA_REL_ "GenSigVBitResp" BU_SG_REL_ BCM_HS SG_ 1217 EngIntAirTmp 1;
BA_REL_ "GenSigSuprvResp" BU_SG_REL_ BCM_HS SG_ 1217 EngIntAirTmp 1;
BA_REL_ "GenSigTimeoutMsg" BU_SG_REL_ BCM_HS SG_ 1217 EngIntAirTmp 1217;
BA_REL_ "GenSigTimeoutTime" BU_SG_REL_ BCM_HS SG_ 1217 EngIntAirTmp 1250;
BA_REL_ "GenSigSuprvResp" BU_SG_REL_ EPS_HS SG_ 1217 EngCltTmp 1;
BA_REL_ "GenSigTimeoutMsg" BU_SG_REL_ EPS_HS SG_ 1217 EngCltTmp 1217;
BA_REL_ "GenSigTimeoutTime" BU_SG_REL_ EPS_HS SG_ 1217 EngCltTmp 1250;
BA_REL_ "GenSigRxStartValue" BU_SG_REL_ VCM_HS SG_ 1217 EngCltTmp "80degC";
BA_REL_ "GenSigSuprvResp" BU_SG_REL_ VCM_HS SG_ 1217 EngCltTmp 1;
BA_REL_ "GenSigTimeoutMsg" BU_SG_REL_ VCM_HS SG_ 1217 EngCltTmp 1217;
BA_REL_ "GenSigTimeoutTime" BU_SG_REL_ VCM_HS SG_ 1217 EngCltTmp 1250;
BA_REL_ "GenSigSuprvResp" BU_SG_REL_ ICCM_OBD_HS SG_ 1217 EngCltTmp 1;
BA_REL_ "GenSigTimeoutMsg" BU_SG_REL_ ICCM_OBD_HS SG_ 1217 EngCltTmp 1217;
BA_REL_ "GenSigTimeoutTime" BU_SG_REL_ ICCM_OBD_HS SG_ 1217 EngCltTmp 1250;
BA_REL_ "GenSigSuprvResp" BU_SG_REL_ ICCM_HS SG_ 1217 EngCltTmp 1;
BA_REL_ "GenSigTimeoutMsg" BU_SG_REL_ ICCM_HS SG_ 1217 EngCltTmp 1217;
BA_REL_ "GenSigTimeoutTime" BU_SG_REL_ ICCM_HS SG_ 1217 EngCltTmp 1250;
BA_REL_ "GenSigSuprvResp" BU_SG_REL_ FSCM_HS SG_ 1217 EngCltTmp 1;
BA_REL_ "GenSigTimeoutMsg" BU_SG_REL_ FSCM_HS SG_ 1217 EngCltTmp 1217;
BA_REL_ "GenSigTimeoutTime" BU_SG_REL_ FSCM_HS SG_ 1217 EngCltTmp 1250;
BA_REL_ "GenSigSuprvResp" BU_SG_REL_ VICM_HS SG_ 1217 EngCltTmp 1;
BA_REL_ "GenSigTimeoutMsg" BU_SG_REL_ VICM_HS SG_ 1217 EngCltTmp 1217;
BA_REL_ "GenSigTimeoutTime" BU_SG_REL_ VICM_HS SG_ 1217 EngCltTmp 1250;
BA_REL_ "GenSigSuprvResp" BU_SG_REL_ VICM_HS SG_ 1217 EngCltTmp 1;
BA_REL_ "GenSigTimeoutMsg" BU_SG_REL_ VICM_HS SG_ 1217 EngCltTmp 1217;
BA_REL_ "GenSigTimeoutTime" BU_SG_REL_ VICM_HS SG_ 1217 EngCltTmp 1250;
BA_REL_ "GenSigSuprvResp" BU_SG_REL_ VICM2_HS SG_ 1217 EngCltTmp 1;
BA_REL_ "GenSigTimeoutMsg" BU_SG_REL_ VICM2_HS SG_ 1217 EngCltTmp 1217;
BA_REL_ "GenSigTimeoutTime" BU_SG_REL_ VICM2_HS SG_ 1217 EngCltTmp 1250;
BA_REL_ "GenSigSuprvResp" BU_SG_REL_ VICM2_HS SG_ 1217 EngCltTmp 1;
BA_REL_ "GenSigTimeoutMsg" BU_SG_REL_ VICM2_HS SG_ 1217 EngCltTmp 1217;
BA_REL_ "GenSigTimeoutTime" BU_SG_REL_ VICM2_HS SG_ 1217 EngCltTmp 1250;
BA_REL_ "GenSigSuprvResp" BU_SG_REL_ BCM_HS SG_ 1217 EngCltTmp 1;
BA_REL_ "GenSigTimeoutMsg" BU_SG_REL_ BCM_HS SG_ 1217 EngCltTmp 1217;
BA_REL_ "GenSigTimeoutTime" BU_SG_REL_ BCM_HS SG_ 1217 EngCltTmp 1250;
BA_REL_ "GenSigSuprvResp" BU_SG_REL_ BCM_HS SG_ 1217 EngCltTmp 1;
BA_REL_ "GenSigTimeoutMsg" BU_SG_REL_ BCM_HS SG_ 1217 EngCltTmp 1217;
BA_REL_ "GenSigTimeoutTime" BU_SG_REL_ BCM_HS SG_ 1217 EngCltTmp 1250;
BA_REL_ "GenSigVBitResp" BU_SG_REL_ BCM_HS SG_ 1217 EngCltTmp 1;
BA_REL_ "GenSigSuprvResp" BU_SG_REL_ BCM_HS SG_ 1217 EngCltTmp 1;
BA_REL_ "GenSigTimeoutMsg" BU_SG_REL_ BCM_HS SG_ 1217 EngCltTmp 1217;
BA_REL_ "GenSigTimeoutTime" BU_SG_REL_ BCM_HS SG_ 1217 EngCltTmp 1250;
BA_REL_ "GenSigSuprvResp" BU_SG_REL_ VICM_HS SG_ 1217 BarPrsAbs 1;
BA_REL_ "GenSigTimeoutMsg" BU_SG_REL_ VICM_HS SG_ 1217 BarPrsAbs 1217;
BA_REL_ "GenSigTimeoutTime" BU_SG_REL_ VICM_HS SG_ 1217 BarPrsAbs 625;
BA_REL_ "GenSigVBitResp" BU_SG_REL_ ICCM_OBD_HS SG_ 1217 BarPrsAbs 1;
BA_REL_ "GenSigVBitResp" BU_SG_REL_ ICCM_HS SG_ 1217 BarPrsAbs 1;
BA_REL_ "GenSigVBitResp" BU_SG_REL_ FSCM_ITBC_HS SG_ 1217 BarPrsAbs 1;
BA_REL_ "GenSigVBitResp" BU_SG_REL_ FSCM_HS SG_ 1217 BarPrsAbs 1;
BA_REL_ "GenSigVBitResp" BU_SG_REL_ BCM_HS SG_ 1217 BarPrsAbs 1;
BA_REL_ "GenSigSuprvResp" BU_SG_REL_ BCM_HS SG_ 1217 BarPrsAbs 1;
BA_REL_ "GenSigTimeoutMsg" BU_SG_REL_ BCM_HS SG_ 1217 BarPrsAbs 1217;
BA_REL_ "GenSigTimeoutTime" BU_SG_REL_ BCM_HS SG_ 1217 BarPrsAbs 1250;
BA_REL_ "GenSigSuprvResp" BU_SG_REL_ BCM_HS SG_ 985 EDADS_RcmndtFwdGr 1;
BA_REL_ "GenSigTimeoutMsg" BU_SG_REL_ BCM_HS SG_ 985 EDADS_RcmndtFwdGr 985;
BA_REL_ "GenSigTimeoutTime" BU_SG_REL_ BCM_HS SG_ 985 EDADS_RcmndtFwdGr 250;
BA_REL_ "GenSigSuprvResp" BU_SG_REL_ BCM_HS SG_ 985 EDADS_CrntFwdMsdG 1;
BA_REL_ "GenSigTimeoutMsg" BU_SG_REL_ BCM_HS SG_ 985 EDADS_CrntFwdMsdG 985;
BA_REL_ "GenSigTimeoutTime" BU_SG_REL_ BCM_HS SG_ 985 EDADS_CrntFwdMsdG 250;
BA_REL_ "GenSigSuprvResp" BU_SG_REL_ BCM_HS SG_ 985 EDADS_ShftIndStat 1;
BA_REL_ "GenSigTimeoutMsg" BU_SG_REL_ BCM_HS SG_ 985 EDADS_ShftIndStat 985;
BA_REL_ "GenSigTimeoutTime" BU_SG_REL_ BCM_HS SG_ 985 EDADS_ShftIndStat 250;
BA_REL_ "GenSigSuprvResp" BU_SG_REL_ BCM_HS SG_ 985 EDADS_EcoDrvShftIO 1;
BA_REL_ "GenSigTimeoutMsg" BU_SG_REL_ BCM_HS SG_ 985 EDADS_EcoDrvShftIO 985;
BA_REL_ "GenSigTimeoutTime" BU_SG_REL_ BCM_HS SG_ 985 EDADS_EcoDrvShftIO 250;
BA_REL_ "GenSigSuprvResp" BU_SG_REL_ VICM2_HS SG_ 1017 ACRfHiSdFldPrs 1;
BA_REL_ "GenSigTimeoutMsg" BU_SG_REL_ VICM2_HS SG_ 1017 ACRfHiSdFldPrs 1017;
BA_REL_ "GenSigTimeoutTime" BU_SG_REL_ VICM2_HS SG_ 1017 ACRfHiSdFldPrs 625;
BA_REL_ "GenSigSuprvResp" BU_SG_REL_ ICCM_OBD_HS SG_ 1017 ACRfHiSdFldPrs 1;
BA_REL_ "GenSigTimeoutMsg" BU_SG_REL_ ICCM_OBD_HS SG_ 1017 ACRfHiSdFldPrs 1017;
BA_REL_ "GenSigTimeoutTime" BU_SG_REL_ ICCM_OBD_HS SG_ 1017 ACRfHiSdFldPrs 625;
BA_REL_ "GenSigSuprvResp" BU_SG_REL_ ICCM_HS SG_ 1017 ACRfHiSdFldPrs 1;
BA_REL_ "GenSigTimeoutMsg" BU_SG_REL_ ICCM_HS SG_ 1017 ACRfHiSdFldPrs 1017;
BA_REL_ "GenSigTimeoutTime" BU_SG_REL_ ICCM_HS SG_ 1017 ACRfHiSdFldPrs 625;
BA_REL_ "GenSigSuprvResp" BU_SG_REL_ FSCM_HS SG_ 1017 ACRfHiSdFldPrs 1;
BA_REL_ "GenSigTimeoutMsg" BU_SG_REL_ FSCM_HS SG_ 1017 ACRfHiSdFldPrs 1017;
BA_REL_ "GenSigTimeoutTime" BU_SG_REL_ FSCM_HS SG_ 1017 ACRfHiSdFldPrs 625;
BA_REL_ "GenSigSuprvResp" BU_SG_REL_ VICM_HS SG_ 1017 ACRfHiSdFldPrs 1;
BA_REL_ "GenSigTimeoutMsg" BU_SG_REL_ VICM_HS SG_ 1017 ACRfHiSdFldPrs 1017;
BA_REL_ "GenSigTimeoutTime" BU_SG_REL_ VICM_HS SG_ 1017 ACRfHiSdFldPrs 625;
BA_REL_ "GenSigVBitResp" BU_SG_REL_ BCM_HS SG_ 1017 ACRfHiSdFldPrs 1;
BA_REL_ "GenSigSuprvResp" BU_SG_REL_ BCM_HS SG_ 1017 ACRfHiSdFldPrs 1;
BA_REL_ "GenSigTimeoutMsg" BU_SG_REL_ BCM_HS SG_ 1017 ACRfHiSdFldPrs 1017;
BA_REL_ "GenSigTimeoutTime" BU_SG_REL_ BCM_HS SG_ 1017 ACRfHiSdFldPrs 630;
BA_REL_ "GenSigSuprvResp" BU_SG_REL_ PTO_HS SG_ 1017 VehTopSpdLmtMdAct 1;
BA_REL_ "GenSigTimeoutMsg" BU_SG_REL_ PTO_HS SG_ 1017 VehTopSpdLmtMdAct 1017;
BA_REL_ "GenSigTimeoutTime" BU_SG_REL_ PTO_HS SG_ 1017 VehTopSpdLmtMdAct 625;
BA_REL_ "GenSigSuprvResp" BU_SG_REL_ PTO_HS SG_ 1017 VehTopSpdLmtArbVal 1;
BA_REL_ "GenSigTimeoutMsg" BU_SG_REL_ PTO_HS SG_ 1017 VehTopSpdLmtArbVal 1017;
BA_REL_ "GenSigTimeoutTime" BU_SG_REL_ PTO_HS SG_ 1017 VehTopSpdLmtArbVal 625;
BA_REL_ "GenSigVBitResp" BU_SG_REL_ BCM_HS SG_ 1017 GenFldDutCyc 1;
BA_REL_ "GenSigSuprvResp" BU_SG_REL_ BCM_HS SG_ 1017 GenFldDutCyc 1;
BA_REL_ "GenSigTimeoutMsg" BU_SG_REL_ BCM_HS SG_ 1017 GenFldDutCyc 1017;
BA_REL_ "GenSigTimeoutTime" BU_SG_REL_ BCM_HS SG_ 1017 GenFldDutCyc 630;
BA_REL_ "GenSigSuprvResp" BU_SG_REL_ BCM_HS SG_ 1017 GenFldDutCyc 1;
BA_REL_ "GenSigTimeoutMsg" BU_SG_REL_ BCM_HS SG_ 1017 GenFldDutCyc 1017;
BA_REL_ "GenSigTimeoutTime" BU_SG_REL_ BCM_HS SG_ 1017 GenFldDutCyc 625;
BA_REL_ "GenSigSuprvResp" BU_SG_REL_ VICM_HS SG_ 1017 FlInjRlCt 1;
BA_REL_ "GenSigTimeoutMsg" BU_SG_REL_ VICM_HS SG_ 1017 FlInjRlCt 1017;
BA_REL_ "GenSigTimeoutTime" BU_SG_REL_ VICM_HS SG_ 1017 FlInjRlCt 625;
BA_REL_ "GenSigSuprvResp" BU_SG_REL_ VICM_HS SG_ 1017 EngCoolFanSpd 1;
BA_REL_ "GenSigTimeoutMsg" BU_SG_REL_ VICM_HS SG_ 1017 EngCoolFanSpd 1017;
BA_REL_ "GenSigTimeoutTime" BU_SG_REL_ VICM_HS SG_ 1017 EngCoolFanSpd 625;
BA_REL_ "GenSigSuprvResp" BU_SG_REL_ VICM2_HS SG_ 1017 EngCoolFanSpd 1;
BA_REL_ "GenSigTimeoutMsg" BU_SG_REL_ VICM2_HS SG_ 1017 EngCoolFanSpd 1017;
BA_REL_ "GenSigTimeoutTime" BU_SG_REL_ VICM2_HS SG_ 1017 EngCoolFanSpd 625;
BA_REL_ "GenSigSuprvResp" BU_SG_REL_ ICCM_OBD_HS SG_ 1017 EngCoolFanSpd 1;
BA_REL_ "GenSigTimeoutMsg" BU_SG_REL_ ICCM_OBD_HS SG_ 1017 EngCoolFanSpd 1017;
BA_REL_ "GenSigTimeoutTime" BU_SG_REL_ ICCM_OBD_HS SG_ 1017 EngCoolFanSpd 625;
BA_REL_ "GenSigSuprvResp" BU_SG_REL_ ICCM_HS SG_ 1017 EngCoolFanSpd 1;
BA_REL_ "GenSigTimeoutMsg" BU_SG_REL_ ICCM_HS SG_ 1017 EngCoolFanSpd 1017;
BA_REL_ "GenSigTimeoutTime" BU_SG_REL_ ICCM_HS SG_ 1017 EngCoolFanSpd 625;
BA_REL_ "GenSigSuprvResp" BU_SG_REL_ FSCM_HS SG_ 1017 EngCoolFanSpd 1;
BA_REL_ "GenSigTimeoutMsg" BU_SG_REL_ FSCM_HS SG_ 1017 EngCoolFanSpd 1017;
BA_REL_ "GenSigTimeoutTime" BU_SG_REL_ FSCM_HS SG_ 1017 EngCoolFanSpd 625;
BA_REL_ "GenSigSuprvResp" BU_SG_REL_ BCM_HS SG_ 977 AutoMdSpdLmtStat 1;
BA_REL_ "GenSigTimeoutMsg" BU_SG_REL_ BCM_HS SG_ 977 AutoMdSpdLmtStat 977;
BA_REL_ "GenSigTimeoutTime" BU_SG_REL_ BCM_HS SG_ 977 AutoMdSpdLmtStat 250;
BA_REL_ "GenSigSuprvResp" BU_SG_REL_ TCM_HS SG_ 977 SpdLmtrSpdWrngAct 1;
BA_REL_ "GenSigTimeoutMsg" BU_SG_REL_ TCM_HS SG_ 977 SpdLmtrSpdWrngAct 977;
BA_REL_ "GenSigTimeoutTime" BU_SG_REL_ TCM_HS SG_ 977 SpdLmtrSpdWrngAct 250;
BA_REL_ "GenSigSuprvResp" BU_SG_REL_ BCM_HS SG_ 977 SpdLmtrSpdWrngAct 1;
BA_REL_ "GenSigTimeoutMsg" BU_SG_REL_ BCM_HS SG_ 977 SpdLmtrSpdWrngAct 977;
BA_REL_ "GenSigTimeoutTime" BU_SG_REL_ BCM_HS SG_ 977 SpdLmtrSpdWrngAct 250;
BA_REL_ "GenSigSuprvResp" BU_SG_REL_ VICM2_HS SG_ 977 ACCompCmnd 1;
BA_REL_ "GenSigTimeoutMsg" BU_SG_REL_ VICM2_HS SG_ 977 ACCompCmnd 977;
BA_REL_ "GenSigTimeoutTime" BU_SG_REL_ VICM2_HS SG_ 977 ACCompCmnd 250;
BA_REL_ "GenSigSuprvResp" BU_SG_REL_ ICCM_OBD_HS SG_ 977 ACCompCmnd 1;
BA_REL_ "GenSigTimeoutMsg" BU_SG_REL_ ICCM_OBD_HS SG_ 977 ACCompCmnd 977;
BA_REL_ "GenSigTimeoutTime" BU_SG_REL_ ICCM_OBD_HS SG_ 977 ACCompCmnd 250;
BA_REL_ "GenSigSuprvResp" BU_SG_REL_ ICCM_HS SG_ 977 ACCompCmnd 1;
BA_REL_ "GenSigTimeoutMsg" BU_SG_REL_ ICCM_HS SG_ 977 ACCompCmnd 977;
BA_REL_ "GenSigTimeoutTime" BU_SG_REL_ ICCM_HS SG_ 977 ACCompCmnd 250;
BA_REL_ "GenSigSuprvResp" BU_SG_REL_ FSCM_HS SG_ 977 ACCompCmnd 1;
BA_REL_ "GenSigTimeoutMsg" BU_SG_REL_ FSCM_HS SG_ 977 ACCompCmnd 977;
BA_REL_ "GenSigTimeoutTime" BU_SG_REL_ FSCM_HS SG_ 977 ACCompCmnd 250;
BA_REL_ "GenSigVBitResp" BU_SG_REL_ BCM_HS SG_ 977 EngBstPrsInd 1;
BA_REL_ "GenSigSuprvResp" BU_SG_REL_ BCM_HS SG_ 977 EngBstPrsInd 1;
BA_REL_ "GenSigTimeoutMsg" BU_SG_REL_ BCM_HS SG_ 977 EngBstPrsInd 977;
BA_REL_ "GenSigTimeoutTime" BU_SG_REL_ BCM_HS SG_ 977 EngBstPrsInd 250;
BA_REL_ "GenSigSuprvResp" BU_SG_REL_ EOCM_F_HS SG_ 977 ThrPos 1;
BA_REL_ "GenSigTimeoutMsg" BU_SG_REL_ EOCM_F_HS SG_ 977 ThrPos 977;
BA_REL_ "GenSigTimeoutTime" BU_SG_REL_ EOCM_F_HS SG_ 977 ThrPos 250;
BA_REL_ "GenSigSuprvResp" BU_SG_REL_ EOCM_F_HS SG_ 977 ThrPos 1;
BA_REL_ "GenSigTimeoutMsg" BU_SG_REL_ EOCM_F_HS SG_ 977 ThrPos 977;
BA_REL_ "GenSigTimeoutTime" BU_SG_REL_ EOCM_F_HS SG_ 977 ThrPos 250;
BA_REL_ "GenSigVBitResp" BU_SG_REL_ BCM_HS SG_ 977 ThrPos 1;
BA_REL_ "GenSigSuprvResp" BU_SG_REL_ BCM_HS SG_ 977 ThrPos 1;
BA_REL_ "GenSigTimeoutMsg" BU_SG_REL_ BCM_HS SG_ 977 ThrPos 977;
BA_REL_ "GenSigTimeoutTime" BU_SG_REL_ BCM_HS SG_ 977 ThrPos 250;
BA_REL_ "GenSigRxStartValue" BU_SG_REL_ BCM_HS SG_ 977 EngEmsRelMalfIndReq "$0 - Continuous Indication";
BA_REL_ "GenSigSuprvResp" BU_SG_REL_ TCM_HS SG_ 977 EngCstFlCutAct 1;
BA_REL_ "GenSigTimeoutMsg" BU_SG_REL_ TCM_HS SG_ 977 EngCstFlCutAct 977;
BA_REL_ "GenSigTimeoutTime" BU_SG_REL_ TCM_HS SG_ 977 EngCstFlCutAct 250;
BA_REL_ "GenSigSuprvResp" BU_SG_REL_ BCM_HS SG_ 201 Eng12vStrtrMtrCmmdOn 1;
BA_REL_ "GenSigTimeoutMsg" BU_SG_REL_ BCM_HS SG_ 201 Eng12vStrtrMtrCmmdOn 201;
BA_REL_ "GenSigTimeoutTime" BU_SG_REL_ BCM_HS SG_ 201 Eng12vStrtrMtrCmmdOn 250;
BA_REL_ "GenSigSuprvResp" BU_SG_REL_ DCDC_HS SG_ 201 Eng12vStrtrMtrCmmdOn 1;
BA_REL_ "GenSigTimeoutMsg" BU_SG_REL_ DCDC_HS SG_ 201 Eng12vStrtrMtrCmmdOn 201;
BA_REL_ "GenSigTimeoutTime" BU_SG_REL_ DCDC_HS SG_ 201 Eng12vStrtrMtrCmmdOn 250;
BA_REL_ "GenSigSuprvResp" BU_SG_REL_ TCCM_HS SG_ 201 Eng12vStrtrMtrCmmdOn 1;
BA_REL_ "GenSigTimeoutMsg" BU_SG_REL_ TCCM_HS SG_ 201 Eng12vStrtrMtrCmmdOn 201;
BA_REL_ "GenSigTimeoutTime" BU_SG_REL_ TCCM_HS SG_ 201 Eng12vStrtrMtrCmmdOn 31;
BA_REL_ "GenSigSuprvResp" BU_SG_REL_ VES_HS SG_ 201 Eng12vStrtrMtrCmmdOn 1;
BA_REL_ "GenSigTimeoutMsg" BU_SG_REL_ VES_HS SG_ 201 Eng12vStrtrMtrCmmdOn 201;
BA_REL_ "GenSigTimeoutTime" BU_SG_REL_ VES_HS SG_ 201 Eng12vStrtrMtrCmmdOn 250;
BA_REL_ "GenSigSuprvResp" BU_SG_REL_ EPS_HS SG_ 201 Eng12vStrtrMtrCmmdOn 1;
BA_REL_ "GenSigTimeoutMsg" BU_SG_REL_ EPS_HS SG_ 201 Eng12vStrtrMtrCmmdOn 201;
BA_REL_ "GenSigTimeoutTime" BU_SG_REL_ EPS_HS SG_ 201 Eng12vStrtrMtrCmmdOn 250;
BA_REL_ "GenSigSuprvResp" BU_SG_REL_ VICM_HS SG_ 201 EngCntrlRunCrnkTrmSt 1;
BA_REL_ "GenSigTimeoutMsg" BU_SG_REL_ VICM_HS SG_ 201 EngCntrlRunCrnkTrmSt 201;
BA_REL_ "GenSigTimeoutTime" BU_SG_REL_ VICM_HS SG_ 201 EngCntrlRunCrnkTrmSt 250;
BA_REL_ "GenSigSuprvResp" BU_SG_REL_ FSCM_ITBC_HS SG_ 201 EngCntrlRunCrnkTrmSt 1;
BA_REL_ "GenSigTimeoutMsg" BU_SG_REL_ FSCM_ITBC_HS SG_ 201 EngCntrlRunCrnkTrmSt 201;
BA_REL_ "GenSigTimeoutTime" BU_SG_REL_ FSCM_ITBC_HS SG_ 201 EngCntrlRunCrnkTrmSt 250;
BA_REL_ "GenSigSuprvResp" BU_SG_REL_ FSCM_ITBC_HS SG_ 201 EngCntrlRunCrnkTrmSt 1;
BA_REL_ "GenSigTimeoutMsg" BU_SG_REL_ FSCM_ITBC_HS SG_ 201 EngCntrlRunCrnkTrmSt 201;
BA_REL_ "GenSigTimeoutTime" BU_SG_REL_ FSCM_ITBC_HS SG_ 201 EngCntrlRunCrnkTrmSt 250;
BA_REL_ "GenSigSuprvResp" BU_SG_REL_ VICM2_HS SG_ 201 EngCntrlRunCrnkTrmSt 1;
BA_REL_ "GenSigTimeoutMsg" BU_SG_REL_ VICM2_HS SG_ 201 EngCntrlRunCrnkTrmSt 201;
BA_REL_ "GenSigTimeoutTime" BU_SG_REL_ VICM2_HS SG_ 201 EngCntrlRunCrnkTrmSt 250;
BA_REL_ "GenSigSuprvResp" BU_SG_REL_ FSCM_HS SG_ 201 EngCntrlRunCrnkTrmSt 1;
BA_REL_ "GenSigTimeoutMsg" BU_SG_REL_ FSCM_HS SG_ 201 EngCntrlRunCrnkTrmSt 201;
BA_REL_ "GenSigTimeoutTime" BU_SG_REL_ FSCM_HS SG_ 201 EngCntrlRunCrnkTrmSt 250;
BA_REL_ "GenSigSuprvResp" BU_SG_REL_ FSCM_HS SG_ 201 EngCntrlRunCrnkTrmSt 1;
BA_REL_ "GenSigTimeoutMsg" BU_SG_REL_ FSCM_HS SG_ 201 EngCntrlRunCrnkTrmSt 201;
BA_REL_ "GenSigTimeoutTime" BU_SG_REL_ FSCM_HS SG_ 201 EngCntrlRunCrnkTrmSt 250;
BA_REL_ "GenSigSuprvResp" BU_SG_REL_ FSCM_HS SG_ 201 EngCntrlRunCrnkTrmSt 1;
BA_REL_ "GenSigTimeoutMsg" BU_SG_REL_ FSCM_HS SG_ 201 EngCntrlRunCrnkTrmSt 201;
BA_REL_ "GenSigTimeoutTime" BU_SG_REL_ FSCM_HS SG_ 201 EngCntrlRunCrnkTrmSt 250;
BA_REL_ "GenSigSuprvResp" BU_SG_REL_ ICCM_OBD_HS SG_ 201 EngCntrlRunCrnkTrmSt 1;
BA_REL_ "GenSigTimeoutMsg" BU_SG_REL_ ICCM_OBD_HS SG_ 201 EngCntrlRunCrnkTrmSt 201;
BA_REL_ "GenSigTimeoutTime" BU_SG_REL_ ICCM_OBD_HS SG_ 201 EngCntrlRunCrnkTrmSt 250;
BA_REL_ "GenSigSuprvResp" BU_SG_REL_ ICCM_OBD_HS SG_ 201 EngCntrlRunCrnkTrmSt 1;
BA_REL_ "GenSigTimeoutMsg" BU_SG_REL_ ICCM_OBD_HS SG_ 201 EngCntrlRunCrnkTrmSt 201;
BA_REL_ "GenSigTimeoutTime" BU_SG_REL_ ICCM_OBD_HS SG_ 201 EngCntrlRunCrnkTrmSt 250;
BA_REL_ "GenSigSuprvResp" BU_SG_REL_ ICCM_OBD_HS SG_ 201 EngCntrlRunCrnkTrmSt 1;
BA_REL_ "GenSigTimeoutMsg" BU_SG_REL_ ICCM_OBD_HS SG_ 201 EngCntrlRunCrnkTrmSt 201;
BA_REL_ "GenSigTimeoutTime" BU_SG_REL_ ICCM_OBD_HS SG_ 201 EngCntrlRunCrnkTrmSt 250;
BA_REL_ "GenSigSuprvResp" BU_SG_REL_ ICCM_HS SG_ 201 EngCntrlRunCrnkTrmSt 1;
BA_REL_ "GenSigTimeoutMsg" BU_SG_REL_ ICCM_HS SG_ 201 EngCntrlRunCrnkTrmSt 201;
BA_REL_ "GenSigTimeoutTime" BU_SG_REL_ ICCM_HS SG_ 201 EngCntrlRunCrnkTrmSt 250;
BA_REL_ "GenSigSuprvResp" BU_SG_REL_ ICCM_HS SG_ 201 EngCntrlRunCrnkTrmSt 1;
BA_REL_ "GenSigTimeoutMsg" BU_SG_REL_ ICCM_HS SG_ 201 EngCntrlRunCrnkTrmSt 201;
BA_REL_ "GenSigTimeoutTime" BU_SG_REL_ ICCM_HS SG_ 201 EngCntrlRunCrnkTrmSt 250;
BA_REL_ "GenSigSuprvResp" BU_SG_REL_ ICCM_HS SG_ 201 EngCntrlRunCrnkTrmSt 1;
BA_REL_ "GenSigTimeoutMsg" BU_SG_REL_ ICCM_HS SG_ 201 EngCntrlRunCrnkTrmSt 201;
BA_REL_ "GenSigTimeoutTime" BU_SG_REL_ ICCM_HS SG_ 201 EngCntrlRunCrnkTrmSt 250;
BA_REL_ "GenSigSuprvResp" BU_SG_REL_ PTO_HS SG_ 201 SpdLmtrSpdWrngEnbld 1;
BA_REL_ "GenSigTimeoutMsg" BU_SG_REL_ PTO_HS SG_ 201 SpdLmtrSpdWrngEnbld 201;
BA_REL_ "GenSigTimeoutTime" BU_SG_REL_ PTO_HS SG_ 201 SpdLmtrSpdWrngEnbld 250;
BA_REL_ "GenSigSuprvResp" BU_SG_REL_ ICCM_OBD_HS SG_ 201 EngCylDactEvntPndg 1;
BA_REL_ "GenSigTimeoutMsg" BU_SG_REL_ ICCM_OBD_HS SG_ 201 EngCylDactEvntPndg 201;
BA_REL_ "GenSigTimeoutTime" BU_SG_REL_ ICCM_OBD_HS SG_ 201 EngCylDactEvntPndg 250;
BA_REL_ "GenSigSuprvResp" BU_SG_REL_ ICCM_HS SG_ 201 EngCylDactEvntPndg 1;
BA_REL_ "GenSigTimeoutMsg" BU_SG_REL_ ICCM_HS SG_ 201 EngCylDactEvntPndg 201;
BA_REL_ "GenSigTimeoutTime" BU_SG_REL_ ICCM_HS SG_ 201 EngCylDactEvntPndg 250;
BA_REL_ "GenSigSuprvResp" BU_SG_REL_ FSCM_ITBC_HS SG_ 201 EngCylDactEvntPndg 1;
BA_REL_ "GenSigTimeoutMsg" BU_SG_REL_ FSCM_ITBC_HS SG_ 201 EngCylDactEvntPndg 201;
BA_REL_ "GenSigTimeoutTime" BU_SG_REL_ FSCM_ITBC_HS SG_ 201 EngCylDactEvntPndg 250;
BA_REL_ "GenSigSuprvResp" BU_SG_REL_ FSCM_HS SG_ 201 EngCylDactEvntPndg 1;
BA_REL_ "GenSigTimeoutMsg" BU_SG_REL_ FSCM_HS SG_ 201 EngCylDactEvntPndg 201;
BA_REL_ "GenSigTimeoutTime" BU_SG_REL_ FSCM_HS SG_ 201 EngCylDactEvntPndg 250;
BA_REL_ "GenSigSuprvResp" BU_SG_REL_ AMP_HS SG_ 201 EngCylDactEvntPndg 1;
BA_REL_ "GenSigTimeoutMsg" BU_SG_REL_ AMP_HS SG_ 201 EngCylDactEvntPndg 201;
BA_REL_ "GenSigTimeoutTime" BU_SG_REL_ AMP_HS SG_ 201 EngCylDactEvntPndg 250;
BA_REL_ "GenSigSuprvResp" BU_SG_REL_ FSCM_ITBC_HS SG_ 201 EngCylDeactMd 1;
BA_REL_ "GenSigTimeoutMsg" BU_SG_REL_ FSCM_ITBC_HS SG_ 201 EngCylDeactMd 201;
BA_REL_ "GenSigTimeoutTime" BU_SG_REL_ FSCM_ITBC_HS SG_ 201 EngCylDeactMd 250;
BA_REL_ "GenSigSuprvResp" BU_SG_REL_ FSCM_HS SG_ 201 EngCylDeactMd 1;
BA_REL_ "GenSigTimeoutMsg" BU_SG_REL_ FSCM_HS SG_ 201 EngCylDeactMd 201;
BA_REL_ "GenSigTimeoutTime" BU_SG_REL_ FSCM_HS SG_ 201 EngCylDeactMd 250;
BA_REL_ "GenSigSuprvResp" BU_SG_REL_ ICCM_OBD_HS SG_ 201 EngCylDeactMd 1;
BA_REL_ "GenSigTimeoutMsg" BU_SG_REL_ ICCM_OBD_HS SG_ 201 EngCylDeactMd 201;
BA_REL_ "GenSigTimeoutTime" BU_SG_REL_ ICCM_OBD_HS SG_ 201 EngCylDeactMd 250;
BA_REL_ "GenSigSuprvResp" BU_SG_REL_ ICCM_OBD_HS SG_ 201 EngCylDeactMd 1;
BA_REL_ "GenSigTimeoutMsg" BU_SG_REL_ ICCM_OBD_HS SG_ 201 EngCylDeactMd 201;
BA_REL_ "GenSigTimeoutTime" BU_SG_REL_ ICCM_OBD_HS SG_ 201 EngCylDeactMd 250;
BA_REL_ "GenSigSuprvResp" BU_SG_REL_ ICCM_HS SG_ 201 EngCylDeactMd 1;
BA_REL_ "GenSigTimeoutMsg" BU_SG_REL_ ICCM_HS SG_ 201 EngCylDeactMd 201;
BA_REL_ "GenSigTimeoutTime" BU_SG_REL_ ICCM_HS SG_ 201 EngCylDeactMd 250;
BA_REL_ "GenSigSuprvResp" BU_SG_REL_ ICCM_HS SG_ 201 EngCylDeactMd 1;
BA_REL_ "GenSigTimeoutMsg" BU_SG_REL_ ICCM_HS SG_ 201 EngCylDeactMd 201;
BA_REL_ "GenSigTimeoutTime" BU_SG_REL_ ICCM_HS SG_ 201 EngCylDeactMd 250;
BA_REL_ "GenSigSuprvResp" BU_SG_REL_ AMP_HS SG_ 201 EngCylDeactMd 1;
BA_REL_ "GenSigTimeoutMsg" BU_SG_REL_ AMP_HS SG_ 201 EngCylDeactMd 201;
BA_REL_ "GenSigTimeoutTime" BU_SG_REL_ AMP_HS SG_ 201 EngCylDeactMd 250;
BA_REL_ "GenSigSuprvResp" BU_SG_REL_ EBCM_OBD_HS SG_ 201 RmVhStrtEngRng 1;
BA_REL_ "GenSigTimeoutMsg" BU_SG_REL_ EBCM_OBD_HS SG_ 201 RmVhStrtEngRng 201;
BA_REL_ "GenSigTimeoutTime" BU_SG_REL_ EBCM_OBD_HS SG_ 201 RmVhStrtEngRng 250;
BA_REL_ "GenSigSuprvResp" BU_SG_REL_ EBCM_HS SG_ 201 RmVhStrtEngRng 1;
BA_REL_ "GenSigTimeoutMsg" BU_SG_REL_ EBCM_HS SG_ 201 RmVhStrtEngRng 201;
BA_REL_ "GenSigTimeoutTime" BU_SG_REL_ EBCM_HS SG_ 201 RmVhStrtEngRng 250;
BA_REL_ "GenSigSuprvResp" BU_SG_REL_ EPB_HS SG_ 201 RmVhStrtEngRng 1;
BA_REL_ "GenSigTimeoutMsg" BU_SG_REL_ EPB_HS SG_ 201 RmVhStrtEngRng 201;
BA_REL_ "GenSigTimeoutTime" BU_SG_REL_ EPB_HS SG_ 201 RmVhStrtEngRng 250;
BA_REL_ "GenSigSuprvResp" BU_SG_REL_ BCM_HS SG_ 201 RmVhStrtEngRng 2;
BA_REL_ "GenSigTimeoutMsg" BU_SG_REL_ BCM_HS SG_ 201 RmVhStrtEngRng 201;
BA_REL_ "GenSigTimeoutTime" BU_SG_REL_ BCM_HS SG_ 201 RmVhStrtEngRng 50;
BA_REL_ "GenSigRxStartValue" BU_SG_REL_ ACC_HS SG_ 201 DrThrtlOvrrdDetProtVal "0";
BA_REL_ "GenSigRxStartValue" BU_SG_REL_ BCM_HS SG_ 201 PltfrmEngSpdCmdInhtRq "$0-Allow Platform Engine Speed Control";
BA_REL_ "GenSigRxStartValue" BU_SG_REL_ PTO_HS SG_ 201 PltfrmEngSpdCmdInhtRq "$0-Allow Platform Engine Speed Control";
BA_REL_ "GenSigSuprvResp" BU_SG_REL_ PTO_HS SG_ 201 PltfrmEngSpdCmdInhtRq 1;
BA_REL_ "GenSigTimeoutMsg" BU_SG_REL_ PTO_HS SG_ 201 PltfrmEngSpdCmdInhtRq 201;
BA_REL_ "GenSigTimeoutTime" BU_SG_REL_ PTO_HS SG_ 201 PltfrmEngSpdCmdInhtRq 30;
BA_REL_ "GenSigSuprvResp" BU_SG_REL_ ACC_HS SG_ 201 PT_BrkPedDscrtInpStat 1;
BA_REL_ "GenSigTimeoutMsg" BU_SG_REL_ ACC_HS SG_ 201 PT_BrkPedDscrtInpStat 201;
BA_REL_ "GenSigTimeoutTime" BU_SG_REL_ ACC_HS SG_ 201 PT_BrkPedDscrtInpStat 250;
BA_REL_ "GenSigSuprvResp" BU_SG_REL_ VICM_HS SG_ 201 AccActPos 1;
BA_REL_ "GenSigTimeoutMsg" BU_SG_REL_ VICM_HS SG_ 201 AccActPos 201;
BA_REL_ "GenSigTimeoutTime" BU_SG_REL_ VICM_HS SG_ 201 AccActPos 250;
BA_REL_ "GenSigSuprvResp" BU_SG_REL_ EPB_HS SG_ 201 AccActPos 1;
BA_REL_ "GenSigTimeoutMsg" BU_SG_REL_ EPB_HS SG_ 201 AccActPos 201;
BA_REL_ "GenSigTimeoutTime" BU_SG_REL_ EPB_HS SG_ 201 AccActPos 250;
BA_REL_ "GenSigVBitResp" BU_SG_REL_ SADS_HS SG_ 201 AccActPos 1;
BA_REL_ "GenSigSuprvResp" BU_SG_REL_ SADS_HS SG_ 201 AccActPos 1;
BA_REL_ "GenSigTimeoutMsg" BU_SG_REL_ SADS_HS SG_ 201 AccActPos 201;
BA_REL_ "GenSigTimeoutTime" BU_SG_REL_ SADS_HS SG_ 201 AccActPos 250;
BA_REL_ "GenSigVBitResp" BU_SG_REL_ BCM_HS SG_ 201 AccActPos 1;
BA_REL_ "GenSigSuprvResp" BU_SG_REL_ BCM_HS SG_ 201 AccActPos 1;
BA_REL_ "GenSigTimeoutMsg" BU_SG_REL_ BCM_HS SG_ 201 AccActPos 201;
BA_REL_ "GenSigTimeoutTime" BU_SG_REL_ BCM_HS SG_ 201 AccActPos 50;
BA_REL_ "GenSigSuprvResp" BU_SG_REL_ TCM_HS SG_ 201 AccActPos 1;
BA_REL_ "GenSigTimeoutMsg" BU_SG_REL_ TCM_HS SG_ 201 AccActPos 201;
BA_REL_ "GenSigTimeoutTime" BU_SG_REL_ TCM_HS SG_ 201 AccActPos 250;
BA_REL_ "GenSigSuprvResp" BU_SG_REL_ PTO_HS SG_ 201 CrsCntEnbld 1;
BA_REL_ "GenSigTimeoutMsg" BU_SG_REL_ PTO_HS SG_ 201 CrsCntEnbld 201;
BA_REL_ "GenSigTimeoutTime" BU_SG_REL_ PTO_HS SG_ 201 CrsCntEnbld 250;
BA_REL_ "GenSigRxStartValue" BU_SG_REL_ ACC_HS SG_ 201 CrsCntEnbld "0";
BA_REL_ "GenSigSuprvResp" BU_SG_REL_ ACC_HS SG_ 201 CrsCntEnbld 1;
BA_REL_ "GenSigTimeoutMsg" BU_SG_REL_ ACC_HS SG_ 201 CrsCntEnbld 201;
BA_REL_ "GenSigTimeoutTime" BU_SG_REL_ ACC_HS SG_ 201 CrsCntEnbld 250;
BA_REL_ "GenSigSuprvResp" BU_SG_REL_ EOCM_F_HS SG_ 201 CrsCntEnbld 1;
BA_REL_ "GenSigTimeoutMsg" BU_SG_REL_ EOCM_F_HS SG_ 201 CrsCntEnbld 201;
BA_REL_ "GenSigTimeoutTime" BU_SG_REL_ EOCM_F_HS SG_ 201 CrsCntEnbld 120;
BA_REL_ "GenSigSuprvResp" BU_SG_REL_ TCM_HS SG_ 201 CrsCntAtv 1;
BA_REL_ "GenSigTimeoutMsg" BU_SG_REL_ TCM_HS SG_ 201 CrsCntAtv 201;
BA_REL_ "GenSigTimeoutTime" BU_SG_REL_ TCM_HS SG_ 201 CrsCntAtv 31;
BA_REL_ "GenSigSuprvResp" BU_SG_REL_ ACC_HS SG_ 201 DrvThrottlOvrrdDet 1;
BA_REL_ "GenSigTimeoutMsg" BU_SG_REL_ ACC_HS SG_ 201 DrvThrottlOvrrdDet 201;
BA_REL_ "GenSigTimeoutTime" BU_SG_REL_ ACC_HS SG_ 201 DrvThrottlOvrrdDet 250;
BA_REL_ "GenSigSuprvResp" BU_SG_REL_ VCM_HS SG_ 201 PT_CrnkAct 1;
BA_REL_ "GenSigTimeoutMsg" BU_SG_REL_ VCM_HS SG_ 201 PT_CrnkAct 201;
BA_REL_ "GenSigTimeoutTime" BU_SG_REL_ VCM_HS SG_ 201 PT_CrnkAct 1250;
BA_REL_ "GenSigSuprvResp" BU_SG_REL_ VES_HS SG_ 201 PT_CrnkAct 1;
BA_REL_ "GenSigTimeoutMsg" BU_SG_REL_ VES_HS SG_ 201 PT_CrnkAct 201;
BA_REL_ "GenSigTimeoutTime" BU_SG_REL_ VES_HS SG_ 201 PT_CrnkAct 250;
BA_REL_ "GenSigSuprvResp" BU_SG_REL_ EPS_HS SG_ 201 PT_CrnkAct 1;
BA_REL_ "GenSigTimeoutMsg" BU_SG_REL_ EPS_HS SG_ 201 PT_CrnkAct 201;
BA_REL_ "GenSigTimeoutTime" BU_SG_REL_ EPS_HS SG_ 201 PT_CrnkAct 250;
BA_REL_ "GenSigSuprvResp" BU_SG_REL_ EBCM_OBD_HS SG_ 201 PT_CrnkAct 1;
BA_REL_ "GenSigTimeoutMsg" BU_SG_REL_ EBCM_OBD_HS SG_ 201 PT_CrnkAct 201;
BA_REL_ "GenSigTimeoutTime" BU_SG_REL_ EBCM_OBD_HS SG_ 201 PT_CrnkAct 250;
BA_REL_ "GenSigSuprvResp" BU_SG_REL_ EBCM_HS SG_ 201 PT_CrnkAct 1;
BA_REL_ "GenSigTimeoutMsg" BU_SG_REL_ EBCM_HS SG_ 201 PT_CrnkAct 201;
BA_REL_ "GenSigTimeoutTime" BU_SG_REL_ EBCM_HS SG_ 201 PT_CrnkAct 250;
BA_REL_ "GenSigSuprvRespSubValue" BU_SG_REL_ BCM_HS SG_ 201 PTRunAbrt 1;
BA_REL_ "GenSigSuprvResp" BU_SG_REL_ BCM_HS SG_ 201 PTRunAbrt 2;
BA_REL_ "GenSigTimeoutMsg" BU_SG_REL_ BCM_HS SG_ 201 PTRunAbrt 201;
BA_REL_ "GenSigTimeoutTime" BU_SG_REL_ BCM_HS SG_ 201 PTRunAbrt 50;
BA_REL_ "GenSigSuprvResp" BU_SG_REL_ PTO_HS SG_ 201 PTO_PT_RunAbrtd 1;
BA_REL_ "GenSigTimeoutMsg" BU_SG_REL_ PTO_HS SG_ 201 PTO_PT_RunAbrtd 201;
BA_REL_ "GenSigTimeoutTime" BU_SG_REL_ PTO_HS SG_ 201 PTO_PT_RunAbrtd 250;
BA_REL_ "GenSigSuprvResp" BU_SG_REL_ PFAF_HS SG_ 201 EngSpdStat 1;
BA_REL_ "GenSigTimeoutMsg" BU_SG_REL_ PFAF_HS SG_ 201 EngSpdStat 201;
BA_REL_ "GenSigTimeoutTime" BU_SG_REL_ PFAF_HS SG_ 201 EngSpdStat 250;
BA_REL_ "GenSigSuprvResp" BU_SG_REL_ PTO_HS SG_ 201 EngSpdStat 1;
BA_REL_ "GenSigTimeoutMsg" BU_SG_REL_ PTO_HS SG_ 201 EngSpdStat 201;
BA_REL_ "GenSigTimeoutTime" BU_SG_REL_ PTO_HS SG_ 201 EngSpdStat 250;
BA_REL_ "GenSigSuprvResp" BU_SG_REL_ AHL_AFL_HS SG_ 201 EngSpdStat 1;
BA_REL_ "GenSigTimeoutMsg" BU_SG_REL_ AHL_AFL_HS SG_ 201 EngSpdStat 201;
BA_REL_ "GenSigTimeoutTime" BU_SG_REL_ AHL_AFL_HS SG_ 201 EngSpdStat 250;
BA_REL_ "GenSigSuprvResp" BU_SG_REL_ AMP_HS SG_ 201 EngSpdStat 1;
BA_REL_ "GenSigTimeoutMsg" BU_SG_REL_ AMP_HS SG_ 201 EngSpdStat 201;
BA_REL_ "GenSigTimeoutTime" BU_SG_REL_ AMP_HS SG_ 201 EngSpdStat 250;
BA_REL_ "GenSigSuprvResp" BU_SG_REL_ VES_HS SG_ 201 EngSpdStat 1;
BA_REL_ "GenSigTimeoutMsg" BU_SG_REL_ VES_HS SG_ 201 EngSpdStat 201;
BA_REL_ "GenSigTimeoutTime" BU_SG_REL_ VES_HS SG_ 201 EngSpdStat 250;
BA_REL_ "GenSigSuprvResp" BU_SG_REL_ EPS_HS SG_ 201 EngSpdStat 1;
BA_REL_ "GenSigTimeoutMsg" BU_SG_REL_ EPS_HS SG_ 201 EngSpdStat 201;
BA_REL_ "GenSigTimeoutTime" BU_SG_REL_ EPS_HS SG_ 201 EngSpdStat 250;
BA_REL_ "GenSigSuprvResp" BU_SG_REL_ PFAF_HS SG_ 201 EngSpd 1;
BA_REL_ "GenSigTimeoutMsg" BU_SG_REL_ PFAF_HS SG_ 201 EngSpd 201;
BA_REL_ "GenSigTimeoutTime" BU_SG_REL_ PFAF_HS SG_ 201 EngSpd 250;
BA_REL_ "GenSigSuprvResp" BU_SG_REL_ DCDC_HS SG_ 201 EngSpd 1;
BA_REL_ "GenSigTimeoutMsg" BU_SG_REL_ DCDC_HS SG_ 201 EngSpd 201;
BA_REL_ "GenSigTimeoutTime" BU_SG_REL_ DCDC_HS SG_ 201 EngSpd 250;
BA_REL_ "GenSigSuprvResp" BU_SG_REL_ PTO_HS SG_ 201 EngSpd 1;
BA_REL_ "GenSigTimeoutMsg" BU_SG_REL_ PTO_HS SG_ 201 EngSpd 201;
BA_REL_ "GenSigTimeoutTime" BU_SG_REL_ PTO_HS SG_ 201 EngSpd 250;
BA_REL_ "GenSigSuprvResp" BU_SG_REL_ AHL_AFL_HS SG_ 201 EngSpd 1;
BA_REL_ "GenSigTimeoutMsg" BU_SG_REL_ AHL_AFL_HS SG_ 201 EngSpd 201;
BA_REL_ "GenSigTimeoutTime" BU_SG_REL_ AHL_AFL_HS SG_ 201 EngSpd 250;
BA_REL_ "GenSigSuprvResp" BU_SG_REL_ VICM2_HS SG_ 201 EngSpd 1;
BA_REL_ "GenSigTimeoutMsg" BU_SG_REL_ VICM2_HS SG_ 201 EngSpd 201;
BA_REL_ "GenSigTimeoutTime" BU_SG_REL_ VICM2_HS SG_ 201 EngSpd 250;
BA_REL_ "GenSigSuprvResp" BU_SG_REL_ EOCM_F_HS SG_ 201 EngSpd 1;
BA_REL_ "GenSigTimeoutMsg" BU_SG_REL_ EOCM_F_HS SG_ 201 EngSpd 201;
BA_REL_ "GenSigTimeoutTime" BU_SG_REL_ EOCM_F_HS SG_ 201 EngSpd 120;
BA_REL_ "GenSigSuprvResp" BU_SG_REL_ AMP_HS SG_ 201 EngSpd 1;
BA_REL_ "GenSigTimeoutMsg" BU_SG_REL_ AMP_HS SG_ 201 EngSpd 201;
BA_REL_ "GenSigTimeoutTime" BU_SG_REL_ AMP_HS SG_ 201 EngSpd 250;
BA_REL_ "GenSigSuprvResp" BU_SG_REL_ VICM_HS SG_ 201 EngSpd 1;
BA_REL_ "GenSigTimeoutMsg" BU_SG_REL_ VICM_HS SG_ 201 EngSpd 201;
BA_REL_ "GenSigTimeoutTime" BU_SG_REL_ VICM_HS SG_ 201 EngSpd 250;
BA_REL_ "GenSigSuprvResp" BU_SG_REL_ VICM_HS SG_ 201 EngSpd 1;
BA_REL_ "GenSigTimeoutMsg" BU_SG_REL_ VICM_HS SG_ 201 EngSpd 201;
BA_REL_ "GenSigTimeoutTime" BU_SG_REL_ VICM_HS SG_ 201 EngSpd 250;
BA_REL_ "GenSigSuprvResp" BU_SG_REL_ VES_HS SG_ 201 EngSpd 1;
BA_REL_ "GenSigTimeoutMsg" BU_SG_REL_ VES_HS SG_ 201 EngSpd 201;
BA_REL_ "GenSigTimeoutTime" BU_SG_REL_ VES_HS SG_ 201 EngSpd 250;
BA_REL_ "GenSigSuprvResp" BU_SG_REL_ EPS_HS SG_ 201 EngSpd 1;
BA_REL_ "GenSigTimeoutMsg" BU_SG_REL_ EPS_HS SG_ 201 EngSpd 201;
BA_REL_ "GenSigTimeoutTime" BU_SG_REL_ EPS_HS SG_ 201 EngSpd 250;
BA_REL_ "GenSigSuprvResp" BU_SG_REL_ BCP_HS SG_ 201 EngSpd 1;
BA_REL_ "GenSigTimeoutMsg" BU_SG_REL_ BCP_HS SG_ 201 EngSpd 201;
BA_REL_ "GenSigTimeoutTime" BU_SG_REL_ BCP_HS SG_ 201 EngSpd 250;
BA_REL_ "GenSigSuprvResp" BU_SG_REL_ EPB_HS SG_ 201 EngSpd 1;
BA_REL_ "GenSigTimeoutMsg" BU_SG_REL_ EPB_HS SG_ 201 EngSpd 201;
BA_REL_ "GenSigTimeoutTime" BU_SG_REL_ EPB_HS SG_ 201 EngSpd 250;
BA_REL_ "GenSigSuprvResp" BU_SG_REL_ RDCM_HS SG_ 201 EngSpd 1;
BA_REL_ "GenSigTimeoutMsg" BU_SG_REL_ RDCM_HS SG_ 201 EngSpd 201;
BA_REL_ "GenSigTimeoutTime" BU_SG_REL_ RDCM_HS SG_ 201 EngSpd 250;
BA_REL_ "GenSigSuprvResp" BU_SG_REL_ ACC_HS SG_ 201 EngSpd 1;
BA_REL_ "GenSigTimeoutMsg" BU_SG_REL_ ACC_HS SG_ 201 EngSpd 201;
BA_REL_ "GenSigTimeoutTime" BU_SG_REL_ ACC_HS SG_ 201 EngSpd 120;
BA_REL_ "GenSigSuprvResp" BU_SG_REL_ BCM_HS SG_ 201 EngSpd 1;
BA_REL_ "GenSigTimeoutMsg" BU_SG_REL_ BCM_HS SG_ 201 EngSpd 201;
BA_REL_ "GenSigTimeoutTime" BU_SG_REL_ BCM_HS SG_ 201 EngSpd 250;
BA_REL_ "GenSigSuprvResp" BU_SG_REL_ BCM_HS SG_ 201 EngSpd 1;
BA_REL_ "GenSigTimeoutMsg" BU_SG_REL_ BCM_HS SG_ 201 EngSpd 201;
BA_REL_ "GenSigTimeoutTime" BU_SG_REL_ BCM_HS SG_ 201 EngSpd 250;
BA_REL_ "GenSigSuprvResp" BU_SG_REL_ BCM_HS SG_ 201 EngSpd 1;
BA_REL_ "GenSigTimeoutMsg" BU_SG_REL_ BCM_HS SG_ 201 EngSpd 201;
BA_REL_ "GenSigTimeoutTime" BU_SG_REL_ BCM_HS SG_ 201 EngSpd 250;
BA_REL_ "GenSigSuprvResp" BU_SG_REL_ BCM_HS SG_ 201 EngSpd 1;
BA_REL_ "GenSigTimeoutMsg" BU_SG_REL_ BCM_HS SG_ 201 EngSpd 201;
BA_REL_ "GenSigTimeoutTime" BU_SG_REL_ BCM_HS SG_ 201 EngSpd 50;
BA_REL_ "GenSigSuprvResp" BU_SG_REL_ BCM_HS SG_ 201 EngSpd 1;
BA_REL_ "GenSigTimeoutMsg" BU_SG_REL_ BCM_HS SG_ 201 EngSpd 201;
BA_REL_ "GenSigTimeoutTime" BU_SG_REL_ BCM_HS SG_ 201 EngSpd 250;
BA_REL_ "GenSigSuprvResp" BU_SG_REL_ DCDC_HS SG_ 201 EngRunAtv 1;
BA_REL_ "GenSigTimeoutMsg" BU_SG_REL_ DCDC_HS SG_ 201 EngRunAtv 201;
BA_REL_ "GenSigTimeoutTime" BU_SG_REL_ DCDC_HS SG_ 201 EngRunAtv 250;
BA_REL_ "GenSigSuprvResp" BU_SG_REL_ VCM_HS SG_ 201 EngRunAtv 1;
BA_REL_ "GenSigTimeoutMsg" BU_SG_REL_ VCM_HS SG_ 201 EngRunAtv 201;
BA_REL_ "GenSigTimeoutTime" BU_SG_REL_ VCM_HS SG_ 201 EngRunAtv 1250;
BA_REL_ "GenSigSuprvResp" BU_SG_REL_ AMP_HS SG_ 201 EngRunAtv 1;
BA_REL_ "GenSigTimeoutMsg" BU_SG_REL_ AMP_HS SG_ 201 EngRunAtv 201;
BA_REL_ "GenSigTimeoutTime" BU_SG_REL_ AMP_HS SG_ 201 EngRunAtv 250;
BA_REL_ "GenSigSuprvResp" BU_SG_REL_ VICM2_HS SG_ 201 EngRunAtv 1;
BA_REL_ "GenSigTimeoutMsg" BU_SG_REL_ VICM2_HS SG_ 201 EngRunAtv 201;
BA_REL_ "GenSigTimeoutTime" BU_SG_REL_ VICM2_HS SG_ 201 EngRunAtv 250;
BA_REL_ "GenSigSuprvResp" BU_SG_REL_ ACC_HS SG_ 201 EngRunAtv 2;
BA_REL_ "GenSigTimeoutMsg" BU_SG_REL_ ACC_HS SG_ 201 EngRunAtv 201;
BA_REL_ "GenSigTimeoutTime" BU_SG_REL_ ACC_HS SG_ 201 EngRunAtv 120;
BA_REL_ "GenSigSuprvResp" BU_SG_REL_ VICM_HS SG_ 201 EngRunAtv 1;
BA_REL_ "GenSigTimeoutMsg" BU_SG_REL_ VICM_HS SG_ 201 EngRunAtv 201;
BA_REL_ "GenSigTimeoutTime" BU_SG_REL_ VICM_HS SG_ 201 EngRunAtv 250;
BA_REL_ "GenSigSuprvResp" BU_SG_REL_ VICM_HS SG_ 201 EngRunAtv 1;
BA_REL_ "GenSigTimeoutMsg" BU_SG_REL_ VICM_HS SG_ 201 EngRunAtv 201;
BA_REL_ "GenSigTimeoutTime" BU_SG_REL_ VICM_HS SG_ 201 EngRunAtv 250;
BA_REL_ "GenSigSuprvResp" BU_SG_REL_ APPS_HS SG_ 201 EngRunAtv 1;
BA_REL_ "GenSigTimeoutMsg" BU_SG_REL_ APPS_HS SG_ 201 EngRunAtv 201;
BA_REL_ "GenSigTimeoutTime" BU_SG_REL_ APPS_HS SG_ 201 EngRunAtv 250;
BA_REL_ "GenSigSuprvResp" BU_SG_REL_ EOCM_F_HS SG_ 201 EngRunAtv 2;
BA_REL_ "GenSigTimeoutMsg" BU_SG_REL_ EOCM_F_HS SG_ 201 EngRunAtv 201;
BA_REL_ "GenSigTimeoutTime" BU_SG_REL_ EOCM_F_HS SG_ 201 EngRunAtv 120;
BA_REL_ "GenSigSuprvResp" BU_SG_REL_ EOCM_F_HS SG_ 201 EngRunAtv 2;
BA_REL_ "GenSigTimeoutMsg" BU_SG_REL_ EOCM_F_HS SG_ 201 EngRunAtv 201;
BA_REL_ "GenSigTimeoutTime" BU_SG_REL_ EOCM_F_HS SG_ 201 EngRunAtv 120;
BA_REL_ "GenSigSuprvResp" BU_SG_REL_ FSCM_HS SG_ 201 EngRunAtv 1;
BA_REL_ "GenSigTimeoutMsg" BU_SG_REL_ FSCM_HS SG_ 201 EngRunAtv 201;
BA_REL_ "GenSigTimeoutTime" BU_SG_REL_ FSCM_HS SG_ 201 EngRunAtv 250;
BA_REL_ "GenSigSuprvResp" BU_SG_REL_ ICCM_OBD_HS SG_ 201 EngRunAtv 1;
BA_REL_ "GenSigTimeoutMsg" BU_SG_REL_ ICCM_OBD_HS SG_ 201 EngRunAtv 201;
BA_REL_ "GenSigTimeoutTime" BU_SG_REL_ ICCM_OBD_HS SG_ 201 EngRunAtv 250;
BA_REL_ "GenSigSuprvResp" BU_SG_REL_ ICCM_OBD_HS SG_ 201 EngRunAtv 1;
BA_REL_ "GenSigTimeoutMsg" BU_SG_REL_ ICCM_OBD_HS SG_ 201 EngRunAtv 201;
BA_REL_ "GenSigTimeoutTime" BU_SG_REL_ ICCM_OBD_HS SG_ 201 EngRunAtv 250;
BA_REL_ "GenSigSuprvResp" BU_SG_REL_ ICCM_HS SG_ 201 EngRunAtv 1;
BA_REL_ "GenSigTimeoutMsg" BU_SG_REL_ ICCM_HS SG_ 201 EngRunAtv 201;
BA_REL_ "GenSigTimeoutTime" BU_SG_REL_ ICCM_HS SG_ 201 EngRunAtv 250;
BA_REL_ "GenSigSuprvResp" BU_SG_REL_ ICCM_HS SG_ 201 EngRunAtv 1;
BA_REL_ "GenSigTimeoutMsg" BU_SG_REL_ ICCM_HS SG_ 201 EngRunAtv 201;
BA_REL_ "GenSigTimeoutTime" BU_SG_REL_ ICCM_HS SG_ 201 EngRunAtv 250;
BA_REL_ "GenSigSuprvResp" BU_SG_REL_ ALC_HS SG_ 201 EngRunAtv 1;
BA_REL_ "GenSigTimeoutMsg" BU_SG_REL_ ALC_HS SG_ 201 EngRunAtv 201;
BA_REL_ "GenSigTimeoutTime" BU_SG_REL_ ALC_HS SG_ 201 EngRunAtv 250;
BA_REL_ "GenSigSuprvResp" BU_SG_REL_ VES_HS SG_ 201 EngRunAtv 1;
BA_REL_ "GenSigTimeoutMsg" BU_SG_REL_ VES_HS SG_ 201 EngRunAtv 201;
BA_REL_ "GenSigTimeoutTime" BU_SG_REL_ VES_HS SG_ 201 EngRunAtv 250;
BA_REL_ "GenSigSuprvResp" BU_SG_REL_ EPS_HS SG_ 201 EngRunAtv 1;
BA_REL_ "GenSigTimeoutMsg" BU_SG_REL_ EPS_HS SG_ 201 EngRunAtv 201;
BA_REL_ "GenSigTimeoutTime" BU_SG_REL_ EPS_HS SG_ 201 EngRunAtv 250;
BA_REL_ "GenSigSuprvResp" BU_SG_REL_ AHL_AFL_HS SG_ 201 EngRunAtv 1;
BA_REL_ "GenSigTimeoutMsg" BU_SG_REL_ AHL_AFL_HS SG_ 201 EngRunAtv 201;
BA_REL_ "GenSigTimeoutTime" BU_SG_REL_ AHL_AFL_HS SG_ 201 EngRunAtv 250;
BA_REL_ "GenSigSuprvResp" BU_SG_REL_ SADS_HS SG_ 201 EngRunAtv 1;
BA_REL_ "GenSigTimeoutMsg" BU_SG_REL_ SADS_HS SG_ 201 EngRunAtv 201;
BA_REL_ "GenSigTimeoutTime" BU_SG_REL_ SADS_HS SG_ 201 EngRunAtv 250;
BA_REL_ "GenSigSuprvResp" BU_SG_REL_ SADS_HS SG_ 201 EngRunAtv 1;
BA_REL_ "GenSigTimeoutMsg" BU_SG_REL_ SADS_HS SG_ 201 EngRunAtv 201;
BA_REL_ "GenSigTimeoutTime" BU_SG_REL_ SADS_HS SG_ 201 EngRunAtv 250;
BA_REL_ "GenSigSuprvResp" BU_SG_REL_ BCM_HS SG_ 201 EngRunAtv 1;
BA_REL_ "GenSigTimeoutMsg" BU_SG_REL_ BCM_HS SG_ 201 EngRunAtv 201;
BA_REL_ "GenSigTimeoutTime" BU_SG_REL_ BCM_HS SG_ 201 EngRunAtv 250;
BA_REL_ "GenSigSuprvResp" BU_SG_REL_ BCM_HS SG_ 201 EngRunAtv 1;
BA_REL_ "GenSigTimeoutMsg" BU_SG_REL_ BCM_HS SG_ 201 EngRunAtv 201;
BA_REL_ "GenSigTimeoutTime" BU_SG_REL_ BCM_HS SG_ 201 EngRunAtv 250;
BA_REL_ "GenSigSuprvResp" BU_SG_REL_ BCM_HS SG_ 201 EngRunAtv 2;
BA_REL_ "GenSigTimeoutMsg" BU_SG_REL_ BCM_HS SG_ 201 EngRunAtv 201;
BA_REL_ "GenSigTimeoutTime" BU_SG_REL_ BCM_HS SG_ 201 EngRunAtv 50;
BA_REL_ "GenSigSuprvResp" BU_SG_REL_ TCCM_HS SG_ 201 EngRunAtv 1;
BA_REL_ "GenSigTimeoutMsg" BU_SG_REL_ TCCM_HS SG_ 201 EngRunAtv 201;
BA_REL_ "GenSigTimeoutTime" BU_SG_REL_ TCCM_HS SG_ 201 EngRunAtv 32;
BA_REL_ "GenSigSuprvResp" BU_SG_REL_ PTO_HS SG_ 201 EngIdlAtv 1;
BA_REL_ "GenSigTimeoutMsg" BU_SG_REL_ PTO_HS SG_ 201 EngIdlAtv 201;
BA_REL_ "GenSigTimeoutTime" BU_SG_REL_ PTO_HS SG_ 201 EngIdlAtv 250;
BA_REL_ "GenSigSuprvResp" BU_SG_REL_ AMP_HS SG_ 201 EngIdlAtv 1;
BA_REL_ "GenSigTimeoutMsg" BU_SG_REL_ AMP_HS SG_ 201 EngIdlAtv 201;
BA_REL_ "GenSigTimeoutTime" BU_SG_REL_ AMP_HS SG_ 201 EngIdlAtv 250;
BA_REL_ "GenSigSuprvResp" BU_SG_REL_ TCCM_HS SG_ 501 CltStartSwAtv 1;
BA_REL_ "GenSigTimeoutMsg" BU_SG_REL_ TCCM_HS SG_ 501 CltStartSwAtv 501;
BA_REL_ "GenSigTimeoutTime" BU_SG_REL_ TCCM_HS SG_ 501 CltStartSwAtv 250;
BA_REL_ "GenSigVBitResp" BU_SG_REL_ BCM_HS SG_ 501 CltStartSwAtv 1;
BA_REL_ "GenSigSuprvResp" BU_SG_REL_ BCM_HS SG_ 501 CltStartSwAtv 1;
BA_REL_ "GenSigTimeoutMsg" BU_SG_REL_ BCM_HS SG_ 501 CltStartSwAtv 501;
BA_REL_ "GenSigTimeoutTime" BU_SG_REL_ BCM_HS SG_ 501 CltStartSwAtv 250;
BA_REL_ "GenSigRxStartValue" BU_SG_REL_ RDCM_HS SG_ 501 CltStartSwAtv "True ($1)";
BA_REL_ "GenSigSuprvResp" BU_SG_REL_ TCCM_HS SG_ 501 CltchPdlActPos 1;
BA_REL_ "GenSigTimeoutMsg" BU_SG_REL_ TCCM_HS SG_ 501 CltchPdlActPos 501;
BA_REL_ "GenSigTimeoutTime" BU_SG_REL_ TCCM_HS SG_ 501 CltchPdlActPos 250;
BA_REL_ "GenSigSuprvResp" BU_SG_REL_ EBCM_OBD_HS SG_ 501 CltchPdlActPos 1;
BA_REL_ "GenSigTimeoutMsg" BU_SG_REL_ EBCM_OBD_HS SG_ 501 CltchPdlActPos 501;
BA_REL_ "GenSigTimeoutTime" BU_SG_REL_ EBCM_OBD_HS SG_ 501 CltchPdlActPos 250;
BA_REL_ "GenSigSuprvResp" BU_SG_REL_ EBCM_HS SG_ 501 CltchPdlActPos 1;
BA_REL_ "GenSigTimeoutMsg" BU_SG_REL_ EBCM_HS SG_ 501 CltchPdlActPos 501;
BA_REL_ "GenSigTimeoutTime" BU_SG_REL_ EBCM_HS SG_ 501 CltchPdlActPos 250;
BA_REL_ "GenSigSuprvResp" BU_SG_REL_ EPB_HS SG_ 501 CltchPdlActPos 1;
BA_REL_ "GenSigTimeoutMsg" BU_SG_REL_ EPB_HS SG_ 501 CltchPdlActPos 501;
BA_REL_ "GenSigTimeoutTime" BU_SG_REL_ EPB_HS SG_ 501 CltchPdlActPos 250;
BA_REL_ "GenSigSuprvResp" BU_SG_REL_ AHL_AFL_HS SG_ 501 TrnsEngdState 1;
BA_REL_ "GenSigTimeoutMsg" BU_SG_REL_ AHL_AFL_HS SG_ 501 TrnsEngdState 501;
BA_REL_ "GenSigTimeoutTime" BU_SG_REL_ AHL_AFL_HS SG_ 501 TrnsEngdState 250;
BA_REL_ "GenSigVBitResp" BU_SG_REL_ BCM_HS SG_ 501 TrnsEngdState 1;
BA_REL_ "GenSigSuprvResp" BU_SG_REL_ BCM_HS SG_ 501 TrnsEngdState 1;
BA_REL_ "GenSigTimeoutMsg" BU_SG_REL_ BCM_HS SG_ 501 TrnsEngdState 501;
BA_REL_ "GenSigTimeoutTime" BU_SG_REL_ BCM_HS SG_ 501 TrnsEngdState 250;
BA_REL_ "GenSigSuprvResp" BU_SG_REL_ EBCM_OBD_HS SG_ 501 TransTUDMdStat 1;
BA_REL_ "GenSigTimeoutMsg" BU_SG_REL_ EBCM_OBD_HS SG_ 501 TransTUDMdStat 501;
BA_REL_ "GenSigTimeoutTime" BU_SG_REL_ EBCM_OBD_HS SG_ 501 TransTUDMdStat 250;
BA_REL_ "GenSigSuprvResp" BU_SG_REL_ EBCM_HS SG_ 501 TransTUDMdStat 1;
BA_REL_ "GenSigTimeoutMsg" BU_SG_REL_ EBCM_HS SG_ 501 TransTUDMdStat 501;
BA_REL_ "GenSigTimeoutTime" BU_SG_REL_ EBCM_HS SG_ 501 TransTUDMdStat 250;
BA_REL_ "GenSigSuprvResp" BU_SG_REL_ EOCM_F_HS SG_ 501 TransTUDMdStat 1;
BA_REL_ "GenSigTimeoutTime" BU_SG_REL_ EOCM_F_HS SG_ 501 TransTUDMdStat 120;
BA_REL_ "GenSigSuprvResp" BU_SG_REL_ BCM_HS SG_ 501 TransTUDMdStat 1;
BA_REL_ "GenSigTimeoutMsg" BU_SG_REL_ BCM_HS SG_ 501 TransTUDMdStat 501;
BA_REL_ "GenSigTimeoutTime" BU_SG_REL_ BCM_HS SG_ 501 TransTUDMdStat 250;
BA_REL_ "GenSigSuprvResp" BU_SG_REL_ EBCM_OBD_HS SG_ 501 TrnsSftMdStat 1;
BA_REL_ "GenSigTimeoutMsg" BU_SG_REL_ EBCM_OBD_HS SG_ 501 TrnsSftMdStat 501;
BA_REL_ "GenSigTimeoutTime" BU_SG_REL_ EBCM_OBD_HS SG_ 501 TrnsSftMdStat 250;
BA_REL_ "GenSigSuprvResp" BU_SG_REL_ EBCM_HS SG_ 501 TrnsSftMdStat 1;
BA_REL_ "GenSigTimeoutMsg" BU_SG_REL_ EBCM_HS SG_ 501 TrnsSftMdStat 501;
BA_REL_ "GenSigTimeoutTime" BU_SG_REL_ EBCM_HS SG_ 501 TrnsSftMdStat 250;
BA_REL_ "GenSigSuprvResp" BU_SG_REL_ PTO_HS SG_ 501 TopTrvlCltchSwAct 1;
BA_REL_ "GenSigTimeoutMsg" BU_SG_REL_ PTO_HS SG_ 501 TopTrvlCltchSwAct 501;
BA_REL_ "GenSigTimeoutTime" BU_SG_REL_ PTO_HS SG_ 501 TopTrvlCltchSwAct 250;
BA_REL_ "GenSigVBitResp" BU_SG_REL_ BCM_HS SG_ 501 TopTrvlCltchSwAct 1;
BA_REL_ "GenSigSuprvResp" BU_SG_REL_ BCM_HS SG_ 501 TopTrvlCltchSwAct 1;
BA_REL_ "GenSigTimeoutMsg" BU_SG_REL_ BCM_HS SG_ 501 TopTrvlCltchSwAct 501;
BA_REL_ "GenSigTimeoutTime" BU_SG_REL_ BCM_HS SG_ 501 TopTrvlCltchSwAct 250;
BA_REL_ "GenSigSuprvResp" BU_SG_REL_ ACC_HS SG_ 501 TopTrvlCltchSwAct 1;
BA_REL_ "GenSigTimeoutMsg" BU_SG_REL_ ACC_HS SG_ 501 TopTrvlCltchSwAct 501;
BA_REL_ "GenSigTimeoutTime" BU_SG_REL_ ACC_HS SG_ 501 TopTrvlCltchSwAct 250;
BA_REL_ "GenSigSuprvResp" BU_SG_REL_ EPS_HS SG_ 501 TrnsShftLvrPos 1;
BA_REL_ "GenSigTimeoutMsg" BU_SG_REL_ EPS_HS SG_ 501 TrnsShftLvrPos 501;
BA_REL_ "GenSigTimeoutTime" BU_SG_REL_ EPS_HS SG_ 501 TrnsShftLvrPos 250;
BA_REL_ "GenSigSuprvResp" BU_SG_REL_ PTO_HS SG_ 501 TrnsShftLvrPos 1;
BA_REL_ "GenSigTimeoutMsg" BU_SG_REL_ PTO_HS SG_ 501 TrnsShftLvrPos 501;
BA_REL_ "GenSigTimeoutTime" BU_SG_REL_ PTO_HS SG_ 501 TrnsShftLvrPos 250;
BA_REL_ "GenSigSuprvResp" BU_SG_REL_ EOCM_F_HS SG_ 501 TrnsShftLvrPos 1;
BA_REL_ "GenSigTimeoutMsg" BU_SG_REL_ EOCM_F_HS SG_ 501 TrnsShftLvrPos 501;
BA_REL_ "GenSigTimeoutTime" BU_SG_REL_ EOCM_F_HS SG_ 501 TrnsShftLvrPos 120;
BA_REL_ "GenSigSuprvResp" BU_SG_REL_ VICM_HS SG_ 501 TrnsShftLvrPos 1;
BA_REL_ "GenSigTimeoutMsg" BU_SG_REL_ VICM_HS SG_ 501 TrnsShftLvrPos 501;
BA_REL_ "GenSigTimeoutTime" BU_SG_REL_ VICM_HS SG_ 501 TrnsShftLvrPos 250;
BA_REL_ "GenSigVBitResp" BU_SG_REL_ BCM_HS SG_ 501 TrnsShftLvrPos 1;
BA_REL_ "GenSigSuprvResp" BU_SG_REL_ BCM_HS SG_ 501 TrnsShftLvrPos 1;
BA_REL_ "GenSigTimeoutMsg" BU_SG_REL_ BCM_HS SG_ 501 TrnsShftLvrPos 501;
BA_REL_ "GenSigTimeoutTime" BU_SG_REL_ BCM_HS SG_ 501 TrnsShftLvrPos 250;
BA_REL_ "GenSigVBitResp" BU_SG_REL_ BCM_HS SG_ 501 TrnsShftLvrPos 1;
BA_REL_ "GenSigSuprvResp" BU_SG_REL_ BCM_HS SG_ 501 TrnsShftLvrPos 1;
BA_REL_ "GenSigTimeoutMsg" BU_SG_REL_ BCM_HS SG_ 501 TrnsShftLvrPos 501;
BA_REL_ "GenSigTimeoutTime" BU_SG_REL_ BCM_HS SG_ 501 TrnsShftLvrPos 250;
BA_REL_ "GenSigVBitResp" BU_SG_REL_ BCM_HS SG_ 501 TrnsShftLvrPos 1;
BA_REL_ "GenSigSuprvResp" BU_SG_REL_ BCM_HS SG_ 501 TrnsShftLvrPos 1;
BA_REL_ "GenSigTimeoutMsg" BU_SG_REL_ BCM_HS SG_ 501 TrnsShftLvrPos 501;
BA_REL_ "GenSigTimeoutTime" BU_SG_REL_ BCM_HS SG_ 501 TrnsShftLvrPos 250;
BA_REL_ "GenSigSuprvResp" BU_SG_REL_ EBCM_OBD_HS SG_ 501 TrnsShftLvrPos 1;
BA_REL_ "GenSigTimeoutMsg" BU_SG_REL_ EBCM_OBD_HS SG_ 501 TrnsShftLvrPos 501;
BA_REL_ "GenSigTimeoutTime" BU_SG_REL_ EBCM_OBD_HS SG_ 501 TrnsShftLvrPos 250;
BA_REL_ "GenSigSuprvResp" BU_SG_REL_ EBCM_HS SG_ 501 TrnsShftLvrPos 1;
BA_REL_ "GenSigTimeoutMsg" BU_SG_REL_ EBCM_HS SG_ 501 TrnsShftLvrPos 501;
BA_REL_ "GenSigTimeoutTime" BU_SG_REL_ EBCM_HS SG_ 501 TrnsShftLvrPos 250;
BA_REL_ "GenSigSuprvResp" BU_SG_REL_ PTO_HS SG_ 501 TrnsTrqCnvCltCmndMd 1;
BA_REL_ "GenSigTimeoutMsg" BU_SG_REL_ PTO_HS SG_ 501 TrnsTrqCnvCltCmndMd 501;
BA_REL_ "GenSigTimeoutTime" BU_SG_REL_ PTO_HS SG_ 501 TrnsTrqCnvCltCmndMd 250;
BA_REL_ "GenSigSuprvResp" BU_SG_REL_ PCM_HS SG_ 501 TrnsTrqCnvCltCmndMd 1;
BA_REL_ "GenSigTimeoutMsg" BU_SG_REL_ PCM_HS SG_ 501 TrnsTrqCnvCltCmndMd 501;
BA_REL_ "GenSigTimeoutTime" BU_SG_REL_ PCM_HS SG_ 501 TrnsTrqCnvCltCmndMd 62;
BA_REL_ "GenSigSuprvResp" BU_SG_REL_ ECM_HS SG_ 501 TrnsTrqCnvCltCmndMd 1;
BA_REL_ "GenSigTimeoutMsg" BU_SG_REL_ ECM_HS SG_ 501 TrnsTrqCnvCltCmndMd 501;
BA_REL_ "GenSigTimeoutTime" BU_SG_REL_ ECM_HS SG_ 501 TrnsTrqCnvCltCmndMd 62;
BA_REL_ "GenSigSuprvResp" BU_SG_REL_ EOCM_F_HS SG_ 501 AutoTransComndGear 1;
BA_REL_ "GenSigTimeoutTime" BU_SG_REL_ EOCM_F_HS SG_ 501 AutoTransComndGear 120;
BA_REL_ "GenSigRxStartValue" BU_SG_REL_ RDCM_HS SG_ 501 AutoTransComndGear "$F-Park Gear";
BA_REL_ "GenSigSuprvResp" BU_SG_REL_ ACC_HS SG_ 501 AutoTransComndGear 1;
BA_REL_ "GenSigTimeoutMsg" BU_SG_REL_ ACC_HS SG_ 501 AutoTransComndGear 501;
BA_REL_ "GenSigTimeoutTime" BU_SG_REL_ ACC_HS SG_ 501 AutoTransComndGear 250;
BA_REL_ "GenSigSuprvResp" BU_SG_REL_ BCM_HS SG_ 501 AutoTransComndGear 1;
BA_REL_ "GenSigTimeoutMsg" BU_SG_REL_ BCM_HS SG_ 501 AutoTransComndGear 501;
BA_REL_ "GenSigTimeoutTime" BU_SG_REL_ BCM_HS SG_ 501 AutoTransComndGear 250;
BA_REL_ "GenSigSuprvResp" BU_SG_REL_ PCM_HS SG_ 501 AutoTransComndGear 1;
BA_REL_ "GenSigTimeoutMsg" BU_SG_REL_ PCM_HS SG_ 501 AutoTransComndGear 501;
BA_REL_ "GenSigTimeoutTime" BU_SG_REL_ PCM_HS SG_ 501 AutoTransComndGear 62;
BA_REL_ "GenSigSuprvResp" BU_SG_REL_ ECM_HS SG_ 501 AutoTransComndGear 1;
BA_REL_ "GenSigTimeoutMsg" BU_SG_REL_ ECM_HS SG_ 501 AutoTransComndGear 501;
BA_REL_ "GenSigTimeoutTime" BU_SG_REL_ ECM_HS SG_ 501 AutoTransComndGear 62;
BA_REL_ "GenSigSuprvResp" BU_SG_REL_ ICCM_OBD_HS SG_ 501 AutoTransGrSftDirect 1;
BA_REL_ "GenSigTimeoutMsg" BU_SG_REL_ ICCM_OBD_HS SG_ 501 AutoTransGrSftDirect 501;
BA_REL_ "GenSigTimeoutTime" BU_SG_REL_ ICCM_OBD_HS SG_ 501 AutoTransGrSftDirect 250;
BA_REL_ "GenSigSuprvResp" BU_SG_REL_ ICCM_HS SG_ 501 AutoTransGrSftDirect 1;
BA_REL_ "GenSigTimeoutMsg" BU_SG_REL_ ICCM_HS SG_ 501 AutoTransGrSftDirect 501;
BA_REL_ "GenSigTimeoutTime" BU_SG_REL_ ICCM_HS SG_ 501 AutoTransGrSftDirect 250;
BA_REL_ "GenSigSuprvResp" BU_SG_REL_ EOCM_F_HS SG_ 501 AutoTransGrSftDirect 1;
BA_REL_ "GenSigTimeoutMsg" BU_SG_REL_ EOCM_F_HS SG_ 501 AutoTransGrSftDirect 501;
BA_REL_ "GenSigTimeoutTime" BU_SG_REL_ EOCM_F_HS SG_ 501 AutoTransGrSftDirect 120;
BA_REL_ "GenSigSuprvResp" BU_SG_REL_ EOCM_F_HS SG_ 501 AutoTransGrSftDirect 1;
BA_REL_ "GenSigTimeoutMsg" BU_SG_REL_ EOCM_F_HS SG_ 501 AutoTransGrSftDirect 501;
BA_REL_ "GenSigTimeoutTime" BU_SG_REL_ EOCM_F_HS SG_ 501 AutoTransGrSftDirect 120;
BA_REL_ "GenSigSuprvResp" BU_SG_REL_ ACC_HS SG_ 501 AutoTransGrSftDirect 1;
BA_REL_ "GenSigTimeoutMsg" BU_SG_REL_ ACC_HS SG_ 501 AutoTransGrSftDirect 501;
BA_REL_ "GenSigTimeoutTime" BU_SG_REL_ ACC_HS SG_ 501 AutoTransGrSftDirect 120;
BA_REL_ "GenSigSuprvResp" BU_SG_REL_ PFAF_HS SG_ 501 TransEstGear 1;
BA_REL_ "GenSigTimeoutMsg" BU_SG_REL_ PFAF_HS SG_ 501 TransEstGear 501;
BA_REL_ "GenSigTimeoutTime" BU_SG_REL_ PFAF_HS SG_ 501 TransEstGear 250;
BA_REL_ "GenSigSuprvResp" BU_SG_REL_ PTO_HS SG_ 501 TransEstGear 1;
BA_REL_ "GenSigTimeoutMsg" BU_SG_REL_ PTO_HS SG_ 501 TransEstGear 501;
BA_REL_ "GenSigTimeoutTime" BU_SG_REL_ PTO_HS SG_ 501 TransEstGear 250;
BA_REL_ "GenSigSuprvResp" BU_SG_REL_ HMIM_HS SG_ 501 TransEstGear 1;
BA_REL_ "GenSigTimeoutMsg" BU_SG_REL_ HMIM_HS SG_ 501 TransEstGear 501;
BA_REL_ "GenSigTimeoutTime" BU_SG_REL_ HMIM_HS SG_ 501 TransEstGear 250;
BA_REL_ "GenSigSuprvRespSubValue" BU_SG_REL_ EOCM_F_HS SG_ 501 TransEstGear 15;
BA_REL_ "GenSigSuprvResp" BU_SG_REL_ EOCM_F_HS SG_ 501 TransEstGear 2;
BA_REL_ "GenSigTimeoutMsg" BU_SG_REL_ EOCM_F_HS SG_ 501 TransEstGear 501;
BA_REL_ "GenSigTimeoutTime" BU_SG_REL_ EOCM_F_HS SG_ 501 TransEstGear 120;
BA_REL_ "GenSigVBitResp" BU_SG_REL_ FCP_HS SG_ 501 TransEstGear 1;
BA_REL_ "GenSigSuprvResp" BU_SG_REL_ FCP_HS SG_ 501 TransEstGear 1;
BA_REL_ "GenSigTimeoutMsg" BU_SG_REL_ FCP_HS SG_ 501 TransEstGear 501;
BA_REL_ "GenSigTimeoutTime" BU_SG_REL_ FCP_HS SG_ 501 TransEstGear 250;
BA_REL_ "GenSigVBitResp" BU_SG_REL_ ONSTAR_HS SG_ 501 TransEstGear 1;
BA_REL_ "GenSigSuprvResp" BU_SG_REL_ ONSTAR_HS SG_ 501 TransEstGear 1;
BA_REL_ "GenSigTimeoutMsg" BU_SG_REL_ ONSTAR_HS SG_ 501 TransEstGear 501;
BA_REL_ "GenSigTimeoutTime" BU_SG_REL_ ONSTAR_HS SG_ 501 TransEstGear 250;
BA_REL_ "GenSigRxStartValue" BU_SG_REL_ RDCM_HS SG_ 501 TransEstGear "$F-Park Gear";
BA_REL_ "GenSigSuprvResp" BU_SG_REL_ RDCM_HS SG_ 501 TransEstGear 1;
BA_REL_ "GenSigTimeoutMsg" BU_SG_REL_ RDCM_HS SG_ 501 TransEstGear 501;
BA_REL_ "GenSigTimeoutTime" BU_SG_REL_ RDCM_HS SG_ 501 TransEstGear 250;
BA_REL_ "GenSigSuprvResp" BU_SG_REL_ ACC_HS SG_ 501 TransEstGear 1;
BA_REL_ "GenSigTimeoutMsg" BU_SG_REL_ ACC_HS SG_ 501 TransEstGear 501;
BA_REL_ "GenSigTimeoutTime" BU_SG_REL_ ACC_HS SG_ 501 TransEstGear 250;
BA_REL_ "GenSigVBitResp" BU_SG_REL_ BCM_HS SG_ 501 TransEstGear 1;
BA_REL_ "GenSigSuprvResp" BU_SG_REL_ BCM_HS SG_ 501 TransEstGear 1;
BA_REL_ "GenSigTimeoutMsg" BU_SG_REL_ BCM_HS SG_ 501 TransEstGear 501;
BA_REL_ "GenSigTimeoutTime" BU_SG_REL_ BCM_HS SG_ 501 TransEstGear 250;
BA_REL_ "GenSigVBitResp" BU_SG_REL_ BCM_HS SG_ 501 TransEstGear 1;
BA_REL_ "GenSigSuprvResp" BU_SG_REL_ BCM_HS SG_ 501 TransEstGear 1;
BA_REL_ "GenSigTimeoutMsg" BU_SG_REL_ BCM_HS SG_ 501 TransEstGear 501;
BA_REL_ "GenSigTimeoutTime" BU_SG_REL_ BCM_HS SG_ 501 TransEstGear 250;
BA_REL_ "GenSigVBitResp" BU_SG_REL_ BCM_HS SG_ 501 TransEstGear 1;
BA_REL_ "GenSigSuprvResp" BU_SG_REL_ BCM_HS SG_ 501 TransEstGear 1;
BA_REL_ "GenSigTimeoutMsg" BU_SG_REL_ BCM_HS SG_ 501 TransEstGear 501;
BA_REL_ "GenSigTimeoutTime" BU_SG_REL_ BCM_HS SG_ 501 TransEstGear 250;
BA_REL_ "GenSigSuprvResp" BU_SG_REL_ TCCM_HS SG_ 501 TransEstGear 1;
BA_REL_ "GenSigTimeoutMsg" BU_SG_REL_ TCCM_HS SG_ 501 TransEstGear 501;
BA_REL_ "GenSigTimeoutTime" BU_SG_REL_ TCCM_HS SG_ 501 TransEstGear 63;
BA_REL_ "GenSigSuprvResp" BU_SG_REL_ BCM_HS SG_ 1225 TCTPIR_TnsEsClCDwT 1;
BA_REL_ "GenSigTimeoutMsg" BU_SG_REL_ BCM_HS SG_ 1225 TCTPIR_TnsEsClCDwT 1225;
BA_REL_ "GenSigTimeoutTime" BU_SG_REL_ BCM_HS SG_ 1225 TCTPIR_TnsEsClCDwT 1250;
BA_REL_ "GenSigSuprvResp" BU_SG_REL_ BCM_HS SG_ 1225 TCTPIR_TnsEsClTmpD 1;
BA_REL_ "GenSigTimeoutMsg" BU_SG_REL_ BCM_HS SG_ 1225 TCTPIR_TnsEsClTmpD 1225;
BA_REL_ "GenSigTimeoutTime" BU_SG_REL_ BCM_HS SG_ 1225 TCTPIR_TnsEsClTmpD 1250;
BA_REL_ "GenSigSuprvResp" BU_SG_REL_ BCM_HS SG_ 1225 TCTPIR_DrvNotfn 1;
BA_REL_ "GenSigTimeoutMsg" BU_SG_REL_ BCM_HS SG_ 1225 TCTPIR_DrvNotfn 1225;
BA_REL_ "GenSigTimeoutTime" BU_SG_REL_ BCM_HS SG_ 1225 TCTPIR_DrvNotfn 1250;
BA_REL_ "GenSigSuprvResp" BU_SG_REL_ BCM_HS SG_ 1225 GrdBrkgAct 1;
BA_REL_ "GenSigTimeoutMsg" BU_SG_REL_ BCM_HS SG_ 1225 GrdBrkgAct 1225;
BA_REL_ "GenSigTimeoutTime" BU_SG_REL_ BCM_HS SG_ 1225 GrdBrkgAct 1250;
BA_REL_ "GenSigSuprvResp" BU_SG_REL_ ICCM_OBD_HS SG_ 1225 RrPTCoolFanRatFltStat 1;
BA_REL_ "GenSigTimeoutMsg" BU_SG_REL_ ICCM_OBD_HS SG_ 1225 RrPTCoolFanRatFltStat 1225;
BA_REL_ "GenSigTimeoutTime" BU_SG_REL_ ICCM_OBD_HS SG_ 1225 RrPTCoolFanRatFltStat 1250;
BA_REL_ "GenSigSuprvResp" BU_SG_REL_ ICCM_HS SG_ 1225 RrPTCoolFanRatFltStat 1;
BA_REL_ "GenSigTimeoutMsg" BU_SG_REL_ ICCM_HS SG_ 1225 RrPTCoolFanRatFltStat 1225;
BA_REL_ "GenSigTimeoutTime" BU_SG_REL_ ICCM_HS SG_ 1225 RrPTCoolFanRatFltStat 1250;
BA_REL_ "GenSigSuprvResp" BU_SG_REL_ PTO_HS SG_ 1225 TrnsThrmlMngmntStat 1;
BA_REL_ "GenSigTimeoutMsg" BU_SG_REL_ PTO_HS SG_ 1225 TrnsThrmlMngmntStat 1225;
BA_REL_ "GenSigTimeoutTime" BU_SG_REL_ PTO_HS SG_ 1225 TrnsThrmlMngmntStat 1250;
BA_REL_ "GenSigVBitResp" BU_SG_REL_ VCM_HS SG_ 1225 TrnOilTmp 1;
BA_REL_ "GenSigSuprvResp" BU_SG_REL_ VCM_HS SG_ 1225 TrnOilTmp 1;
BA_REL_ "GenSigTimeoutMsg" BU_SG_REL_ VCM_HS SG_ 1225 TrnOilTmp 1225;
BA_REL_ "GenSigTimeoutTime" BU_SG_REL_ VCM_HS SG_ 1225 TrnOilTmp 1250;
BA_REL_ "GenSigSuprvResp" BU_SG_REL_ VICM2_HS SG_ 1225 TrnOilTmp 1;
BA_REL_ "GenSigTimeoutMsg" BU_SG_REL_ VICM2_HS SG_ 1225 TrnOilTmp 1225;
BA_REL_ "GenSigTimeoutTime" BU_SG_REL_ VICM2_HS SG_ 1225 TrnOilTmp 1250;
BA_REL_ "GenSigSuprvResp" BU_SG_REL_ VICM_HS SG_ 1225 TrnOilTmp 1;
BA_REL_ "GenSigTimeoutMsg" BU_SG_REL_ VICM_HS SG_ 1225 TrnOilTmp 1225;
BA_REL_ "GenSigTimeoutTime" BU_SG_REL_ VICM_HS SG_ 1225 TrnOilTmp 1250;
BA_REL_ "GenSigSuprvResp" BU_SG_REL_ TCCM_HS SG_ 1225 TrnOilTmp 1;
BA_REL_ "GenSigTimeoutMsg" BU_SG_REL_ TCCM_HS SG_ 1225 TrnOilTmp 1225;
BA_REL_ "GenSigTimeoutTime" BU_SG_REL_ TCCM_HS SG_ 1225 TrnOilTmp 1250;
BA_REL_ "GenSigVBitResp" BU_SG_REL_ BCM_HS SG_ 1225 TrnOilTmp 1;
BA_REL_ "GenSigSuprvResp" BU_SG_REL_ BCM_HS SG_ 1225 TrnOilTmp 1;
BA_REL_ "GenSigTimeoutMsg" BU_SG_REL_ BCM_HS SG_ 1225 TrnOilTmp 1225;
BA_REL_ "GenSigTimeoutTime" BU_SG_REL_ BCM_HS SG_ 1225 TrnOilTmp 1250;
BA_REL_ "GenSigSuprvResp" BU_SG_REL_ PCM_HS SG_ 409 TTRLT_TorqReqVal 1;
BA_REL_ "GenSigTimeoutMsg" BU_SG_REL_ PCM_HS SG_ 409 TTRLT_TorqReqVal 409;
BA_REL_ "GenSigTimeoutTime" BU_SG_REL_ PCM_HS SG_ 409 TTRLT_TorqReqVal 31;
BA_REL_ "GenSigSuprvResp" BU_SG_REL_ ECM_HS SG_ 409 TTRLT_TorqReqVal 1;
BA_REL_ "GenSigTimeoutMsg" BU_SG_REL_ ECM_HS SG_ 409 TTRLT_TorqReqVal 409;
BA_REL_ "GenSigTimeoutTime" BU_SG_REL_ ECM_HS SG_ 409 TTRLT_TorqReqVal 31;
BA_REL_ "GenSigSuprvResp" BU_SG_REL_ PCM_HS SG_ 409 TTRLT_TqRdnRlznSgg 1;
BA_REL_ "GenSigTimeoutMsg" BU_SG_REL_ PCM_HS SG_ 409 TTRLT_TqRdnRlznSgg 409;
BA_REL_ "GenSigTimeoutTime" BU_SG_REL_ PCM_HS SG_ 409 TTRLT_TqRdnRlznSgg 31;
BA_REL_ "GenSigSuprvResp" BU_SG_REL_ ECM_HS SG_ 409 TTRLT_TqRdnRlznSgg 1;
BA_REL_ "GenSigTimeoutMsg" BU_SG_REL_ ECM_HS SG_ 409 TTRLT_TqRdnRlznSgg 409;
BA_REL_ "GenSigTimeoutTime" BU_SG_REL_ ECM_HS SG_ 409 TTRLT_TqRdnRlznSgg 31;
BA_REL_ "GenSigSuprvResp" BU_SG_REL_ PCM_HS SG_ 409 TTRLT_TorqInvntnTyp 1;
BA_REL_ "GenSigTimeoutMsg" BU_SG_REL_ PCM_HS SG_ 409 TTRLT_TorqInvntnTyp 409;
BA_REL_ "GenSigTimeoutTime" BU_SG_REL_ PCM_HS SG_ 409 TTRLT_TorqInvntnTyp 31;
BA_REL_ "GenSigSuprvResp" BU_SG_REL_ ECM_HS SG_ 409 TTRLT_TorqInvntnTyp 1;
BA_REL_ "GenSigTimeoutMsg" BU_SG_REL_ ECM_HS SG_ 409 TTRLT_TorqInvntnTyp 409;
BA_REL_ "GenSigTimeoutTime" BU_SG_REL_ ECM_HS SG_ 409 TTRLT_TorqInvntnTyp 31;
BA_REL_ "GenSigSuprvResp" BU_SG_REL_ PCM_HS SG_ 409 TTRST_TorqReqVal 1;
BA_REL_ "GenSigTimeoutMsg" BU_SG_REL_ PCM_HS SG_ 409 TTRST_TorqReqVal 409;
BA_REL_ "GenSigTimeoutTime" BU_SG_REL_ PCM_HS SG_ 409 TTRST_TorqReqVal 31;
BA_REL_ "GenSigSuprvResp" BU_SG_REL_ ECM_HS SG_ 409 TTRST_TorqReqVal 1;
BA_REL_ "GenSigTimeoutMsg" BU_SG_REL_ ECM_HS SG_ 409 TTRST_TorqReqVal 409;
BA_REL_ "GenSigTimeoutTime" BU_SG_REL_ ECM_HS SG_ 409 TTRST_TorqReqVal 31;
BA_REL_ "GenSigSuprvResp" BU_SG_REL_ PCM_HS SG_ 409 TTRST_TorqInvntnTyp 1;
BA_REL_ "GenSigTimeoutMsg" BU_SG_REL_ PCM_HS SG_ 409 TTRST_TorqInvntnTyp 409;
BA_REL_ "GenSigTimeoutTime" BU_SG_REL_ PCM_HS SG_ 409 TTRST_TorqInvntnTyp 31;
BA_REL_ "GenSigSuprvResp" BU_SG_REL_ ECM_HS SG_ 409 TTRST_TorqInvntnTyp 1;
BA_REL_ "GenSigTimeoutMsg" BU_SG_REL_ ECM_HS SG_ 409 TTRST_TorqInvntnTyp 409;
BA_REL_ "GenSigTimeoutTime" BU_SG_REL_ ECM_HS SG_ 409 TTRST_TorqInvntnTyp 31;
BA_REL_ "GenSigSuprvResp" BU_SG_REL_ PCM_HS SG_ 413 TrnsRtoCntlSysFlt 1;
BA_REL_ "GenSigTimeoutMsg" BU_SG_REL_ PCM_HS SG_ 413 TrnsRtoCntlSysFlt 413;
BA_REL_ "GenSigTimeoutTime" BU_SG_REL_ PCM_HS SG_ 413 TrnsRtoCntlSysFlt 62;
BA_REL_ "GenSigSuprvResp" BU_SG_REL_ ECM_HS SG_ 413 TrnsRtoCntlSysFlt 1;
BA_REL_ "GenSigTimeoutMsg" BU_SG_REL_ ECM_HS SG_ 413 TrnsRtoCntlSysFlt 413;
BA_REL_ "GenSigTimeoutTime" BU_SG_REL_ ECM_HS SG_ 413 TrnsRtoCntlSysFlt 62;
BA_REL_ "GenSigSuprvResp" BU_SG_REL_ EOCM_F_HS SG_ 413 TrnGrRat 1;
BA_REL_ "GenSigTimeoutMsg" BU_SG_REL_ EOCM_F_HS SG_ 413 TrnGrRat 413;
BA_REL_ "GenSigTimeoutTime" BU_SG_REL_ EOCM_F_HS SG_ 413 TrnGrRat 120;
BA_REL_ "GenSigSuprvResp" BU_SG_REL_ EOCM_F_HS SG_ 413 TrnGrRat 1;
BA_REL_ "GenSigTimeoutMsg" BU_SG_REL_ EOCM_F_HS SG_ 413 TrnGrRat 413;
BA_REL_ "GenSigTimeoutTime" BU_SG_REL_ EOCM_F_HS SG_ 413 TrnGrRat 120;
BA_REL_ "GenSigSuprvResp" BU_SG_REL_ PCM_HS SG_ 413 TESR_EngSpdCntlRsp 1;
BA_REL_ "GenSigTimeoutMsg" BU_SG_REL_ PCM_HS SG_ 413 TESR_EngSpdCntlRsp 413;
BA_REL_ "GenSigTimeoutTime" BU_SG_REL_ PCM_HS SG_ 413 TESR_EngSpdCntlRsp 62;
BA_REL_ "GenSigSuprvResp" BU_SG_REL_ ECM_HS SG_ 413 TESR_EngSpdCntlRsp 1;
BA_REL_ "GenSigTimeoutMsg" BU_SG_REL_ ECM_HS SG_ 413 TESR_EngSpdCntlRsp 413;
BA_REL_ "GenSigTimeoutTime" BU_SG_REL_ ECM_HS SG_ 413 TESR_EngSpdCntlRsp 62;
BA_REL_ "GenSigSuprvResp" BU_SG_REL_ PCM_HS SG_ 413 TESR_EngSpdRqVal 1;
BA_REL_ "GenSigTimeoutMsg" BU_SG_REL_ PCM_HS SG_ 413 TESR_EngSpdRqVal 413;
BA_REL_ "GenSigTimeoutTime" BU_SG_REL_ PCM_HS SG_ 413 TESR_EngSpdRqVal 62;
BA_REL_ "GenSigSuprvResp" BU_SG_REL_ ECM_HS SG_ 413 TESR_EngSpdRqVal 1;
BA_REL_ "GenSigTimeoutMsg" BU_SG_REL_ ECM_HS SG_ 413 TESR_EngSpdRqVal 413;
BA_REL_ "GenSigTimeoutTime" BU_SG_REL_ ECM_HS SG_ 413 TESR_EngSpdRqVal 62;
BA_REL_ "GenSigSuprvResp" BU_SG_REL_ PCM_HS SG_ 413 TESR_EngSpdIntTyp 1;
BA_REL_ "GenSigTimeoutMsg" BU_SG_REL_ PCM_HS SG_ 413 TESR_EngSpdIntTyp 413;
BA_REL_ "GenSigTimeoutTime" BU_SG_REL_ PCM_HS SG_ 413 TESR_EngSpdIntTyp 62;
BA_REL_ "GenSigSuprvResp" BU_SG_REL_ ECM_HS SG_ 413 TESR_EngSpdIntTyp 1;
BA_REL_ "GenSigTimeoutMsg" BU_SG_REL_ ECM_HS SG_ 413 TESR_EngSpdIntTyp 413;
BA_REL_ "GenSigTimeoutTime" BU_SG_REL_ ECM_HS SG_ 413 TESR_EngSpdIntTyp 62;
BA_REL_ "GenSigSuprvResp" BU_SG_REL_ PCM_HS SG_ 413 TrnsGrgShftAct 1;
BA_REL_ "GenSigTimeoutMsg" BU_SG_REL_ PCM_HS SG_ 413 TrnsGrgShftAct 413;
BA_REL_ "GenSigTimeoutTime" BU_SG_REL_ PCM_HS SG_ 413 TrnsGrgShftAct 62;
BA_REL_ "GenSigSuprvResp" BU_SG_REL_ ECM_HS SG_ 413 TrnsGrgShftAct 1;
BA_REL_ "GenSigTimeoutMsg" BU_SG_REL_ ECM_HS SG_ 413 TrnsGrgShftAct 413;
BA_REL_ "GenSigTimeoutTime" BU_SG_REL_ ECM_HS SG_ 413 TrnsGrgShftAct 62;
BA_REL_ "GenSigSuprvResp" BU_SG_REL_ PTO_HS SG_ 197 WRSLNDWhlDisTpRC 1;
BA_REL_ "GenSigTimeoutMsg" BU_SG_REL_ PTO_HS SG_ 197 WRSLNDWhlDisTpRC 197;
BA_REL_ "GenSigTimeoutTime" BU_SG_REL_ PTO_HS SG_ 197 WRSLNDWhlDisTpRC 250;
BA_REL_ "GenSigSuprvResp" BU_SG_REL_ HCP_HS SG_ 197 WRSLNDWhlDisTpRC 1;
BA_REL_ "GenSigTimeoutMsg" BU_SG_REL_ HCP_HS SG_ 197 WRSLNDWhlDisTpRC 197;
BA_REL_ "GenSigTimeoutTime" BU_SG_REL_ HCP_HS SG_ 197 WRSLNDWhlDisTpRC 250;
BA_REL_ "GenSigSuprvResp" BU_SG_REL_ HMIM_HS SG_ 197 WRSLNDWhlDisTpRC 1;
BA_REL_ "GenSigTimeoutMsg" BU_SG_REL_ HMIM_HS SG_ 197 WRSLNDWhlDisTpRC 197;
BA_REL_ "GenSigTimeoutTime" BU_SG_REL_ HMIM_HS SG_ 197 WRSLNDWhlDisTpRC 250;
BA_REL_ "GenSigSuprvResp" BU_SG_REL_ RDCM_HS SG_ 197 WRSLNDWhlDisTpRC 1;
BA_REL_ "GenSigTimeoutMsg" BU_SG_REL_ RDCM_HS SG_ 197 WRSLNDWhlDisTpRC 197;
BA_REL_ "GenSigTimeoutTime" BU_SG_REL_ RDCM_HS SG_ 197 WRSLNDWhlDisTpRC 250;
BA_REL_ "GenSigSuprvResp" BU_SG_REL_ BCM_HS SG_ 197 WRSLNDWhlDisTpRC 1;
BA_REL_ "GenSigTimeoutMsg" BU_SG_REL_ BCM_HS SG_ 197 WRSLNDWhlDisTpRC 197;
BA_REL_ "GenSigTimeoutTime" BU_SG_REL_ BCM_HS SG_ 197 WRSLNDWhlDisTpRC 250;
BA_REL_ "GenSigSuprvResp" BU_SG_REL_ TCCM_HS SG_ 197 WRSLNDWhlDisTpRC 1;
BA_REL_ "GenSigTimeoutMsg" BU_SG_REL_ TCCM_HS SG_ 197 WRSLNDWhlDisTpRC 197;
BA_REL_ "GenSigTimeoutTime" BU_SG_REL_ TCCM_HS SG_ 197 WRSLNDWhlDisTpRC 25;
BA_REL_ "GenSigSuprvResp" BU_SG_REL_ PTO_HS SG_ 197 WRSLNDWhlRotStRst 1;
BA_REL_ "GenSigTimeoutMsg" BU_SG_REL_ PTO_HS SG_ 197 WRSLNDWhlRotStRst 197;
BA_REL_ "GenSigTimeoutTime" BU_SG_REL_ PTO_HS SG_ 197 WRSLNDWhlRotStRst 250;
BA_REL_ "GenSigSuprvResp" BU_SG_REL_ HCP_HS SG_ 197 WRSLNDWhlRotStRst 1;
BA_REL_ "GenSigTimeoutMsg" BU_SG_REL_ HCP_HS SG_ 197 WRSLNDWhlRotStRst 197;
BA_REL_ "GenSigTimeoutTime" BU_SG_REL_ HCP_HS SG_ 197 WRSLNDWhlRotStRst 250;
BA_REL_ "GenSigSuprvResp" BU_SG_REL_ HMIM_HS SG_ 197 WRSLNDWhlRotStRst 1;
BA_REL_ "GenSigTimeoutMsg" BU_SG_REL_ HMIM_HS SG_ 197 WRSLNDWhlRotStRst 197;
BA_REL_ "GenSigTimeoutTime" BU_SG_REL_ HMIM_HS SG_ 197 WRSLNDWhlRotStRst 250;
BA_REL_ "GenSigSuprvResp" BU_SG_REL_ RDCM_HS SG_ 197 WRSLNDWhlRotStRst 1;
BA_REL_ "GenSigTimeoutMsg" BU_SG_REL_ RDCM_HS SG_ 197 WRSLNDWhlRotStRst 197;
BA_REL_ "GenSigTimeoutTime" BU_SG_REL_ RDCM_HS SG_ 197 WRSLNDWhlRotStRst 250;
BA_REL_ "GenSigSuprvResp" BU_SG_REL_ BCM_HS SG_ 197 WRSLNDWhlRotStRst 1;
BA_REL_ "GenSigTimeoutMsg" BU_SG_REL_ BCM_HS SG_ 197 WRSLNDWhlRotStRst 197;
BA_REL_ "GenSigTimeoutTime" BU_SG_REL_ BCM_HS SG_ 197 WRSLNDWhlRotStRst 250;
BA_REL_ "GenSigSuprvResp" BU_SG_REL_ TCCM_HS SG_ 197 WRSLNDWhlRotStRst 1;
BA_REL_ "GenSigTimeoutMsg" BU_SG_REL_ TCCM_HS SG_ 197 WRSLNDWhlRotStRst 197;
BA_REL_ "GenSigTimeoutTime" BU_SG_REL_ TCCM_HS SG_ 197 WRSLNDWhlRotStRst 25;
BA_REL_ "GenSigSuprvResp" BU_SG_REL_ PTO_HS SG_ 197 WRSLNDWhlDistVal 1;
BA_REL_ "GenSigTimeoutMsg" BU_SG_REL_ PTO_HS SG_ 197 WRSLNDWhlDistVal 197;
BA_REL_ "GenSigTimeoutTime" BU_SG_REL_ PTO_HS SG_ 197 WRSLNDWhlDistVal 250;
BA_REL_ "GenSigSuprvResp" BU_SG_REL_ HCP_HS SG_ 197 WRSLNDWhlDistVal 1;
BA_REL_ "GenSigTimeoutMsg" BU_SG_REL_ HCP_HS SG_ 197 WRSLNDWhlDistVal 197;
BA_REL_ "GenSigTimeoutTime" BU_SG_REL_ HCP_HS SG_ 197 WRSLNDWhlDistVal 250;
BA_REL_ "GenSigSuprvResp" BU_SG_REL_ HMIM_HS SG_ 197 WRSLNDWhlDistVal 1;
BA_REL_ "GenSigTimeoutMsg" BU_SG_REL_ HMIM_HS SG_ 197 WRSLNDWhlDistVal 197;
BA_REL_ "GenSigTimeoutTime" BU_SG_REL_ HMIM_HS SG_ 197 WRSLNDWhlDistVal 250;
BA_REL_ "GenSigSuprvResp" BU_SG_REL_ RDCM_HS SG_ 197 WRSLNDWhlDistVal 1;
BA_REL_ "GenSigTimeoutMsg" BU_SG_REL_ RDCM_HS SG_ 197 WRSLNDWhlDistVal 197;
BA_REL_ "GenSigTimeoutTime" BU_SG_REL_ RDCM_HS SG_ 197 WRSLNDWhlDistVal 250;
BA_REL_ "GenSigSuprvResp" BU_SG_REL_ BCM_HS SG_ 197 WRSLNDWhlDistVal 1;
BA_REL_ "GenSigTimeoutMsg" BU_SG_REL_ BCM_HS SG_ 197 WRSLNDWhlDistVal 197;
BA_REL_ "GenSigTimeoutTime" BU_SG_REL_ BCM_HS SG_ 197 WRSLNDWhlDistVal 250;
BA_REL_ "GenSigSuprvResp" BU_SG_REL_ TCCM_HS SG_ 197 WRSLNDWhlDistVal 1;
BA_REL_ "GenSigTimeoutMsg" BU_SG_REL_ TCCM_HS SG_ 197 WRSLNDWhlDistVal 197;
BA_REL_ "GenSigTimeoutTime" BU_SG_REL_ TCCM_HS SG_ 197 WRSLNDWhlDistVal 25;
BA_REL_ "GenSigSuprvResp" BU_SG_REL_ PTO_HS SG_ 197 WRSLNDWhlDistTstm 1;
BA_REL_ "GenSigTimeoutMsg" BU_SG_REL_ PTO_HS SG_ 197 WRSLNDWhlDistTstm 197;
BA_REL_ "GenSigTimeoutTime" BU_SG_REL_ PTO_HS SG_ 197 WRSLNDWhlDistTstm 250;
BA_REL_ "GenSigSuprvResp" BU_SG_REL_ HCP_HS SG_ 197 WRSLNDWhlDistTstm 1;
BA_REL_ "GenSigTimeoutMsg" BU_SG_REL_ HCP_HS SG_ 197 WRSLNDWhlDistTstm 197;
BA_REL_ "GenSigTimeoutTime" BU_SG_REL_ HCP_HS SG_ 197 WRSLNDWhlDistTstm 250;
BA_REL_ "GenSigSuprvResp" BU_SG_REL_ HMIM_HS SG_ 197 WRSLNDWhlDistTstm 1;
BA_REL_ "GenSigTimeoutMsg" BU_SG_REL_ HMIM_HS SG_ 197 WRSLNDWhlDistTstm 197;
BA_REL_ "GenSigTimeoutTime" BU_SG_REL_ HMIM_HS SG_ 197 WRSLNDWhlDistTstm 250;
BA_REL_ "GenSigSuprvResp" BU_SG_REL_ RDCM_HS SG_ 197 WRSLNDWhlDistTstm 1;
BA_REL_ "GenSigTimeoutMsg" BU_SG_REL_ RDCM_HS SG_ 197 WRSLNDWhlDistTstm 197;
BA_REL_ "GenSigTimeoutTime" BU_SG_REL_ RDCM_HS SG_ 197 WRSLNDWhlDistTstm 250;
BA_REL_ "GenSigSuprvResp" BU_SG_REL_ BCM_HS SG_ 197 WRSLNDWhlDistTstm 1;
BA_REL_ "GenSigTimeoutMsg" BU_SG_REL_ BCM_HS SG_ 197 WRSLNDWhlDistTstm 197;
BA_REL_ "GenSigTimeoutTime" BU_SG_REL_ BCM_HS SG_ 197 WRSLNDWhlDistTstm 250;
BA_REL_ "GenSigSuprvResp" BU_SG_REL_ TCCM_HS SG_ 197 WRSLNDWhlDistTstm 1;
BA_REL_ "GenSigTimeoutMsg" BU_SG_REL_ TCCM_HS SG_ 197 WRSLNDWhlDistTstm 197;
BA_REL_ "GenSigTimeoutTime" BU_SG_REL_ TCCM_HS SG_ 197 WRSLNDWhlDistTstm 25;
BA_REL_ "GenSigSuprvResp" BU_SG_REL_ PTO_HS SG_ 197 WRSLNDWhlDistPCntr 1;
BA_REL_ "GenSigTimeoutMsg" BU_SG_REL_ PTO_HS SG_ 197 WRSLNDWhlDistPCntr 197;
BA_REL_ "GenSigTimeoutTime" BU_SG_REL_ PTO_HS SG_ 197 WRSLNDWhlDistPCntr 250;
BA_REL_ "GenSigSuprvResp" BU_SG_REL_ HCP_HS SG_ 197 WRSLNDWhlDistPCntr 1;
BA_REL_ "GenSigTimeoutMsg" BU_SG_REL_ HCP_HS SG_ 197 WRSLNDWhlDistPCntr 197;
BA_REL_ "GenSigTimeoutTime" BU_SG_REL_ HCP_HS SG_ 197 WRSLNDWhlDistPCntr 250;
BA_REL_ "GenSigSuprvResp" BU_SG_REL_ HMIM_HS SG_ 197 WRSLNDWhlDistPCntr 1;
BA_REL_ "GenSigTimeoutMsg" BU_SG_REL_ HMIM_HS SG_ 197 WRSLNDWhlDistPCntr 197;
BA_REL_ "GenSigTimeoutTime" BU_SG_REL_ HMIM_HS SG_ 197 WRSLNDWhlDistPCntr 250;
BA_REL_ "GenSigSuprvResp" BU_SG_REL_ RDCM_HS SG_ 197 WRSLNDWhlDistPCntr 1;
BA_REL_ "GenSigTimeoutMsg" BU_SG_REL_ RDCM_HS SG_ 197 WRSLNDWhlDistPCntr 197;
BA_REL_ "GenSigTimeoutTime" BU_SG_REL_ RDCM_HS SG_ 197 WRSLNDWhlDistPCntr 250;
BA_REL_ "GenSigSuprvResp" BU_SG_REL_ BCM_HS SG_ 197 WRSLNDWhlDistPCntr 1;
BA_REL_ "GenSigTimeoutMsg" BU_SG_REL_ BCM_HS SG_ 197 WRSLNDWhlDistPCntr 197;
BA_REL_ "GenSigTimeoutTime" BU_SG_REL_ BCM_HS SG_ 197 WRSLNDWhlDistPCntr 250;
BA_REL_ "GenSigSuprvResp" BU_SG_REL_ TCCM_HS SG_ 197 WRSLNDWhlDistPCntr 1;
BA_REL_ "GenSigTimeoutMsg" BU_SG_REL_ TCCM_HS SG_ 197 WRSLNDWhlDistPCntr 197;
BA_REL_ "GenSigTimeoutTime" BU_SG_REL_ TCCM_HS SG_ 197 WRSLNDWhlDistPCntr 25;
BA_REL_ "GenSigSuprvResp" BU_SG_REL_ PTO_HS SG_ 197 WRSLNDSeqNum 1;
BA_REL_ "GenSigTimeoutMsg" BU_SG_REL_ PTO_HS SG_ 197 WRSLNDSeqNum 197;
BA_REL_ "GenSigTimeoutTime" BU_SG_REL_ PTO_HS SG_ 197 WRSLNDSeqNum 250;
BA_REL_ "GenSigSuprvResp" BU_SG_REL_ HCP_HS SG_ 197 WRSLNDSeqNum 1;
BA_REL_ "GenSigTimeoutMsg" BU_SG_REL_ HCP_HS SG_ 197 WRSLNDSeqNum 197;
BA_REL_ "GenSigTimeoutTime" BU_SG_REL_ HCP_HS SG_ 197 WRSLNDSeqNum 250;
BA_REL_ "GenSigSuprvResp" BU_SG_REL_ HMIM_HS SG_ 197 WRSLNDSeqNum 1;
BA_REL_ "GenSigTimeoutMsg" BU_SG_REL_ HMIM_HS SG_ 197 WRSLNDSeqNum 197;
BA_REL_ "GenSigTimeoutTime" BU_SG_REL_ HMIM_HS SG_ 197 WRSLNDSeqNum 250;
BA_REL_ "GenSigSuprvResp" BU_SG_REL_ RDCM_HS SG_ 197 WRSLNDSeqNum 1;
BA_REL_ "GenSigTimeoutMsg" BU_SG_REL_ RDCM_HS SG_ 197 WRSLNDSeqNum 197;
BA_REL_ "GenSigTimeoutTime" BU_SG_REL_ RDCM_HS SG_ 197 WRSLNDSeqNum 250;
BA_REL_ "GenSigSuprvResp" BU_SG_REL_ BCM_HS SG_ 197 WRSLNDSeqNum 1;
BA_REL_ "GenSigTimeoutMsg" BU_SG_REL_ BCM_HS SG_ 197 WRSLNDSeqNum 197;
BA_REL_ "GenSigTimeoutTime" BU_SG_REL_ BCM_HS SG_ 197 WRSLNDSeqNum 250;
BA_REL_ "GenSigSuprvResp" BU_SG_REL_ TCCM_HS SG_ 197 WRSLNDSeqNum 1;
BA_REL_ "GenSigTimeoutMsg" BU_SG_REL_ TCCM_HS SG_ 197 WRSLNDSeqNum 197;
BA_REL_ "GenSigTimeoutTime" BU_SG_REL_ TCCM_HS SG_ 197 WRSLNDSeqNum 25;
BA_REL_ "GenSigSuprvResp" BU_SG_REL_ PTO_HS SG_ 197 WRSRNDWhlDisTpRC 1;
BA_REL_ "GenSigTimeoutMsg" BU_SG_REL_ PTO_HS SG_ 197 WRSRNDWhlDisTpRC 197;
BA_REL_ "GenSigTimeoutTime" BU_SG_REL_ PTO_HS SG_ 197 WRSRNDWhlDisTpRC 250;
BA_REL_ "GenSigSuprvResp" BU_SG_REL_ HCP_HS SG_ 197 WRSRNDWhlDisTpRC 1;
BA_REL_ "GenSigTimeoutMsg" BU_SG_REL_ HCP_HS SG_ 197 WRSRNDWhlDisTpRC 197;
BA_REL_ "GenSigTimeoutTime" BU_SG_REL_ HCP_HS SG_ 197 WRSRNDWhlDisTpRC 250;
BA_REL_ "GenSigSuprvResp" BU_SG_REL_ RDCM_HS SG_ 197 WRSRNDWhlDisTpRC 1;
BA_REL_ "GenSigTimeoutMsg" BU_SG_REL_ RDCM_HS SG_ 197 WRSRNDWhlDisTpRC 197;
BA_REL_ "GenSigTimeoutTime" BU_SG_REL_ RDCM_HS SG_ 197 WRSRNDWhlDisTpRC 250;
BA_REL_ "GenSigSuprvResp" BU_SG_REL_ BCM_HS SG_ 197 WRSRNDWhlDisTpRC 1;
BA_REL_ "GenSigTimeoutMsg" BU_SG_REL_ BCM_HS SG_ 197 WRSRNDWhlDisTpRC 197;
BA_REL_ "GenSigTimeoutTime" BU_SG_REL_ BCM_HS SG_ 197 WRSRNDWhlDisTpRC 250;
BA_REL_ "GenSigSuprvResp" BU_SG_REL_ TCCM_HS SG_ 197 WRSRNDWhlDisTpRC 1;
BA_REL_ "GenSigTimeoutMsg" BU_SG_REL_ TCCM_HS SG_ 197 WRSRNDWhlDisTpRC 197;
BA_REL_ "GenSigTimeoutTime" BU_SG_REL_ TCCM_HS SG_ 197 WRSRNDWhlDisTpRC 25;
BA_REL_ "GenSigSuprvResp" BU_SG_REL_ PTO_HS SG_ 197 WRSRNDWhlRotStRst 1;
BA_REL_ "GenSigTimeoutMsg" BU_SG_REL_ PTO_HS SG_ 197 WRSRNDWhlRotStRst 197;
BA_REL_ "GenSigTimeoutTime" BU_SG_REL_ PTO_HS SG_ 197 WRSRNDWhlRotStRst 250;
BA_REL_ "GenSigSuprvResp" BU_SG_REL_ HCP_HS SG_ 197 WRSRNDWhlRotStRst 1;
BA_REL_ "GenSigTimeoutMsg" BU_SG_REL_ HCP_HS SG_ 197 WRSRNDWhlRotStRst 197;
BA_REL_ "GenSigTimeoutTime" BU_SG_REL_ HCP_HS SG_ 197 WRSRNDWhlRotStRst 250;
BA_REL_ "GenSigSuprvResp" BU_SG_REL_ RDCM_HS SG_ 197 WRSRNDWhlRotStRst 1;
BA_REL_ "GenSigTimeoutMsg" BU_SG_REL_ RDCM_HS SG_ 197 WRSRNDWhlRotStRst 197;
BA_REL_ "GenSigTimeoutTime" BU_SG_REL_ RDCM_HS SG_ 197 WRSRNDWhlRotStRst 250;
BA_REL_ "GenSigSuprvResp" BU_SG_REL_ BCM_HS SG_ 197 WRSRNDWhlRotStRst 1;
BA_REL_ "GenSigTimeoutMsg" BU_SG_REL_ BCM_HS SG_ 197 WRSRNDWhlRotStRst 197;
BA_REL_ "GenSigTimeoutTime" BU_SG_REL_ BCM_HS SG_ 197 WRSRNDWhlRotStRst 250;
BA_REL_ "GenSigSuprvResp" BU_SG_REL_ TCCM_HS SG_ 197 WRSRNDWhlRotStRst 1;
BA_REL_ "GenSigTimeoutMsg" BU_SG_REL_ TCCM_HS SG_ 197 WRSRNDWhlRotStRst 197;
BA_REL_ "GenSigTimeoutTime" BU_SG_REL_ TCCM_HS SG_ 197 WRSRNDWhlRotStRst 25;
BA_REL_ "GenSigSuprvResp" BU_SG_REL_ PTO_HS SG_ 197 WRSRNDWhlDistVal 1;
BA_REL_ "GenSigTimeoutMsg" BU_SG_REL_ PTO_HS SG_ 197 WRSRNDWhlDistVal 197;
BA_REL_ "GenSigTimeoutTime" BU_SG_REL_ PTO_HS SG_ 197 WRSRNDWhlDistVal 250;
BA_REL_ "GenSigSuprvResp" BU_SG_REL_ HCP_HS SG_ 197 WRSRNDWhlDistVal 1;
BA_REL_ "GenSigTimeoutMsg" BU_SG_REL_ HCP_HS SG_ 197 WRSRNDWhlDistVal 197;
BA_REL_ "GenSigTimeoutTime" BU_SG_REL_ HCP_HS SG_ 197 WRSRNDWhlDistVal 250;
BA_REL_ "GenSigSuprvResp" BU_SG_REL_ RDCM_HS SG_ 197 WRSRNDWhlDistVal 1;
BA_REL_ "GenSigTimeoutMsg" BU_SG_REL_ RDCM_HS SG_ 197 WRSRNDWhlDistVal 197;
BA_REL_ "GenSigTimeoutTime" BU_SG_REL_ RDCM_HS SG_ 197 WRSRNDWhlDistVal 250;
BA_REL_ "GenSigSuprvResp" BU_SG_REL_ BCM_HS SG_ 197 WRSRNDWhlDistVal 1;
BA_REL_ "GenSigTimeoutMsg" BU_SG_REL_ BCM_HS SG_ 197 WRSRNDWhlDistVal 197;
BA_REL_ "GenSigTimeoutTime" BU_SG_REL_ BCM_HS SG_ 197 WRSRNDWhlDistVal 250;
BA_REL_ "GenSigSuprvResp" BU_SG_REL_ TCCM_HS SG_ 197 WRSRNDWhlDistVal 1;
BA_REL_ "GenSigTimeoutMsg" BU_SG_REL_ TCCM_HS SG_ 197 WRSRNDWhlDistVal 197;
BA_REL_ "GenSigTimeoutTime" BU_SG_REL_ TCCM_HS SG_ 197 WRSRNDWhlDistVal 25;
BA_REL_ "GenSigSuprvResp" BU_SG_REL_ PTO_HS SG_ 197 WRSRNDWhlDistTstm 1;
BA_REL_ "GenSigTimeoutMsg" BU_SG_REL_ PTO_HS SG_ 197 WRSRNDWhlDistTstm 197;
BA_REL_ "GenSigTimeoutTime" BU_SG_REL_ PTO_HS SG_ 197 WRSRNDWhlDistTstm 250;
BA_REL_ "GenSigSuprvResp" BU_SG_REL_ HCP_HS SG_ 197 WRSRNDWhlDistTstm 1;
BA_REL_ "GenSigTimeoutMsg" BU_SG_REL_ HCP_HS SG_ 197 WRSRNDWhlDistTstm 197;
BA_REL_ "GenSigTimeoutTime" BU_SG_REL_ HCP_HS SG_ 197 WRSRNDWhlDistTstm 250;
BA_REL_ "GenSigSuprvResp" BU_SG_REL_ RDCM_HS SG_ 197 WRSRNDWhlDistTstm 1;
BA_REL_ "GenSigTimeoutMsg" BU_SG_REL_ RDCM_HS SG_ 197 WRSRNDWhlDistTstm 197;
BA_REL_ "GenSigTimeoutTime" BU_SG_REL_ RDCM_HS SG_ 197 WRSRNDWhlDistTstm 250;
BA_REL_ "GenSigSuprvResp" BU_SG_REL_ BCM_HS SG_ 197 WRSRNDWhlDistTstm 1;
BA_REL_ "GenSigTimeoutMsg" BU_SG_REL_ BCM_HS SG_ 197 WRSRNDWhlDistTstm 197;
BA_REL_ "GenSigTimeoutTime" BU_SG_REL_ BCM_HS SG_ 197 WRSRNDWhlDistTstm 250;
BA_REL_ "GenSigSuprvResp" BU_SG_REL_ TCCM_HS SG_ 197 WRSRNDWhlDistTstm 1;
BA_REL_ "GenSigTimeoutMsg" BU_SG_REL_ TCCM_HS SG_ 197 WRSRNDWhlDistTstm 197;
BA_REL_ "GenSigTimeoutTime" BU_SG_REL_ TCCM_HS SG_ 197 WRSRNDWhlDistTstm 25;
BA_REL_ "GenSigSuprvResp" BU_SG_REL_ PTO_HS SG_ 197 WRSRNDWhlDistPCntr 1;
BA_REL_ "GenSigTimeoutMsg" BU_SG_REL_ PTO_HS SG_ 197 WRSRNDWhlDistPCntr 197;
BA_REL_ "GenSigTimeoutTime" BU_SG_REL_ PTO_HS SG_ 197 WRSRNDWhlDistPCntr 250;
BA_REL_ "GenSigSuprvResp" BU_SG_REL_ HCP_HS SG_ 197 WRSRNDWhlDistPCntr 1;
BA_REL_ "GenSigTimeoutMsg" BU_SG_REL_ HCP_HS SG_ 197 WRSRNDWhlDistPCntr 197;
BA_REL_ "GenSigTimeoutTime" BU_SG_REL_ HCP_HS SG_ 197 WRSRNDWhlDistPCntr 250;
BA_REL_ "GenSigSuprvResp" BU_SG_REL_ RDCM_HS SG_ 197 WRSRNDWhlDistPCntr 1;
BA_REL_ "GenSigTimeoutMsg" BU_SG_REL_ RDCM_HS SG_ 197 WRSRNDWhlDistPCntr 197;
BA_REL_ "GenSigTimeoutTime" BU_SG_REL_ RDCM_HS SG_ 197 WRSRNDWhlDistPCntr 250;
BA_REL_ "GenSigSuprvResp" BU_SG_REL_ BCM_HS SG_ 197 WRSRNDWhlDistPCntr 1;
BA_REL_ "GenSigTimeoutMsg" BU_SG_REL_ BCM_HS SG_ 197 WRSRNDWhlDistPCntr 197;
BA_REL_ "GenSigTimeoutTime" BU_SG_REL_ BCM_HS SG_ 197 WRSRNDWhlDistPCntr 250;
BA_REL_ "GenSigSuprvResp" BU_SG_REL_ TCCM_HS SG_ 197 WRSRNDWhlDistPCntr 1;
BA_REL_ "GenSigTimeoutMsg" BU_SG_REL_ TCCM_HS SG_ 197 WRSRNDWhlDistPCntr 197;
BA_REL_ "GenSigTimeoutTime" BU_SG_REL_ TCCM_HS SG_ 197 WRSRNDWhlDistPCntr 25;
BA_REL_ "GenSigSuprvResp" BU_SG_REL_ PTO_HS SG_ 197 WRSRNDSeqNum 1;
BA_REL_ "GenSigTimeoutMsg" BU_SG_REL_ PTO_HS SG_ 197 WRSRNDSeqNum 197;
BA_REL_ "GenSigTimeoutTime" BU_SG_REL_ PTO_HS SG_ 197 WRSRNDSeqNum 250;
BA_REL_ "GenSigSuprvResp" BU_SG_REL_ HCP_HS SG_ 197 WRSRNDSeqNum 1;
BA_REL_ "GenSigTimeoutMsg" BU_SG_REL_ HCP_HS SG_ 197 WRSRNDSeqNum 197;
BA_REL_ "GenSigTimeoutTime" BU_SG_REL_ HCP_HS SG_ 197 WRSRNDSeqNum 250;
BA_REL_ "GenSigSuprvResp" BU_SG_REL_ RDCM_HS SG_ 197 WRSRNDSeqNum 1;
BA_REL_ "GenSigTimeoutMsg" BU_SG_REL_ RDCM_HS SG_ 197 WRSRNDSeqNum 197;
BA_REL_ "GenSigTimeoutTime" BU_SG_REL_ RDCM_HS SG_ 197 WRSRNDSeqNum 250;
BA_REL_ "GenSigSuprvResp" BU_SG_REL_ BCM_HS SG_ 197 WRSRNDSeqNum 1;
BA_REL_ "GenSigTimeoutMsg" BU_SG_REL_ BCM_HS SG_ 197 WRSRNDSeqNum 197;
BA_REL_ "GenSigTimeoutTime" BU_SG_REL_ BCM_HS SG_ 197 WRSRNDSeqNum 250;
BA_REL_ "GenSigSuprvResp" BU_SG_REL_ TCCM_HS SG_ 197 WRSRNDSeqNum 1;
BA_REL_ "GenSigTimeoutMsg" BU_SG_REL_ TCCM_HS SG_ 197 WRSRNDSeqNum 197;
BA_REL_ "GenSigTimeoutTime" BU_SG_REL_ TCCM_HS SG_ 197 WRSRNDSeqNum 25;
BA_REL_ "GenSigSuprvResp" BU_SG_REL_ EBCM_OBD_HS SG_ 249 TrnsOtptRotRC 1;
BA_REL_ "GenSigTimeoutMsg" BU_SG_REL_ EBCM_OBD_HS SG_ 249 TrnsOtptRotRC 249;
BA_REL_ "GenSigTimeoutTime" BU_SG_REL_ EBCM_OBD_HS SG_ 249 TrnsOtptRotRC 250;
BA_REL_ "GenSigSuprvResp" BU_SG_REL_ EBCM_HS SG_ 249 TrnsOtptRotRC 1;
BA_REL_ "GenSigTimeoutMsg" BU_SG_REL_ EBCM_HS SG_ 249 TrnsOtptRotRC 249;
BA_REL_ "GenSigTimeoutTime" BU_SG_REL_ EBCM_HS SG_ 249 TrnsOtptRotRC 250;
BA_REL_ "GenSigSuprvResp" BU_SG_REL_ EBCM_OBD_HS SG_ 249 TrnsOtptRotRCRstOcc 1;
BA_REL_ "GenSigTimeoutMsg" BU_SG_REL_ EBCM_OBD_HS SG_ 249 TrnsOtptRotRCRstOcc 249;
BA_REL_ "GenSigTimeoutTime" BU_SG_REL_ EBCM_OBD_HS SG_ 249 TrnsOtptRotRCRstOcc 250;
BA_REL_ "GenSigSuprvResp" BU_SG_REL_ EBCM_HS SG_ 249 TrnsOtptRotRCRstOcc 1;
BA_REL_ "GenSigTimeoutMsg" BU_SG_REL_ EBCM_HS SG_ 249 TrnsOtptRotRCRstOcc 249;
BA_REL_ "GenSigTimeoutTime" BU_SG_REL_ EBCM_HS SG_ 249 TrnsOtptRotRCRstOcc 250;
BA_REL_ "GenSigSuprvResp" BU_SG_REL_ EBCM_OBD_HS SG_ 249 TrnsOutShftAngVel 1;
BA_REL_ "GenSigTimeoutMsg" BU_SG_REL_ EBCM_OBD_HS SG_ 249 TrnsOutShftAngVel 249;
BA_REL_ "GenSigTimeoutTime" BU_SG_REL_ EBCM_OBD_HS SG_ 249 TrnsOutShftAngVel 250;
BA_REL_ "GenSigSuprvResp" BU_SG_REL_ EBCM_HS SG_ 249 TrnsOutShftAngVel 1;
BA_REL_ "GenSigTimeoutMsg" BU_SG_REL_ EBCM_HS SG_ 249 TrnsOutShftAngVel 249;
BA_REL_ "GenSigTimeoutTime" BU_SG_REL_ EBCM_HS SG_ 249 TrnsOutShftAngVel 250;
BA_REL_ "GenSigSuprvResp" BU_SG_REL_ TCCM_HS SG_ 249 TrnsOutShftAngVel 1;
BA_REL_ "GenSigTimeoutMsg" BU_SG_REL_ TCCM_HS SG_ 249 TrnsOutShftAngVel 249;
BA_REL_ "GenSigTimeoutTime" BU_SG_REL_ TCCM_HS SG_ 249 TrnsOutShftAngVel 250;
BA_REL_ "GenSigVBitResp" BU_SG_REL_ RDCM_HS SG_ 249 TrnsOvrallEstTorqRatio 1;
BA_REL_ "GenSigSuprvResp" BU_SG_REL_ RDCM_HS SG_ 249 TrnsOvrallEstTorqRatio 1;
BA_REL_ "GenSigTimeoutMsg" BU_SG_REL_ RDCM_HS SG_ 249 TrnsOvrallEstTorqRatio 249;
BA_REL_ "GenSigTimeoutTime" BU_SG_REL_ RDCM_HS SG_ 249 TrnsOvrallEstTorqRatio 250;
VAL_ 493 EngRunng 1 "true" 0 "false" ;
VAL_ 493 FlPmpEDscOtptCmdSta 1 "Fuel Pump Enabled" 0 "Fuel Pump Disabled" ;
VAL_ 493 FuelCntlSysFltPrsnt 1 "true" 0 "false" ;
VAL_ 401 EngTrqTrnRqTmpFld 1 "true" 0 "false" ;
VAL_ 401 EngTrqTrnRqLmtd 1 "true" 0 "false" ;
VAL_ 401 TrnsEngSpdReqFld 1 "true" 0 "false" ;
VAL_ 401 EngTrqTnsRqFld 1 "true" 0 "false" ;
VAL_ 401 EngTrqRdnFld 1 "true" 0 "false" ;
VAL_ 401 EngNTrnsRegStdyStTqV 1 "Invalid" 0 "Valid" ;
VAL_ 401 EngAirflwStdyStTorqV 1 "Invalid" 0 "Valid" ;
VAL_ 401 AccKdwnAtv 1 "true" 0 "false" ;
VAL_ 401 AccPosV 1 "Invalid" 0 "Valid" ;
VAL_ 401 EngActStdyStTorqV 1 "Invalid" 0 "Valid" ;
VAL_ 707 CSTATRS_ReqStat 6 "Control System Failure Permanent" 5 "Control System Failure Temporary" 4 "Serial Data Failure Permanent" 3 "Serial Data Failure Temporary" 2 "Lost Arbitration" 1 "Request Honored" 0 "No Request" ;
VAL_ 707 CSTATRS_LmtgStat 3 "Rate and Value Limited" 2 "Value Limited" 1 "Rate Limited" 0 "Not Limited" ;
VAL_ 707 EngManfldAbsPrsV 1 "Invalid" 0 "Valid" ;
VAL_ 707 EngTrqMinExtRngV 1 "Invalid" 0 "Valid" ;
VAL_ 707 EngTrqMaxExtRngV 1 "Invalid" 0 "Valid" ;
VAL_ 1265 PTSysHzrdLghtReq 1 "true" 0 "false" ;
VAL_ 1265 EngOffTmPTV 1 "Invalid" 0 "Valid" ;
VAL_ 1265 EngOffTmPTM 1 "Use Data" 0 "Don't Use Data" ;
VAL_ 417 EngCrsCntrlMode 5 "Tap" 4 "Coast" 3 "Accel" 2 "Resume" 1 "Engaged" 0 "Inactive" ;
VAL_ 417 EngPstOxgSnsDgAstRq 1 "true" 0 "false" ;
VAL_ 417 CrsCtrlCnstSpdAct 1 "true" 0 "false" ;
VAL_ 417 WrmUpShftPtrnRq 1 "Active" 0 "Inactive" ;
VAL_ 417 EngAlwCltAdp 1 "true" 0 "false" ;
VAL_ 417 AccPdlPosPcntFullRngV 1 "Invalid" 0 "Valid" ;
VAL_ 417 DslPrtFltrIdlRgtnMdReq 1 "true" 0 "false" ;
VAL_ 417 DslPartFltrClngAlgActM 1 "Use Data" 0 "Don't Use Data" ;
VAL_ 417 DslPartFltrClngAlgAct 1 "true" 0 "false" ;
VAL_ 417 EngCylDeactMd 3 "Reactivation In Progress" 2 "Half of Total Cylinders Active" 1 "Deactivation In Progress" 0 "All Cylinders Active" ;
VAL_ 417 ACCmCltEngd 1 "true" 0 "false" ;
VAL_ 417 ParkNeutralSwStatV 1 "Invalid" 0 "Valid" ;
VAL_ 417 ParkNeutralSwStat 1 "Not Park/Neutral" 0 "Park/Neutral" ;
VAL_ 417 EngColdHiIdleActive 1 "true" 0 "false" ;
VAL_ 417 EngCyDactTqSmtAct 1 "true" 0 "false" ;
VAL_ 417 EngBrkStat 2 "Active Absorbing Torque" 1 "Active Not Absorbing Torque" 0 "Inactive" ;
VAL_ 417 TracCntlSysPwrtrnInhbt 1 "true" 0 "false" ;
VAL_ 417 EngMtlProtAtv 1 "true" 0 "false" ;
VAL_ 417 EngDgTrqCnvClUnlkRqd 1 "true" 0 "false" ;
VAL_ 417 EngCyldrDeactReqd 1 "true" 0 "false" ;
VAL_ 417 ETGRReqdGear 8 "Eighth Gear" 7 "Seventh Gear" 6 "Sixth Gear" 5 "Fifth Gear" 4 "Fourth Gear" 3 "Third Gear" 2 "Second Gear" 1 "First Gear" 0 "No Action" ;
VAL_ 417 ETGRReqType 0 "No Action" 3 "Hold Gear" 2 "Min Gear Request" 1 "Max Gear Request" ;
VAL_ 1233 EngShtdwnAct 1 "true" 0 "false" ;
VAL_ 1233 EngShtdwnPndgIO 1 "true" 0 "false" ;
VAL_ 1233 FuelFltChgNwIO 1 "true" 0 "false" ;
VAL_ 1233 PTExPrtclFltrWrn2IO 1 "true" 0 "false" ;
VAL_ 1233 PTHiElecLdReqd 1 "true" 0 "false" ;
VAL_ 1233 PTExPrtclFltrWrnIO 1 "true" 0 "false" ;
VAL_ 1233 AirCndOffIO 1 "true" 0 "false" ;
VAL_ 1233 DslGlwPlgIO 1 "true" 0 "false" ;
VAL_ 1233 StgDisIO 1 "true" 0 "false" ;
VAL_ 1233 RdcdPwrIO 1 "true" 0 "false" ;
VAL_ 1233 FlLvlPctV 1 "Invalid" 0 "Valid" ;
VAL_ 1233 EngWtrInFlIO 1 "true" 0 "false" ;
VAL_ 1233 EngOilTmpV 1 "Invalid" 0 "Valid" ;
VAL_ 1233 EngOilPrsV 1 "Invalid" 0 "Valid" ;
VAL_ 1233 EngOilPrsLwIO 1 "true" 0 "false" ;
VAL_ 1233 EngOilLvlLwIO 1 "true" 0 "false" ;
VAL_ 1233 EngOilChngIO 1 "true" 0 "false" ;
VAL_ 1233 EngHt_StpEngIO 1 "true" 0 "false" ;
VAL_ 1233 EngHotFuelEnrchmntIO 1 "true" 0 "false" ;
VAL_ 1233 CkFlFilrCapIO 1 "true" 0 "false" ;
VAL_ 1217 LegPstDTCClrDrvCyCm 1 "true" 0 "false" ;
VAL_ 1217 LegDiagColdStCndMet 1 "true" 0 "false" ;
VAL_ 1217 LegDiagColdStCndFltPr 1 "true" 0 "false" ;
VAL_ 1217 EngEconMdCmnd 1 "true" 0 "false" ;
VAL_ 1217 DslExhFldRmngDstHRsV 1 "Invalid" 0 "Valid" ;
VAL_ 1217 EngOilHotIO 1 "true" 0 "false" ;
VAL_ 1217 OAT_PT_EstV 1 "Invalid" 0 "Valid" ;
VAL_ 1217 LegDiagStndCndMet 1 "true" 0 "false" ;
VAL_ 1217 LegDiagStndCndFltPr 1 "true" 0 "false" ;
VAL_ 1217 OAT_PT_EstM 1 "Use Data" 0 "Don't Use Data" ;
VAL_ 1217 EngWrmUpAch 1 "true" 0 "false" ;
VAL_ 1217 EngIntAirTmpV 1 "Invalid" 0 "Valid" ;
VAL_ 1217 EngCltTmpV 1 "Invalid" 0 "Valid" ;
VAL_ 1217 BarPrsAbsV 1 "Invalid" 0 "Valid" ;
VAL_ 985 EDADS_RcmndtFwdGr 15 "Unused and Reserved 7" 14 "Unused and Reserved 6" 13 "Unused and Reserved 5" 12 "Unused and Reserved 4" 11 "Unused and Reserved 3" 10 "Unused and Reserved 2" 9 "Unused and Reserved 1" 8 "Eighth Gear" 7 "Seventh Gear" 6 "Sixth Gear" 5 "Fifth Gear" 4 "Fourth Gear" 3 "Third Gear" 2 "Second Gear" 1 "First Gear" 0 "None" ;
VAL_ 985 EDADS_CrntFwdMsdG 15 "Unused and Reserved 7" 14 "Unused and Reserved 6" 13 "Unused and Reserved 5" 12 "Unused and Reserved 4" 11 "Unused and Reserved 3" 10 "Unused and Reserved 2" 9 "Unused and Reserved 1" 8 "Eighth Gear" 7 "Seventh Gear" 6 "Sixth Gear" 5 "Fifth Gear" 4 "Fourth Gear" 3 "Third Gear" 2 "Second Gear" 1 "First Gear" 0 "None" ;
VAL_ 985 EDADS_ShftIndStat 2 "No Shift" 1 "Shift Up" 0 "Shift Down" ;
VAL_ 985 EDADS_EcoDrvShftIO 1 "true" 0 "false" ;
VAL_ 1017 ACRfHiSdFldPrsV 1 "Invalid" 0 "Valid" ;
VAL_ 1017 GenStptDtCycPtOvrAct 1 "true" 0 "false" ;
VAL_ 1017 VehTopSpdLmtMdAct 1 "true" 0 "false" ;
VAL_ 1017 GenFldDutCycV 1 "Invalid" 0 "Valid" ;
VAL_ 1017 GenFld 1 "true" 0 "false" ;
VAL_ 1017 FlInjRlCtRstOcc 1 "true" 0 "false" ;
VAL_ 1017 EngSpdLmtnMdAct 1 "true" 0 "false" ;
VAL_ 977 AutoMdSpdLmtStat 0 "No Speed Limit Change" 1 "Proposed Speed Limit Change" 2 "Accepted Speed Limit Change" 3 "Declined Speed Limit Change" ;
VAL_ 977 FuelFltLifRstPerf 1 "true" 0 "false" ;
VAL_ 977 SpdLmtrSpdWrngAct 1 "true" 0 "false" ;
VAL_ 977 CrsCntlDrSelSpdAct 1 "true" 0 "false" ;
VAL_ 977 ACCompCmnd 1 "On" 0 "Off" ;
VAL_ 977 EngBstPrsIndV 1 "Invalid" 0 "Valid" ;
VAL_ 977 EngOilLifRstPerf 1 "true" 0 "false" ;
VAL_ 977 ThrPosV 1 "Invalid" 0 "Valid" ;
VAL_ 977 EngOilStrvtnIO 1 "true" 0 "false" ;
VAL_ 977 EngNEmsnsRelMalfAct 1 "true" 0 "false" ;
VAL_ 977 EngEmsRelMalfIndReq 4 "Flashing 0.5 Hertz Indication" 3 "Flashing 2 Hertz Indication" 2 "Flashing 1 Hertz Indication" 1 "No Indication" 0 "Continuous Indication" ;
VAL_ 977 EngCstFlCutAct 1 "true" 0 "false" ;
VAL_ 201 PrsElvtdIdlCntlStat 1 "Enabled" 0 "Disabled" ;
VAL_ 201 Eng12vStrtrMtrCmmdOn 1 "true" 0 "false" ;
VAL_ 201 EngCntrlRunCrnkTrmSt 1 "Active" 0 "Inactive" ;
VAL_ 201 EngAirIntBstPrV 1 "Invalid" 0 "Valid" ;
VAL_ 201 SpdLmtrSpdWrngEnbld 1 "true" 0 "false" ;
VAL_ 201 EngCylDactEvntPndg 1 "true" 0 "false" ;
VAL_ 201 EngCylDeactMd 3 "Reactivation In Progress" 2 "Half of Total Cylinders Active" 1 "Deactivation In Progress" 0 "All Cylinders Active" ;
VAL_ 201 RmVhStrtEngRng 1 "true" 0 "false" ;
VAL_ 201 PFEngSpdCmndSpcd 1 "true" 0 "false" ;
VAL_ 201 PltfrmEngSpdCmdInhtRq 1 "Inhibit Platform Eng. Speed Control" 0 "Allow Platform Engine Speed Control" ;
VAL_ 201 PT_BrkPedDscrtInpStatV 1 "Invalid" 0 "Valid" ;
VAL_ 201 PT_BrkPedDscrtInpStat 1 "Brake Applied" 0 "Brake Not Applied" ;
VAL_ 201 CrsCntEnbld 1 "true" 0 "false" ;
VAL_ 201 CrsCntAtv 1 "true" 0 "false" ;
VAL_ 201 DrvThrottlOvrrdDet 1 "true" 0 "false" ;
VAL_ 201 PT_CrnkAct 1 "true" 0 "false" ;
VAL_ 201 PTRunAbrt 1 "true" 0 "false" ;
VAL_ 201 PTO_PT_RunAbrtd 1 "true" 0 "false" ;
VAL_ 201 PTCrnkAbrted 1 "true" 0 "false" ;
VAL_ 201 EngSpdStat 3 "Invalid" 1 "Degraded Operation" 0 "Normal Operation" ;
VAL_ 201 EngRunAtv 1 "true" 0 "false" ;
VAL_ 201 EngIdlAtv 1 "true" 0 "false" ;
VAL_ 201 AccActPosV 1 "Invalid" 0 "Valid" ;
VAL_ 501 EngRecDwnshftIO 1 "true" 0 "false" ;
VAL_ 501 TrnsPattSelEcnMdOCm 1 "true" 0 "false" ;
VAL_ 501 CltStartSwAtvV 1 "Invalid" 0 "Valid" ;
VAL_ 501 CltStartSwAtv 1 "true" 0 "false" ;
VAL_ 501 CltchPdlActPosV 1 "Invalid" 0 "Valid" ;
VAL_ 501 TrnsEngdStateV 1 "Invalid" 0 "Valid" ;
VAL_ 501 TrnsEngdState 3 "Operating State Not Reached" 2 "Transmission Engaged in Reverse" 1 "Transmission Engaged in Forward" 0 "Transmission Not Engaged" ;
VAL_ 501 TrnsShftLvrLckRqd 1 "true" 0 "false" ;
VAL_ 501 TransTUDMdStat 2 "Electronic Range Select Active" 1 "Driver Shift Control Active" 0 "No Activation" ;
VAL_ 501 TrnCrpMdAtv 1 "true" 0 "false" ;
VAL_ 501 TrnsSkpShftIO 1 "true" 0 "false" ;
VAL_ 501 TrnsSftMdStat 3 "Automatic Grade Braking Mode" 2 "Lift-Foot Cornering Mode" 1 "Performance Mode" 0 "No Override Mode" ;
VAL_ 501 TrnsRngInhbtStat 4 "Diagnostic Inhibit Active" 3 "Driveline Not Engaged" 2 "Transmission Range Re-Selection Req" 1 "Transmission Inhibit Active" 0 "No Range Inhibit Active" ;
VAL_ 501 TopTrvlCltchSwActV 1 "Invalid" 0 "Valid" ;
VAL_ 501 TopTrvlCltchSwAct 1 "true" 0 "false" ;
VAL_ 501 EngRecmndUpshftIO 1 "true" 0 "false" ;
VAL_ 501 DrvtShftCntrlTrgtGear 8 "Eighth Gear" 7 "Seventh Gear" 6 "Sixth Gear" 5 "Fifth Gear" 4 "Fourth Gear" 3 "Third Gear" 2 "Second Gear" 1 "First Gear" 0 "Not Supported" ;
VAL_ 501 DrShftCntrlReqDndIO 1 "true" 0 "false" ;
VAL_ 501 TrnShftPtrnActStat 6 "PT Protection Pattern Active" 5 "PT Non-Protection Pattern Active" 4 "Shift Pattern 4 Active" 3 "Shift Pattern 3 Active" 2 "Shift Pattern 2 Active" 1 "Shift Pattern 1 Active" 0 "Default Shift Pattern Active" ;
VAL_ 501 TrnsFldPrsPrsnt 1 "true" 0 "false" ;
VAL_ 501 TrnsShftLvrPos 15 "Lever Position Unknown" 11 "Forward Range H" 10 "Forward Range G" 9 "Forward Range F" 8 "Forward Range E" 7 "Forward Range D" 6 "Forward Range C" 5 "Forward Range B" 4 "Forward Range A" 3 "Neutral Range" 2 "Reverse Range" 1 "Park Range" 0 "Between Ranges" ;
VAL_ 501 TrnsShftLvrPosV 1 "Invalid" 0 "Valid" ;
VAL_ 501 TrnsTrqCnvCltCmndMd 7 "Not Supported" 3 "Locked" 2 "Controlled Slip" 1 "Transitioning" 0 "Unlocked" ;
VAL_ 501 AutoTransComndGear 15 "Park Gear" 14 "Reverse Gear" 13 "Neutral Gear" 12 "CVT Forward Gear" 11 "EVT Mode 2" 10 "EVT Mode 1" 8 "Eighth Gear" 7 "Seventh Gear" 6 "Sixth Gear" 5 "Fifth Gear" 4 "Fourth Gear" 3 "Third Gear" 2 "Second Gear" 1 "First Gear" 0 "Not Supported" ;
VAL_ 501 AutoTransGrSftDirect 2 "Downshift in Progress" 1 "Upshift in Progress" 0 "No Shift in Progress" ;
VAL_ 501 TransEstGear 15 "Park Gear" 14 "Reverse Gear" 13 "Neutral Gear" 12 "CVT Forward Gear" 11 "EVT Mode 2" 10 "EVT Mode 1" 8 "Eighth Gear" 7 "Seventh Gear" 6 "Sixth Gear" 5 "Fifth Gear" 4 "Fourth Gear" 3 "Third Gear" 2 "Second Gear" 1 "First Gear" 0 "Not Supported" ;
VAL_ 501 TransEstGearV 1 "Invalid" 0 "Valid" ;
VAL_ 1225 TCTPIR_DrvNotfn 15 "Indication 15" 14 "Indication 14" 13 "Indication 13" 12 "Indication 12" 11 "Indication 11" 10 "Indication 10" 9 "Indication 9" 8 "Indication 8" 7 "Indication 7" 6 "Indication 6" 5 "Indication 5" 4 "Indication 4" 3 "Indication 3" 2 "Indication 2" 1 "Indication 1" 0 "No Indication" ;
VAL_ 1225 GrdBrkgAct 1 "true" 0 "false" ;
VAL_ 1225 RrPTCoolFanRatFltStat 0 "Indeterminate" 1 "Pass" 2 "Fail" 3 "Reserved and Unused" ;
VAL_ 1225 TrnsThrmlMngmntStat 2 "Driver Intervention Requested" 1 "Countermeasures Active" 0 "Normal" ;
VAL_ 1225 TrnsNEmsRltMalfActv 1 "true" 0 "false" ;
VAL_ 1225 TransOilTempSensPres 1 "true" 0 "false" ;
VAL_ 1225 TrnEmsMlfAtv 1 "true" 0 "false" ;
VAL_ 1225 TrnOilTmpV 1 "Invalid" 0 "Valid" ;
VAL_ 1225 TERDTC_SysDes 15 "U3-Network Codes Reserved" 14 "U2-Network Codes Reserved" 13 "U1-Network Codes MFG Controlled" 12 "U0-Network Codes SAE Controlled" 11 "B3-Body Codes Reserved" 10 "B2-Body Codes Reserved" 9 "B1-Body Codes MFG Controlled" 8 "B0-Body Codes SAE Controlled" 7 "C3-Chassis Codes Reserved" 6 "C2-Chassis Codes Reserved" 5 "C1-Chassis Codes MFG Controlled" 4 "C0-Chassis Codes SAE Controlled" 3 "P3-Powertrain Codes Reserved" 2 "P2-Powertrain Codes Reserved" 1 "P1-Powertrain Codes MFG Controlled" 0 "P0-Powertrain Codes SAE Controlled" ;
VAL_ 409 TDslPrtFltrIdlRgtnMdAtv 1 "true" 0 "false" ;
VAL_ 409 TTRLT_TqRdnRlznSgg 3 "Stability Optimized 2" 2 "Stability Optimized 1" 1 "Transient Optimized" 0 "No Suggestion" ;
VAL_ 409 TTRLT_TorqInvntnTyp 2 "Minimum Limit" 1 "Maximum Limit" 0 "No Intervention" ;
VAL_ 409 TTRST_TorqInvntnTyp 1 "Maximum Limit" 0 "No Intervention" ;
VAL_ 413 TrnsCyDactTransStat 2 "Ready for Half of TotalCylinders" 1 "Ready for All Cylinders" 0 "Not Ready" ;
VAL_ 413 EngBrkDsblReqd 1 "true" 0 "false" ;
VAL_ 413 TransNtrlCntrlMdStat 3 "Exiting Neutral Control" 2 "Neutral Control Active" 1 "Entering Neutral Control" 0 "Neutral Control Not Active" ;
VAL_ 413 TrnsRtoCntlSysFlt 1 "true" 0 "false" ;
VAL_ 413 TrnTrbAngVlV 1 "Invalid" 0 "Valid" ;
VAL_ 413 TrnGrRatV 1 "Invalid" 0 "Valid" ;
VAL_ 413 TrnPrfAlgShfAtv 1 "true" 0 "false" ;
VAL_ 413 TESR_EngSpdCntlRsp 3 "Stability Optimized Condition 2" 2 "Stability Optimized Condition 1" 1 "Transient Optimized" 0 "No Suggestion" ;
VAL_ 413 TESR_EngSpdIntTyp 2 "Engine Speed Min Limit" 1 "Engine Speed Max Limit" 0 "No Intervention" ;
VAL_ 413 TrnsGrgShftAct 1 "true" 0 "false" ;
VAL_ 197 WRSLNDWhlRotStRst 1 "true" 0 "false" ;
VAL_ 197 WRSLNDWhlDistVal 1 "Invalid" 0 "Valid" ;
VAL_ 197 WRSRNDWhlRotStRst 1 "true" 0 "false" ;
VAL_ 197 WRSRNDWhlDistVal 1 "Invalid" 0 "Valid" ;
VAL_ 249 TrnsDrvlneTqShpDisRq 1 "true" 0 "false" ;
VAL_ 249 TrnsOtptRotRCRstOcc 1 "true" 0 "false" ;
VAL_ 249 TrnsOtptRotRCV 1 "Invalid" 0 "Valid" ;
VAL_ 249 TrnsOtptShftAngVelSnrPr 1 "true" 0 "false" ;
VAL_ 249 TrnsOutShftAngVelV 1 "Invalid" 0 "Valid" ;
VAL_ 249 TrnsOvrallEstTorqRatioV 1 "Invalid" 0 "Valid" ;
SIG_GROUP_ 707 ChsSysTtlAxleTrqRqSt 1 : CSTATRS_ReqStat CSTATRS_LmtgStat;
SIG_GROUP_ 417 EngTransGearReq 1 : ETGRReqdGear ETGRReqType;
SIG_GROUP_ 985 ECODrvAsstDsplyStat 1 : EDADS_RcmndtFwdGr EDADS_CrntFwdMsdG EDADS_ShftIndStat EDADS_EcoDrvShftIO;
SIG_GROUP_ 1225 TrnsCltchThrmlProtIndR 1 : TCTPIR_TnsEsClCDwT TCTPIR_TnsEsClTmpD TCTPIR_DrvNotfn;
SIG_GROUP_ 1225 TransEmsnsRelDTC 1 : TERDTC_SysDes TERDTC_CdNum;
SIG_GROUP_ 409 TransTorqReqLngTrm 1 : TTRLT_TorqReqVal TTRLT_TqRdnRlznSgg TTRLT_TorqInvntnTyp;
SIG_GROUP_ 409 TransTorqReqShrtTrm 1 : TTRST_TorqReqVal TTRST_TorqInvntnTyp;
SIG_GROUP_ 413 TrnsEngSpdRq 1 : TESR_EngSpdCntlRsp TESR_EngSpdRqVal TESR_EngSpdIntTyp;
SIG_GROUP_ 197 WhlRotStatLftNDrvn 1 : WRSLNDWhlDisTpRC WRSLNDWhlRotStRst WRSLNDWhlDistVal WRSLNDWhlDistTstm WRSLNDWhlDistPCntr WRSLNDSeqNum;
SIG_GROUP_ 197 WhlRotStatRghtNDrvn 1 : WRSRNDWhlDisTpRC WRSRNDWhlRotStRst WRSRNDWhlDistVal WRSRNDWhlDistTstm WRSRNDWhlDistPCntr WRSRNDSeqNum;
